BO_ 698 FR_CMR_04_40ms: 32 FR_CMR
 SG_ FR_CMR_Crc4Val : 0|16@1+ (1,0) [0|65535] "" Dummy
 SG_ FR_CMR_AlvCnt4Val : 16|8@1+ (1,0) [0|255] "" Dummy
 SG_ IFSref_FR_CMR_Sta : 24|2@1+ (1,0) [0|3] "" CGW
 SG_ IFSref_VehNumVal : 26|4@1+ (1,0) [0|15] "" CGW
 SG_ IFSref_ILLAmbtSta : 30|2@1+ (0.1,0) [0|0.3] "" CGW
 SG_ IFSref_VehLftAngl1Val : 32|9@1+ (0.1,-25) [-25|26.1] "Deg" CGW
 SG_ IFSref_VehRtAngl1Val : 41|9@1+ (0.1,-25) [-25|26.1] "Deg" CGW
 SG_ IFSref_VehLftAngl2Val : 50|9@1+ (0.1,-25) [-25|26.1] "Deg" CGW
 SG_ IFSref_VehDst1Val : 59|4@1+ (1,0) [0|15] "" CGW
 SG_ IFSref_VehRtAngl2Val : 64|9@1+ (0.1,-25) [-25|26.1] "Deg" CGW
 SG_ IFSref_VehLftAngl3Val : 73|9@1+ (0.1,-25) [-25|26.1] "Deg" CGW
 SG_ IFSref_VehRtAngl3Val : 82|9@1+ (0.1,-25) [-25|26.1] "Deg" CGW
 SG_ IFSref_VehLftAngl4Val : 91|9@1+ (0.1,-25) [-25|26.1] "Deg" CGW
 SG_ IFSref_VehRtAngl4Val : 100|9@1+ (0.1,-25) [-25|26.1] "Deg" CGW
 SG_ IFSref_VehLftAngl5Val : 109|9@1+ (0.1,-25) [-25|26.1] "Deg" CGW
 SG_ IFSref_VehRtAngl5Val : 118|9@1+ (0.1,-25) [-25|26.1] "Deg" CGW
 SG_ IFSref_VehLftAngl6Val : 128|9@1+ (0.1,-25) [-25|26.1] "Deg" CGW
 SG_ IFSref_VehRtAngl6Val : 137|9@1+ (0.1,-25) [-25|26.1] "Deg" CGW
 SG_ IFSref_VehLftAngl7Val : 146|9@1+ (0.1,-25) [-25|26.1] "Deg" CGW
 SG_ IFSref_VehRtAngl7Val : 155|9@1+ (0.1,-25) [-25|26.1] "Deg" CGW
 SG_ IFSref_VehLftAngl8Val : 164|9@1+ (0.1,-25) [-25|26.1] "Deg" CGW
 SG_ IFSref_VehRtAngl8Val : 173|9@1+ (0.1,-25) [-25|26.1] "Deg" CGW
 SG_ IFSref_VehLftAngl9Val : 182|9@1+ (0.1,-25) [-25|26.1] "Deg" CGW
 SG_ IFSref_VehRtAngl9Val : 192|9@1+ (0.1,-25) [-25|26.1] "Deg" CGW
 SG_ IFSref_VehLftAngl10Val : 201|9@1+ (0.1,-25) [-25|26.1] "Deg" CGW
 SG_ IFSref_VehRtAngl10Val : 210|9@1+ (0.1,-25) [-25|26.1] "Deg" CGW
 SG_ IFSref_VehDst2Val : 219|4@1+ (1,0) [0|15] "" CGW
 SG_ IFSref_VehDst3Val : 223|4@1+ (1,0) [0|15] "" CGW
 SG_ IFSref_VehDst4Val : 227|4@1+ (1,0) [0|15] "" CGW
 SG_ IFSref_VehDst5Val : 231|4@1+ (1,0) [0|15] "" CGW
 SG_ IFSref_VehDst6Val : 235|4@1+ (1,0) [0|15] "" CGW
 SG_ IFSref_VehDst7Val : 239|4@1+ (1,0) [0|15] "" CGW
 SG_ IFSref_VehDst8Val : 243|4@1+ (1,0) [0|15] "" CGW
 SG_ IFSref_VehDst9Val : 247|4@1+ (1,0) [0|15] "" CGW
 SG_ IFSref_VehDst10Val : 251|4@1+ (1,0) [0|15] "" CGW

BO_ 736 MANUAL_SPEED_LIMIT_ASSIST: 32 XXX
 SG_ CHECKSUM : 0|16@1+ (1,0) [0|65535] "" XXX
 SG_ COUNTER : 16|8@1+ (1,0) [0|255] "" XXX
 SG_ MSLA_STATUS : 26|2@1+ (1,0) [0|3] "" XXX
 SG_ MSLA_ENABLED : 38|1@1+ (1,0) [0|1] "" XXX
 SG_ MAX_SPEED : 55|8@0+ (1,0) [0|255] "" XXX
 SG_ MAX_SPEED_COPY : 144|8@1+ (1,0) [0|255] "" XXX

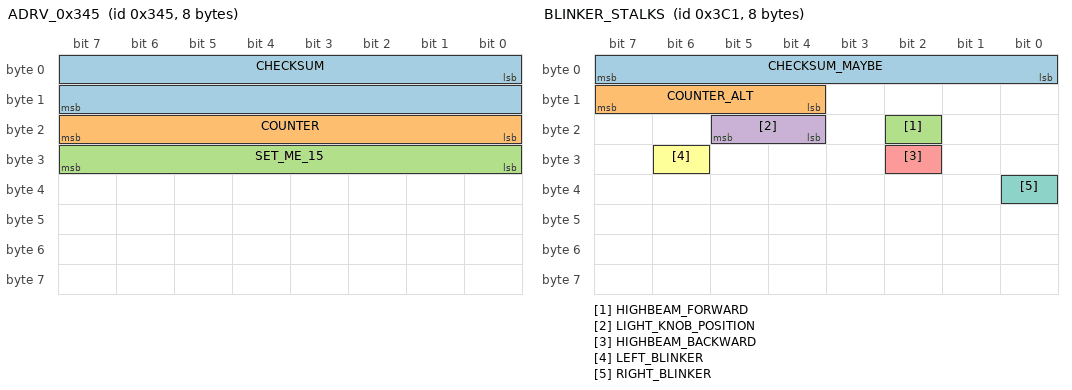
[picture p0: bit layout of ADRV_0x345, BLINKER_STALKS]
BO_ 837 ADRV_0x345: 8 ADRV
 SG_ CHECKSUM : 0|16@1+ (1,0) [0|65535] "" XXX
 SG_ COUNTER : 16|8@1+ (1,0) [0|255] "" XXX
 SG_ SET_ME_15 : 24|8@1+ (1,0) [0|255] "" XXX

BO_ 866 CAM_0x362: 32 CAMERA
 SG_ CHECKSUM : 0|16@1+ (1,0) [0|65535] "" XXX
 SG_ COUNTER : 16|8@1+ (1,0) [0|255] "" XXX
 SG_ BYTE3 : 24|8@1+ (1,0) [0|255] "" XXX
 SG_ BYTE4 : 32|8@1+ (1,0) [0|255] "" XXX
 SG_ BYTE5 : 40|8@1+ (1,0) [0|255] "" XXX
 SG_ BYTE6 : 48|8@1+ (1,0) [0|255] "" XXX
 SG_ LEFT_LANE_LINE : 56|2@1+ (1,0) [0|3] "" XXX
 SG_ SET_ME_0 : 58|2@1+ (1,0) [0|3] "" XXX
 SG_ RIGHT_LANE_LINE : 60|2@1+ (1,0) [0|3] "" XXX
 SG_ SET_ME_0_2 : 62|2@1+ (1,0) [0|3] "" XXX
 SG_ BYTE8 : 64|8@1+ (1,0) [0|255] "" XXX
 SG_ BYTE9 : 72|8@1+ (1,0) [0|255] "" XXX
 SG_ BYTE10 : 80|8@1+ (1,0) [0|255] "" XXX
 SG_ BYTE11 : 88|8@1+ (1,0) [0|255] "" XXX
 SG_ BYTE12 : 96|8@1+ (1,0) [0|255] "" XXX
 SG_ BYTE13 : 104|8@1+ (1,0) [0|255] "" XXX
 SG_ BYTE14 : 112|8@1+ (1,0) [0|255] "" XXX
 SG_ BYTE15 : 120|8@1+ (1,0) [0|255] "" XXX
 SG_ BYTE16 : 128|8@1+ (1,0) [0|255] "" XXX
 SG_ BYTE17 : 136|8@1+ (1,0) [0|255] "" XXX
 SG_ BYTE18 : 144|8@1+ (1,0) [0|255] "" XXX
 SG_ BYTE19 : 152|8@1+ (1,0) [0|255] "" XXX
 SG_ BYTE20 : 160|8@1+ (1,0) [0|255] "" XXX
 SG_ BYTE21 : 168|8@1+ (1,0) [0|255] "" XXX
 SG_ BYTE22 : 176|8@1+ (1,0) [0|255] "" XXX
 SG_ BYTE23 : 184|8@1+ (1,0) [0|255] "" XXX
 SG_ BYTE24 : 192|8@1+ (1,0) [0|255] "" XXX
 SG_ BYTE25 : 200|8@1+ (1,0) [0|255] "" XXX
 SG_ BYTE26 : 208|8@1+ (1,0) [0|255] "" XXX
 SG_ BYTE27 : 216|8@1+ (1,0) [0|255] "" XXX
 SG_ BYTE28 : 224|8@1+ (1,0) [0|255] "" XXX
 SG_ BYTE29 : 232|8@1+ (1,0) [0|255] "" XXX
 SG_ BYTE30 : 240|8@1+ (1,0) [0|255] "" XXX
 SG_ BYTE31 : 248|8@1+ (1,0) [0|255] "" XXX

BO_ 874 BLINDSPOTS_FRONT_CORNER_2: 16 XXX
 SG_ CHECKSUM : 0|16@1+ (1,0) [0|65535] "" XXX
 SG_ COUNTER : 16|8@1+ (1,0) [0|255] "" XXX

BO_ 961 BLINKER_STALKS: 8 XXX
 SG_ CHECKSUM_MAYBE : 7|8@0+ (1,0) [0|255] "" XXX
 SG_ COUNTER_ALT : 15|4@0+ (1,0) [0|15] "" XXX
 SG_ HIGHBEAM_FORWARD : 18|1@0+ (1,0) [0|1] "" XXX
 SG_ LIGHT_KNOB_POSITION : 21|2@0+ (1,0) [0|3] "" XXX
 SG_ HIGHBEAM_BACKWARD : 26|1@0+ (1,0) [0|1] "" XXX
 SG_ LEFT_BLINKER : 30|1@0+ (1,0) [0|1] "" XXX
 SG_ RIGHT_BLINKER : 32|1@0+ (1,0) [0|1] "" XXX

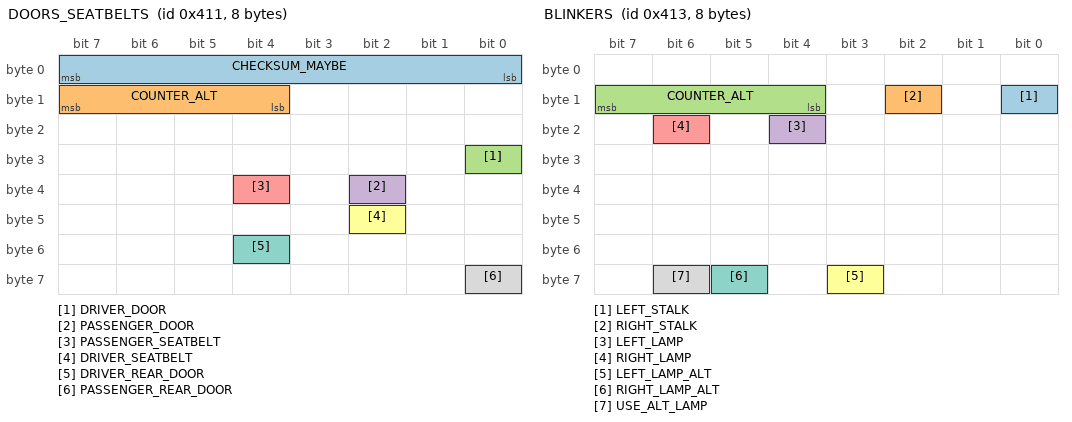
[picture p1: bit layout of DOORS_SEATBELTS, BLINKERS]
BO_ 1041 DOORS_SEATBELTS: 8 XXX
 SG_ CHECKSUM_MAYBE : 7|8@0+ (1,0) [0|65535] "" XXX
 SG_ COUNTER_ALT : 15|4@0+ (1,0) [0|15] "" XXX
 SG_ DRIVER_DOOR : 24|1@1+ (1,0) [0|1] "" XXX
 SG_ PASSENGER_DOOR : 34|1@0+ (1,0) [0|1] "" XXX
 SG_ PASSENGER_SEATBELT : 36|1@0+ (1,0) [0|1] "" XXX
 SG_ DRIVER_SEATBELT : 42|1@0+ (1,0) [0|1] "" XXX
 SG_ DRIVER_REAR_DOOR : 52|1@0+ (1,0) [0|1] "" XXX
 SG_ PASSENGER_REAR_DOOR : 56|1@0+ (1,0) [0|1] "" XXX

BO_ 1043 BLINKERS: 8 XXX
 SG_ LEFT_STALK : 8|1@0+ (1,0) [0|1] "" XXX
 SG_ RIGHT_STALK : 10|1@0+ (1,0) [0|1] "" XXX
 SG_ COUNTER_ALT : 15|4@0+ (1,0) [0|15] "" XXX
 SG_ LEFT_LAMP : 20|1@0+ (1,0) [0|1] "" XXX
 SG_ RIGHT_LAMP : 22|1@0+ (1,0) [0|1] "" XXX
 SG_ LEFT_LAMP_ALT : 59|1@0+ (1,0) [0|1] "" XXX
 SG_ RIGHT_LAMP_ALT : 61|1@0+ (1,0) [0|1] "" XXX
 SG_ USE_ALT_LAMP : 62|1@0+ (1,0) [0|1] "" XXX

BO_ 1144 DRIVE_MODE: 8 XXX
 SG_ DRIVE_MODE : 0|16@1+ (1,-61611) [0|61611] "" XXX
 SG_ DRIVE_MODE2 : 28|3@1+ (1,0) [1|3] "" XXX

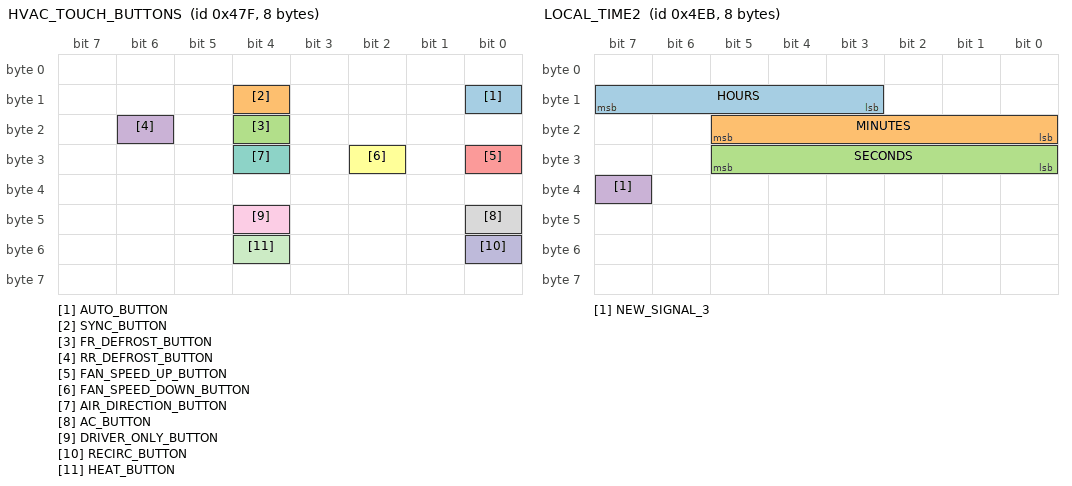
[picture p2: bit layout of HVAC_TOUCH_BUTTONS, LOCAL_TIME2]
BO_ 1151 HVAC_TOUCH_BUTTONS: 8 XXX
 SG_ AUTO_BUTTON : 8|1@0+ (1,0) [0|1] "" XXX
 SG_ SYNC_BUTTON : 12|1@0+ (1,0) [0|1] "" XXX
 SG_ FR_DEFROST_BUTTON : 20|1@0+ (1,0) [0|1] "" XXX
 SG_ RR_DEFROST_BUTTON : 22|1@0+ (1,0) [0|1] "" XXX
 SG_ FAN_SPEED_UP_BUTTON : 24|1@0+ (1,0) [0|1] "" XXX
 SG_ FAN_SPEED_DOWN_BUTTON : 26|1@0+ (1,0) [0|1] "" XXX
 SG_ AIR_DIRECTION_BUTTON : 28|1@0+ (1,0) [0|1] "" XXX
 SG_ AC_BUTTON : 40|1@0+ (1,0) [0|1] "" XXX
 SG_ DRIVER_ONLY_BUTTON : 44|1@0+ (1,0) [0|1] "" XXX
 SG_ RECIRC_BUTTON : 48|1@0+ (1,0) [0|1] "" XXX
 SG_ HEAT_BUTTON : 52|1@0+ (1,0) [0|1] "" XXX

BO_ 1240 CLUSTER_INFO: 8 XXX
 SG_ DISTANCE_UNIT : 0|1@1+ (1,0) [0|1] "" XXX

BO_ 1259 LOCAL_TIME2: 8 XXX
 SG_ HOURS : 15|5@0+ (1,0) [0|31] "" XXX
 SG_ MINUTES : 21|6@0+ (1,0) [0|63] "" XXX
 SG_ SECONDS : 24|6@1+ (1,0) [0|63] "" XXX
 SG_ NEW_SIGNAL_3 : 39|1@0+ (1,0) [0|1] "" XXX

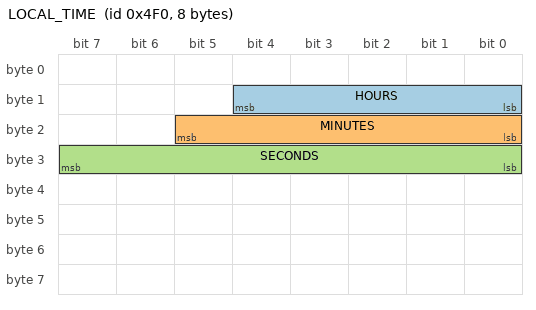
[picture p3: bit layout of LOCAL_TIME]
BO_ 1264 LOCAL_TIME: 8 XXX
 SG_ HOURS : 12|5@0+ (1,0) [0|31] "" XXX
 SG_ MINUTES : 21|6@0+ (1,0) [0|63] "" XXX
 SG_ SECONDS : 31|8@0+ (1,0) [0|59] "" XXX

CM_ SG_ 736 MAX_SPEED "Display units. Restricts car from driving above this speed unless accelerator pedal is depressed beyond pressure point";
CM_ BO_ 866 "Contains signals with detailed lane line information. Used by ADAS ECU on HDA 2 vehicles to operate LFA. Used on cars that use message 272.";
CM_ SG_ 866 LEFT_LANE_LINE "Left lane line confidence";
CM_ SG_ 866 RIGHT_LANE_LINE "Right lane line confidence";
CM_ SG_ 961 COUNTER_ALT "only increments on change";
CM_ SG_ 1041 COUNTER_ALT "only increments on change";
CM_ BO_ 1043 "Lamp signals do not seem universal on cars that use LKAS_ALT, but stalk signals do.";
CM_ SG_ 1043 COUNTER_ALT "only increments on change";
CM_ SG_ 1043 USE_ALT_LAMP "likely 1 on cars that use alt lamp signals";
VAL_ 698 IFSref_FR_CMR_Sta 0 "None Option (Default)" 1 "Normal" 2 "Blockage Status" 3 "Error Indicator";
VAL_ 698 IFSref_VehNumVal 0 "No vehicle" 1 "Number of vehicles" 2 "Number of vehicles" 3 "Number of vehicles" 4 "Number of vehicles" 5 "Number of vehicles" 6 "Number of vehicles" 7 "Number of vehicles" 8 "Number of vehicles" 9 "Number of vehicles" 10 "Number of vehicles" 11 "Over than 10 vehicles" 12 "Reserved" 13 "Reserved" 14 "Default" 15 "Error indicator";
VAL_ 698 IFSref_ILLAmbtSta 0 "Bright" 1 "Dark" 2 "Not used" 3 "Error indicator";
VAL_ 698 IFSref_VehLftAngl1Val 0 "-25.0~+25.0" 1 "-25.0~+25.0" 2 "-25.0~+25.0" 3 "-25.0~+25.0" 4 "-25.0~+25.0" 5 "-25.0~+25.0" 6 "-25.0~+25.0" 7 "-25.0~+25.0" 8 "-25.0~+25.0" 9 "-25.0~+25.0" 10 "-25.0~+25.0" 11 "-25.0~+25.0" 12 "-25.0~+25.0" 13 "-25.0~+25.0" 14 "-25.0~+25.0" 15 "-25.0~+25.0" 16 "-25.0~+25.0" 17 "-25.0~+25.0" 18 "-25.0~+25.0" 19 "-25.0~+25.0" 20 "-25.0~+25.0" 21 "-25.0~+25.0" 22 "-25.0~+25.0" 23 "-25.0~+25.0" 24 "-25.0~+25.0" 25 "-25.0~+25.0" 26 "-25.0~+25.0" 27 "-25.0~+25.0" 28 "-25.0~+25.0" 29 "-25.0~+25.0" 30 "-25.0~+25.0" 31 "-25.0~+25.0" 32 "-25.0~+25.0" 33 "-25.0~+25.0" 34 "-25.0~+25.0" 35 "-25.0~+25.0" 36 "-25.0~+25.0" 37 "-25.0~+25.0" 38 "-25.0~+25.0" 39 "-25.0~+25.0" 40 "-25.0~+25.0" 41 "-25.0~+25.0" 42 "-25.0~+25.0" 43 "-25.0~+25.0" 44 "-25.0~+25.0" 45 "-25.0~+25.0" 46 "-25.0~+25.0" 47 "-25.0~+25.0" 48 "-25.0~+25.0" 49 "-25.0~+25.0" 50 "-25.0~+25.0" 51 "-25.0~+25.0" 52 "-25.0~+25.0" 53 "-25.0~+25.0" 54 "-25.0~+25.0" 55 "-25.0~+25.0" 56 "-25.0~+25.0" 57 "-25.0~+25.0" 58 "-25.0~+25.0" 59 "-25.0~+25.0" 60 "-25.0~+25.0" 61 "-25.0~+25.0" 62 "-25.0~+25.0" 63 "-25.0~+25.0" 64 "-25.0~+25.0" 65 "-25.0~+25.0" 66 "-25.0~+25.0" 67 "-25.0~+25.0" 68 "-25.0~+25.0" 69 "-25.0~+25.0" 70 "-25.0~+25.0" 71 "-25.0~+25.0" 72 "-25.0~+25.0" 73 "-25.0~+25.0" 74 "-25.0~+25.0" 75 "-25.0~+25.0" 76 "-25.0~+25.0" 77 "-25.0~+25.0" 78 "-25.0~+25.0" 79 "-25.0~+25.0" 80 "-25.0~+25.0" 81 "-25.0~+25.0" 82 "-25.0~+25.0" 83 "-25.0~+25.0" 84 "-25.0~+25.0" 85 "-25.0~+25.0" 86 "-25.0~+25.0" 87 "-25.0~+25.0" 88 "-25.0~+25.0" 89 "-25.0~+25.0" 90 "-25.0~+25.0" 91 "-25.0~+25.0" 92 "-25.0~+25.0" 93 "-25.0~+25.0" 94 "-25.0~+25.0" 95 "-25.0~+25.0" 96 "-25.0~+25.0" 97 "-25.0~+25.0" 98 "-25.0~+25.0" 99 "-25.0~+25.0" 100 "-25.0~+25.0" 101 "-25.0~+25.0" 102 "-25.0~+25.0" 103 "-25.0~+25.0" 104 "-25.0~+25.0" 105 "-25.0~+25.0" 106 "-25.0~+25.0" 107 "-25.0~+25.0" 108 "-25.0~+25.0" 109 "-25.0~+25.0" 110 "-25.0~+25.0" 111 "-25.0~+25.0" 112 "-25.0~+25.0" 113 "-25.0~+25.0" 114 "-25.0~+25.0" 115 "-25.0~+25.0" 116 "-25.0~+25.0" 117 "-25.0~+25.0" 118 "-25.0~+25.0" 119 "-25.0~+25.0" 120 "-25.0~+25.0" 121 "-25.0~+25.0" 122 "-25.0~+25.0" 123 "-25.0~+25.0" 124 "-25.0~+25.0" 125 "-25.0~+25.0" 126 "-25.0~+25.0" 127 "-25.0~+25.0" 128 "-25.0~+25.0" 129 "-25.0~+25.0" 130 "-25.0~+25.0" 131 "-25.0~+25.0" 132 "-25.0~+25.0" 133 "-25.0~+25.0" 134 "-25.0~+25.0" 135 "-25.0~+25.0" 136 "-25.0~+25.0" 137 "-25.0~+25.0" 138 "-25.0~+25.0" 139 "-25.0~+25.0" 140 "-25.0~+25.0" 141 "-25.0~+25.0" 142 "-25.0~+25.0" 143 "-25.0~+25.0" 144 "-25.0~+25.0" 145 "-25.0~+25.0" 146 "-25.0~+25.0" 147 "-25.0~+25.0" 148 "-25.0~+25.0" 149 "-25.0~+25.0" 150 "-25.0~+25.0" 151 "-25.0~+25.0" 152 "-25.0~+25.0" 153 "-25.0~+25.0" 154 "-25.0~+25.0" 155 "-25.0~+25.0" 156 "-25.0~+25.0" 157 "-25.0~+25.0" 158 "-25.0~+25.0" 159 "-25.0~+25.0" 160 "-25.0~+25.0" 161 "-25.0~+25.0" 162 "-25.0~+25.0" 163 "-25.0~+25.0" 164 "-25.0~+25.0" 165 "-25.0~+25.0" 166 "-25.0~+25.0" 167 "-25.0~+25.0" 168 "-25.0~+25.0" 169 "-25.0~+25.0" 170 "-25.0~+25.0" 171 "-25.0~+25.0" 172 "-25.0~+25.0" 173 "-25.0~+25.0" 174 "-25.0~+25.0" 175 "-25.0~+25.0" 176 "-25.0~+25.0" 177 "-25.0~+25.0" 178 "-25.0~+25.0" 179 "-25.0~+25.0" 180 "-25.0~+25.0" 181 "-25.0~+25.0" 182 "-25.0~+25.0" 183 "-25.0~+25.0" 184 "-25.0~+25.0" 185 "-25.0~+25.0" 186 "-25.0~+25.0" 187 "-25.0~+25.0" 188 "-25.0~+25.0" 189 "-25.0~+25.0" 190 "-25.0~+25.0" 191 "-25.0~+25.0" 192 "-25.0~+25.0" 193 "-25.0~+25.0" 194 "-25.0~+25.0" 195 "-25.0~+25.0" 196 "-25.0~+25.0" 197 "-25.0~+25.0" 198 "-25.0~+25.0" 199 "-25.0~+25.0" 200 "-25.0~+25.0" 201 "-25.0~+25.0" 202 "-25.0~+25.0" 203 "-25.0~+25.0" 204 "-25.0~+25.0" 205 "-25.0~+25.0" 206 "-25.0~+25.0" 207 "-25.0~+25.0" 208 "-25.0~+25.0" 209 "-25.0~+25.0" 210 "-25.0~+25.0" 211 "-25.0~+25.0" 212 "-25.0~+25.0" 213 "-25.0~+25.0" 214 "-25.0~+25.0" 215 "-25.0~+25.0" 216 "-25.0~+25.0" 217 "-25.0~+25.0" 218 "-25.0~+25.0" 219 "-25.0~+25.0" 220 "-25.0~+25.0" 221 "-25.0~+25.0" 222 "-25.0~+25.0" 223 "-25.0~+25.0" 224 "-25.0~+25.0" 225 "-25.0~+25.0" 226 "-25.0~+25.0" 227 "-25.0~+25.0" 228 "-25.0~+25.0" 229 "-25.0~+25.0" 230 "-25.0~+25.0" 231 "-25.0~+25.0" 232 "-25.0~+25.0" 233 "-25.0~+25.0" 234 "-25.0~+25.0" 235 "-25.0~+25.0" 236 "-25.0~+25.0" 237 "-25.0~+25.0" 238 "-25.0~+25.0" 239 "-25.0~+25.0" 240 "-25.0~+25.0" 241 "-25.0~+25.0" 242 "-25.0~+25.0" 243 "-25.0~+25.0" 244 "-25.0~+25.0" 245 "-25.0~+25.0" 246 "-25.0~+25.0" 247 "-25.0~+25.0" 248 "-25.0~+25.0" 249 "-25.0~+25.0" 250 "-25.0~+25.0" 251 "-25.0~+25.0" 252 "-25.0~+25.0" 253 "-25.0~+25.0" 254 "-25.0~+25.0" 255 "-25.0~+25.0" 256 "-25.0~+25.0" 257 "-25.0~+25.0" 258 "-25.0~+25.0" 259 "-25.0~+25.0" 260 "-25.0~+25.0" 261 "-25.0~+25.0" 262 "-25.0~+25.0" 263 "-25.0~+25.0" 264 "-25.0~+25.0" 265 "-25.0~+25.0" 266 "-25.0~+25.0" 267 "-25.0~+25.0" 268 "-25.0~+25.0" 269 "-25.0~+25.0" 270 "-25.0~+25.0" 271 "-25.0~+25.0" 272 "-25.0~+25.0" 273 "-25.0~+25.0" 274 "-25.0~+25.0" 275 "-25.0~+25.0" 276 "-25.0~+25.0" 277 "-25.0~+25.0" 278 "-25.0~+25.0" 279 "-25.0~+25.0" 280 "-25.0~+25.0" 281 "-25.0~+25.0" 282 "-25.0~+25.0" 283 "-25.0~+25.0" 284 "-25.0~+25.0" 285 "-25.0~+25.0" 286 "-25.0~+25.0" 287 "-25.0~+25.0" 288 "-25.0~+25.0" 289 "-25.0~+25.0" 290 "-25.0~+25.0" 291 "-25.0~+25.0" 292 "-25.0~+25.0" 293 "-25.0~+25.0" 294 "-25.0~+25.0" 295 "-25.0~+25.0" 296 "-25.0~+25.0" 297 "-25.0~+25.0" 298 "-25.0~+25.0" 299 "-25.0~+25.0" 300 "-25.0~+25.0" 301 "-25.0~+25.0" 302 "-25.0~+25.0" 303 "-25.0~+25.0" 304 "-25.0~+25.0" 305 "-25.0~+25.0" 306 "-25.0~+25.0" 307 "-25.0~+25.0" 308 "-25.0~+25.0" 309 "-25.0~+25.0" 310 "-25.0~+25.0" 311 "-25.0~+25.0" 312 "-25.0~+25.0" 313 "-25.0~+25.0" 314 "-25.0~+25.0" 315 "-25.0~+25.0" 316 "-25.0~+25.0" 317 "-25.0~+25.0" 318 "-25.0~+25.0" 319 "-25.0~+25.0" 320 "-25.0~+25.0" 321 "-25.0~+25.0" 322 "-25.0~+25.0" 323 "-25.0~+25.0" 324 "-25.0~+25.0" 325 "-25.0~+25.0" 326 "-25.0~+25.0" 327 "-25.0~+25.0" 328 "-25.0~+25.0" 329 "-25.0~+25.0" 330 "-25.0~+25.0" 331 "-25.0~+25.0" 332 "-25.0~+25.0" 333 "-25.0~+25.0" 334 "-25.0~+25.0" 335 "-25.0~+25.0" 336 "-25.0~+25.0" 337 "-25.0~+25.0" 338 "-25.0~+25.0" 339 "-25.0~+25.0" 340 "-25.0~+25.0" 341 "-25.0~+25.0" 342 "-25.0~+25.0" 343 "-25.0~+25.0" 344 "-25.0~+25.0" 345 "-25.0~+25.0" 346 "-25.0~+25.0" 347 "-25.0~+25.0" 348 "-25.0~+25.0" 349 "-25.0~+25.0" 350 "-25.0~+25.0" 351 "-25.0~+25.0" 352 "-25.0~+25.0" 353 "-25.0~+25.0" 354 "-25.0~+25.0" 355 "-25.0~+25.0" 356 "-25.0~+25.0" 357 "-25.0~+25.0" 358 "-25.0~+25.0" 359 "-25.0~+25.0" 360 "-25.0~+25.0" 361 "-25.0~+25.0" 362 "-25.0~+25.0" 363 "-25.0~+25.0" 364 "-25.0~+25.0" 365 "-25.0~+25.0" 366 "-25.0~+25.0" 367 "-25.0~+25.0" 368 "-25.0~+25.0" 369 "-25.0~+25.0" 370 "-25.0~+25.0" 371 "-25.0~+25.0" 372 "-25.0~+25.0" 373 "-25.0~+25.0" 374 "-25.0~+25.0" 375 "-25.0~+25.0" 376 "-25.0~+25.0" 377 "-25.0~+25.0" 378 "-25.0~+25.0" 379 "-25.0~+25.0" 380 "-25.0~+25.0" 381 "-25.0~+25.0" 382 "-25.0~+25.0" 383 "-25.0~+25.0" 384 "-25.0~+25.0" 385 "-25.0~+25.0" 386 "-25.0~+25.0" 387 "-25.0~+25.0" 388 "-25.0~+25.0" 389 "-25.0~+25.0" 390 "-25.0~+25.0" 391 "-25.0~+25.0" 392 "-25.0~+25.0" 393 "-25.0~+25.0" 394 "-25.0~+25.0" 395 "-25.0~+25.0" 396 "-25.0~+25.0" 397 "-25.0~+25.0" 398 "-25.0~+25.0" 399 "-25.0~+25.0" 400 "-25.0~+25.0" 401 "-25.0~+25.0" 402 "-25.0~+25.0" 403 "-25.0~+25.0" 404 "-25.0~+25.0" 405 "-25.0~+25.0" 406 "-25.0~+25.0" 407 "-25.0~+25.0" 408 "-25.0~+25.0" 409 "-25.0~+25.0" 410 "-25.0~+25.0" 411 "-25.0~+25.0" 412 "-25.0~+25.0" 413 "-25.0~+25.0" 414 "-25.0~+25.0" 415 "-25.0~+25.0" 416 "-25.0~+25.0" 417 "-25.0~+25.0" 418 "-25.0~+25.0" 419 "-25.0~+25.0" 420 "-25.0~+25.0" 421 "-25.0~+25.0" 422 "-25.0~+25.0" 423 "-25.0~+25.0" 424 "-25.0~+25.0" 425 "-25.0~+25.0" 426 "-25.0~+25.0" 427 "-25.0~+25.0" 428 "-25.0~+25.0" 429 "-25.0~+25.0" 430 "-25.0~+25.0" 431 "-25.0~+25.0" 432 "-25.0~+25.0" 433 "-25.0~+25.0" 434 "-25.0~+25.0" 435 "-25.0~+25.0" 436 "-25.0~+25.0" 437 "-25.0~+25.0" 438 "-25.0~+25.0" 439 "-25.0~+25.0" 440 "-25.0~+25.0" 441 "-25.0~+25.0" 442 "-25.0~+25.0" 443 "-25.0~+25.0" 444 "-25.0~+25.0" 445 "-25.0~+25.0" 446 "-25.0~+25.0" 447 "-25.0~+25.0" 448 "-25.0~+25.0" 449 "-25.0~+25.0" 450 "-25.0~+25.0" 451 "-25.0~+25.0" 452 "-25.0~+25.0" 453 "-25.0~+25.0" 454 "-25.0~+25.0" 455 "-25.0~+25.0" 456 "-25.0~+25.0" 457 "-25.0~+25.0" 458 "-25.0~+25.0" 459 "-25.0~+25.0" 460 "-25.0~+25.0" 461 "-25.0~+25.0" 462 "-25.0~+25.0" 463 "-25.0~+25.0" 464 "-25.0~+25.0" 465 "-25.0~+25.0" 466 "-25.0~+25.0" 467 "-25.0~+25.0" 468 "-25.0~+25.0" 469 "-25.0~+25.0" 470 "-25.0~+25.0" 471 "-25.0~+25.0" 472 "-25.0~+25.0" 473 "-25.0~+25.0" 474 "-25.0~+25.0" 475 "-25.0~+25.0" 476 "-25.0~+25.0" 477 "-25.0~+25.0" 478 "-25.0~+25.0" 479 "-25.0~+25.0" 480 "-25.0~+25.0" 481 "-25.0~+25.0" 482 "-25.0~+25.0" 483 "-25.0~+25.0" 484 "-25.0~+25.0" 485 "-25.0~+25.0" 486 "-25.0~+25.0" 487 "-25.0~+25.0" 488 "-25.0~+25.0" 489 "-25.0~+25.0" 490 "-25.0~+25.0" 491 "-25.0~+25.0" 492 "-25.0~+25.0" 493 "-25.0~+25.0" 494 "-25.0~+25.0" 495 "-25.0~+25.0" 496 "-25.0~+25.0" 497 "-25.0~+25.0" 498 "-25.0~+25.0" 499 "-25.0~+25.0" 500 "-25.0~+25.0" 501 "Not used" 502 "Not used" 503 "Not used" 504 "Not used" 505 "Not used" 506 "Not used" 507 "Not used" 508 "Not used" 509 "Not used" 510 "Default" 511 "Error indicator";
VAL_ 698 IFSref_VehRtAngl1Val 0 "-25.0~+25.0" 1 "-25.0~+25.0" 2 "-25.0~+25.0" 3 "-25.0~+25.0" 4 "-25.0~+25.0" 5 "-25.0~+25.0" 6 "-25.0~+25.0" 7 "-25.0~+25.0" 8 "-25.0~+25.0" 9 "-25.0~+25.0" 10 "-25.0~+25.0" 11 "-25.0~+25.0" 12 "-25.0~+25.0" 13 "-25.0~+25.0" 14 "-25.0~+25.0" 15 "-25.0~+25.0" 16 "-25.0~+25.0" 17 "-25.0~+25.0" 18 "-25.0~+25.0" 19 "-25.0~+25.0" 20 "-25.0~+25.0" 21 "-25.0~+25.0" 22 "-25.0~+25.0" 23 "-25.0~+25.0" 24 "-25.0~+25.0" 25 "-25.0~+25.0" 26 "-25.0~+25.0" 27 "-25.0~+25.0" 28 "-25.0~+25.0" 29 "-25.0~+25.0" 30 "-25.0~+25.0" 31 "-25.0~+25.0" 32 "-25.0~+25.0" 33 "-25.0~+25.0" 34 "-25.0~+25.0" 35 "-25.0~+25.0" 36 "-25.0~+25.0" 37 "-25.0~+25.0" 38 "-25.0~+25.0" 39 "-25.0~+25.0" 40 "-25.0~+25.0" 41 "-25.0~+25.0" 42 "-25.0~+25.0" 43 "-25.0~+25.0" 44 "-25.0~+25.0" 45 "-25.0~+25.0" 46 "-25.0~+25.0" 47 "-25.0~+25.0" 48 "-25.0~+25.0" 49 "-25.0~+25.0" 50 "-25.0~+25.0" 51 "-25.0~+25.0" 52 "-25.0~+25.0" 53 "-25.0~+25.0" 54 "-25.0~+25.0" 55 "-25.0~+25.0" 56 "-25.0~+25.0" 57 "-25.0~+25.0" 58 "-25.0~+25.0" 59 "-25.0~+25.0" 60 "-25.0~+25.0" 61 "-25.0~+25.0" 62 "-25.0~+25.0" 63 "-25.0~+25.0" 64 "-25.0~+25.0" 65 "-25.0~+25.0" 66 "-25.0~+25.0" 67 "-25.0~+25.0" 68 "-25.0~+25.0" 69 "-25.0~+25.0" 70 "-25.0~+25.0" 71 "-25.0~+25.0" 72 "-25.0~+25.0" 73 "-25.0~+25.0" 74 "-25.0~+25.0" 75 "-25.0~+25.0" 76 "-25.0~+25.0" 77 "-25.0~+25.0" 78 "-25.0~+25.0" 79 "-25.0~+25.0" 80 "-25.0~+25.0" 81 "-25.0~+25.0" 82 "-25.0~+25.0" 83 "-25.0~+25.0" 84 "-25.0~+25.0" 85 "-25.0~+25.0" 86 "-25.0~+25.0" 87 "-25.0~+25.0" 88 "-25.0~+25.0" 89 "-25.0~+25.0" 90 "-25.0~+25.0" 91 "-25.0~+25.0" 92 "-25.0~+25.0" 93 "-25.0~+25.0" 94 "-25.0~+25.0" 95 "-25.0~+25.0" 96 "-25.0~+25.0" 97 "-25.0~+25.0" 98 "-25.0~+25.0" 99 "-25.0~+25.0" 100 "-25.0~+25.0" 101 "-25.0~+25.0" 102 "-25.0~+25.0" 103 "-25.0~+25.0" 104 "-25.0~+25.0" 105 "-25.0~+25.0" 106 "-25.0~+25.0" 107 "-25.0~+25.0" 108 "-25.0~+25.0" 109 "-25.0~+25.0" 110 "-25.0~+25.0" 111 "-25.0~+25.0" 112 "-25.0~+25.0" 113 "-25.0~+25.0" 114 "-25.0~+25.0" 115 "-25.0~+25.0" 116 "-25.0~+25.0" 117 "-25.0~+25.0" 118 "-25.0~+25.0" 119 "-25.0~+25.0" 120 "-25.0~+25.0" 121 "-25.0~+25.0" 122 "-25.0~+25.0" 123 "-25.0~+25.0" 124 "-25.0~+25.0" 125 "-25.0~+25.0" 126 "-25.0~+25.0" 127 "-25.0~+25.0" 128 "-25.0~+25.0" 129 "-25.0~+25.0" 130 "-25.0~+25.0" 131 "-25.0~+25.0" 132 "-25.0~+25.0" 133 "-25.0~+25.0" 134 "-25.0~+25.0" 135 "-25.0~+25.0" 136 "-25.0~+25.0" 137 "-25.0~+25.0" 138 "-25.0~+25.0" 139 "-25.0~+25.0" 140 "-25.0~+25.0" 141 "-25.0~+25.0" 142 "-25.0~+25.0" 143 "-25.0~+25.0" 144 "-25.0~+25.0" 145 "-25.0~+25.0" 146 "-25.0~+25.0" 147 "-25.0~+25.0" 148 "-25.0~+25.0" 149 "-25.0~+25.0" 150 "-25.0~+25.0" 151 "-25.0~+25.0" 152 "-25.0~+25.0" 153 "-25.0~+25.0" 154 "-25.0~+25.0" 155 "-25.0~+25.0" 156 "-25.0~+25.0" 157 "-25.0~+25.0" 158 "-25.0~+25.0" 159 "-25.0~+25.0" 160 "-25.0~+25.0" 161 "-25.0~+25.0" 162 "-25.0~+25.0" 163 "-25.0~+25.0" 164 "-25.0~+25.0" 165 "-25.0~+25.0" 166 "-25.0~+25.0" 167 "-25.0~+25.0" 168 "-25.0~+25.0" 169 "-25.0~+25.0" 170 "-25.0~+25.0" 171 "-25.0~+25.0" 172 "-25.0~+25.0" 173 "-25.0~+25.0" 174 "-25.0~+25.0" 175 "-25.0~+25.0" 176 "-25.0~+25.0" 177 "-25.0~+25.0" 178 "-25.0~+25.0" 179 "-25.0~+25.0" 180 "-25.0~+25.0" 181 "-25.0~+25.0" 182 "-25.0~+25.0" 183 "-25.0~+25.0" 184 "-25.0~+25.0" 185 "-25.0~+25.0" 186 "-25.0~+25.0" 187 "-25.0~+25.0" 188 "-25.0~+25.0" 189 "-25.0~+25.0" 190 "-25.0~+25.0" 191 "-25.0~+25.0" 192 "-25.0~+25.0" 193 "-25.0~+25.0" 194 "-25.0~+25.0" 195 "-25.0~+25.0" 196 "-25.0~+25.0" 197 "-25.0~+25.0" 198 "-25.0~+25.0" 199 "-25.0~+25.0" 200 "-25.0~+25.0" 201 "-25.0~+25.0" 202 "-25.0~+25.0" 203 "-25.0~+25.0" 204 "-25.0~+25.0" 205 "-25.0~+25.0" 206 "-25.0~+25.0" 207 "-25.0~+25.0" 208 "-25.0~+25.0" 209 "-25.0~+25.0" 210 "-25.0~+25.0" 211 "-25.0~+25.0" 212 "-25.0~+25.0" 213 "-25.0~+25.0" 214 "-25.0~+25.0" 215 "-25.0~+25.0" 216 "-25.0~+25.0" 217 "-25.0~+25.0" 218 "-25.0~+25.0" 219 "-25.0~+25.0" 220 "-25.0~+25.0" 221 "-25.0~+25.0" 222 "-25.0~+25.0" 223 "-25.0~+25.0" 224 "-25.0~+25.0" 225 "-25.0~+25.0" 226 "-25.0~+25.0" 227 "-25.0~+25.0" 228 "-25.0~+25.0" 229 "-25.0~+25.0" 230 "-25.0~+25.0" 231 "-25.0~+25.0" 232 "-25.0~+25.0" 233 "-25.0~+25.0" 234 "-25.0~+25.0" 235 "-25.0~+25.0" 236 "-25.0~+25.0" 237 "-25.0~+25.0" 238 "-25.0~+25.0" 239 "-25.0~+25.0" 240 "-25.0~+25.0" 241 "-25.0~+25.0" 242 "-25.0~+25.0" 243 "-25.0~+25.0" 244 "-25.0~+25.0" 245 "-25.0~+25.0" 246 "-25.0~+25.0" 247 "-25.0~+25.0" 248 "-25.0~+25.0" 249 "-25.0~+25.0" 250 "-25.0~+25.0" 251 "-25.0~+25.0" 252 "-25.0~+25.0" 253 "-25.0~+25.0" 254 "-25.0~+25.0" 255 "-25.0~+25.0" 256 "-25.0~+25.0" 257 "-25.0~+25.0" 258 "-25.0~+25.0" 259 "-25.0~+25.0" 260 "-25.0~+25.0" 261 "-25.0~+25.0" 262 "-25.0~+25.0" 263 "-25.0~+25.0" 264 "-25.0~+25.0" 265 "-25.0~+25.0" 266 "-25.0~+25.0" 267 "-25.0~+25.0" 268 "-25.0~+25.0" 269 "-25.0~+25.0" 270 "-25.0~+25.0" 271 "-25.0~+25.0" 272 "-25.0~+25.0" 273 "-25.0~+25.0" 274 "-25.0~+25.0" 275 "-25.0~+25.0" 276 "-25.0~+25.0" 277 "-25.0~+25.0" 278 "-25.0~+25.0" 279 "-25.0~+25.0" 280 "-25.0~+25.0" 281 "-25.0~+25.0" 282 "-25.0~+25.0" 283 "-25.0~+25.0" 284 "-25.0~+25.0" 285 "-25.0~+25.0" 286 "-25.0~+25.0" 287 "-25.0~+25.0" 288 "-25.0~+25.0" 289 "-25.0~+25.0" 290 "-25.0~+25.0" 291 "-25.0~+25.0" 292 "-25.0~+25.0" 293 "-25.0~+25.0" 294 "-25.0~+25.0" 295 "-25.0~+25.0" 296 "-25.0~+25.0" 297 "-25.0~+25.0" 298 "-25.0~+25.0" 299 "-25.0~+25.0" 300 "-25.0~+25.0" 301 "-25.0~+25.0" 302 "-25.0~+25.0" 303 "-25.0~+25.0" 304 "-25.0~+25.0" 305 "-25.0~+25.0" 306 "-25.0~+25.0" 307 "-25.0~+25.0" 308 "-25.0~+25.0" 309 "-25.0~+25.0" 310 "-25.0~+25.0" 311 "-25.0~+25.0" 312 "-25.0~+25.0" 313 "-25.0~+25.0" 314 "-25.0~+25.0" 315 "-25.0~+25.0" 316 "-25.0~+25.0" 317 "-25.0~+25.0" 318 "-25.0~+25.0" 319 "-25.0~+25.0" 320 "-25.0~+25.0" 321 "-25.0~+25.0" 322 "-25.0~+25.0" 323 "-25.0~+25.0" 324 "-25.0~+25.0" 325 "-25.0~+25.0" 326 "-25.0~+25.0" 327 "-25.0~+25.0" 328 "-25.0~+25.0" 329 "-25.0~+25.0" 330 "-25.0~+25.0" 331 "-25.0~+25.0" 332 "-25.0~+25.0" 333 "-25.0~+25.0" 334 "-25.0~+25.0" 335 "-25.0~+25.0" 336 "-25.0~+25.0" 337 "-25.0~+25.0" 338 "-25.0~+25.0" 339 "-25.0~+25.0" 340 "-25.0~+25.0" 341 "-25.0~+25.0" 342 "-25.0~+25.0" 343 "-25.0~+25.0" 344 "-25.0~+25.0" 345 "-25.0~+25.0" 346 "-25.0~+25.0" 347 "-25.0~+25.0" 348 "-25.0~+25.0" 349 "-25.0~+25.0" 350 "-25.0~+25.0" 351 "-25.0~+25.0" 352 "-25.0~+25.0" 353 "-25.0~+25.0" 354 "-25.0~+25.0" 355 "-25.0~+25.0" 356 "-25.0~+25.0" 357 "-25.0~+25.0" 358 "-25.0~+25.0" 359 "-25.0~+25.0" 360 "-25.0~+25.0" 361 "-25.0~+25.0" 362 "-25.0~+25.0" 363 "-25.0~+25.0" 364 "-25.0~+25.0" 365 "-25.0~+25.0" 366 "-25.0~+25.0" 367 "-25.0~+25.0" 368 "-25.0~+25.0" 369 "-25.0~+25.0" 370 "-25.0~+25.0" 371 "-25.0~+25.0" 372 "-25.0~+25.0" 373 "-25.0~+25.0" 374 "-25.0~+25.0" 375 "-25.0~+25.0" 376 "-25.0~+25.0" 377 "-25.0~+25.0" 378 "-25.0~+25.0" 379 "-25.0~+25.0" 380 "-25.0~+25.0" 381 "-25.0~+25.0" 382 "-25.0~+25.0" 383 "-25.0~+25.0" 384 "-25.0~+25.0" 385 "-25.0~+25.0" 386 "-25.0~+25.0" 387 "-25.0~+25.0" 388 "-25.0~+25.0" 389 "-25.0~+25.0" 390 "-25.0~+25.0" 391 "-25.0~+25.0" 392 "-25.0~+25.0" 393 "-25.0~+25.0" 394 "-25.0~+25.0" 395 "-25.0~+25.0" 396 "-25.0~+25.0" 397 "-25.0~+25.0" 398 "-25.0~+25.0" 399 "-25.0~+25.0" 400 "-25.0~+25.0" 401 "-25.0~+25.0" 402 "-25.0~+25.0" 403 "-25.0~+25.0" 404 "-25.0~+25.0" 405 "-25.0~+25.0" 406 "-25.0~+25.0" 407 "-25.0~+25.0" 408 "-25.0~+25.0" 409 "-25.0~+25.0" 410 "-25.0~+25.0" 411 "-25.0~+25.0" 412 "-25.0~+25.0" 413 "-25.0~+25.0" 414 "-25.0~+25.0" 415 "-25.0~+25.0" 416 "-25.0~+25.0" 417 "-25.0~+25.0" 418 "-25.0~+25.0" 419 "-25.0~+25.0" 420 "-25.0~+25.0" 421 "-25.0~+25.0" 422 "-25.0~+25.0" 423 "-25.0~+25.0" 424 "-25.0~+25.0" 425 "-25.0~+25.0" 426 "-25.0~+25.0" 427 "-25.0~+25.0" 428 "-25.0~+25.0" 429 "-25.0~+25.0" 430 "-25.0~+25.0" 431 "-25.0~+25.0" 432 "-25.0~+25.0" 433 "-25.0~+25.0" 434 "-25.0~+25.0" 435 "-25.0~+25.0" 436 "-25.0~+25.0" 437 "-25.0~+25.0" 438 "-25.0~+25.0" 439 "-25.0~+25.0" 440 "-25.0~+25.0" 441 "-25.0~+25.0" 442 "-25.0~+25.0" 443 "-25.0~+25.0" 444 "-25.0~+25.0" 445 "-25.0~+25.0" 446 "-25.0~+25.0" 447 "-25.0~+25.0" 448 "-25.0~+25.0" 449 "-25.0~+25.0" 450 "-25.0~+25.0" 451 "-25.0~+25.0" 452 "-25.0~+25.0" 453 "-25.0~+25.0" 454 "-25.0~+25.0" 455 "-25.0~+25.0" 456 "-25.0~+25.0" 457 "-25.0~+25.0" 458 "-25.0~+25.0" 459 "-25.0~+25.0" 460 "-25.0~+25.0" 461 "-25.0~+25.0" 462 "-25.0~+25.0" 463 "-25.0~+25.0" 464 "-25.0~+25.0" 465 "-25.0~+25.0" 466 "-25.0~+25.0" 467 "-25.0~+25.0" 468 "-25.0~+25.0" 469 "-25.0~+25.0" 470 "-25.0~+25.0" 471 "-25.0~+25.0" 472 "-25.0~+25.0" 473 "-25.0~+25.0" 474 "-25.0~+25.0" 475 "-25.0~+25.0" 476 "-25.0~+25.0" 477 "-25.0~+25.0" 478 "-25.0~+25.0" 479 "-25.0~+25.0" 480 "-25.0~+25.0" 481 "-25.0~+25.0" 482 "-25.0~+25.0" 483 "-25.0~+25.0" 484 "-25.0~+25.0" 485 "-25.0~+25.0" 486 "-25.0~+25.0" 487 "-25.0~+25.0" 488 "-25.0~+25.0" 489 "-25.0~+25.0" 490 "-25.0~+25.0" 491 "-25.0~+25.0" 492 "-25.0~+25.0" 493 "-25.0~+25.0" 494 "-25.0~+25.0" 495 "-25.0~+25.0" 496 "-25.0~+25.0" 497 "-25.0~+25.0" 498 "-25.0~+25.0" 499 "-25.0~+25.0" 500 "-25.0~+25.0" 501 "Not used" 502 "Not used" 503 "Not used" 504 "Not used" 505 "Not used" 506 "Not used" 507 "Not used" 508 "Not used" 509 "Not used" 510 "Default" 511 "Error indicator";
VAL_ 698 IFSref_VehLftAngl2Val 0 "-25.0~+25.0" 1 "-25.0~+25.0" 2 "-25.0~+25.0" 3 "-25.0~+25.0" 4 "-25.0~+25.0" 5 "-25.0~+25.0" 6 "-25.0~+25.0" 7 "-25.0~+25.0" 8 "-25.0~+25.0" 9 "-25.0~+25.0" 10 "-25.0~+25.0" 11 "-25.0~+25.0" 12 "-25.0~+25.0" 13 "-25.0~+25.0" 14 "-25.0~+25.0" 15 "-25.0~+25.0" 16 "-25.0~+25.0" 17 "-25.0~+25.0" 18 "-25.0~+25.0" 19 "-25.0~+25.0" 20 "-25.0~+25.0" 21 "-25.0~+25.0" 22 "-25.0~+25.0" 23 "-25.0~+25.0" 24 "-25.0~+25.0" 25 "-25.0~+25.0" 26 "-25.0~+25.0" 27 "-25.0~+25.0" 28 "-25.0~+25.0" 29 "-25.0~+25.0" 30 "-25.0~+25.0" 31 "-25.0~+25.0" 32 "-25.0~+25.0" 33 "-25.0~+25.0" 34 "-25.0~+25.0" 35 "-25.0~+25.0" 36 "-25.0~+25.0" 37 "-25.0~+25.0" 38 "-25.0~+25.0" 39 "-25.0~+25.0" 40 "-25.0~+25.0" 41 "-25.0~+25.0" 42 "-25.0~+25.0" 43 "-25.0~+25.0" 44 "-25.0~+25.0" 45 "-25.0~+25.0" 46 "-25.0~+25.0" 47 "-25.0~+25.0" 48 "-25.0~+25.0" 49 "-25.0~+25.0" 50 "-25.0~+25.0" 51 "-25.0~+25.0" 52 "-25.0~+25.0" 53 "-25.0~+25.0" 54 "-25.0~+25.0" 55 "-25.0~+25.0" 56 "-25.0~+25.0" 57 "-25.0~+25.0" 58 "-25.0~+25.0" 59 "-25.0~+25.0" 60 "-25.0~+25.0" 61 "-25.0~+25.0" 62 "-25.0~+25.0" 63 "-25.0~+25.0" 64 "-25.0~+25.0" 65 "-25.0~+25.0" 66 "-25.0~+25.0" 67 "-25.0~+25.0" 68 "-25.0~+25.0" 69 "-25.0~+25.0" 70 "-25.0~+25.0" 71 "-25.0~+25.0" 72 "-25.0~+25.0" 73 "-25.0~+25.0" 74 "-25.0~+25.0" 75 "-25.0~+25.0" 76 "-25.0~+25.0" 77 "-25.0~+25.0" 78 "-25.0~+25.0" 79 "-25.0~+25.0" 80 "-25.0~+25.0" 81 "-25.0~+25.0" 82 "-25.0~+25.0" 83 "-25.0~+25.0" 84 "-25.0~+25.0" 85 "-25.0~+25.0" 86 "-25.0~+25.0" 87 "-25.0~+25.0" 88 "-25.0~+25.0" 89 "-25.0~+25.0" 90 "-25.0~+25.0" 91 "-25.0~+25.0" 92 "-25.0~+25.0" 93 "-25.0~+25.0" 94 "-25.0~+25.0" 95 "-25.0~+25.0" 96 "-25.0~+25.0" 97 "-25.0~+25.0" 98 "-25.0~+25.0" 99 "-25.0~+25.0" 100 "-25.0~+25.0" 101 "-25.0~+25.0" 102 "-25.0~+25.0" 103 "-25.0~+25.0" 104 "-25.0~+25.0" 105 "-25.0~+25.0" 106 "-25.0~+25.0" 107 "-25.0~+25.0" 108 "-25.0~+25.0" 109 "-25.0~+25.0" 110 "-25.0~+25.0" 111 "-25.0~+25.0" 112 "-25.0~+25.0" 113 "-25.0~+25.0" 114 "-25.0~+25.0" 115 "-25.0~+25.0" 116 "-25.0~+25.0" 117 "-25.0~+25.0" 118 "-25.0~+25.0" 119 "-25.0~+25.0" 120 "-25.0~+25.0" 121 "-25.0~+25.0" 122 "-25.0~+25.0" 123 "-25.0~+25.0" 124 "-25.0~+25.0" 125 "-25.0~+25.0" 126 "-25.0~+25.0" 127 "-25.0~+25.0" 128 "-25.0~+25.0" 129 "-25.0~+25.0" 130 "-25.0~+25.0" 131 "-25.0~+25.0" 132 "-25.0~+25.0" 133 "-25.0~+25.0" 134 "-25.0~+25.0" 135 "-25.0~+25.0" 136 "-25.0~+25.0" 137 "-25.0~+25.0" 138 "-25.0~+25.0" 139 "-25.0~+25.0" 140 "-25.0~+25.0" 141 "-25.0~+25.0" 142 "-25.0~+25.0" 143 "-25.0~+25.0" 144 "-25.0~+25.0" 145 "-25.0~+25.0" 146 "-25.0~+25.0" 147 "-25.0~+25.0" 148 "-25.0~+25.0" 149 "-25.0~+25.0" 150 "-25.0~+25.0" 151 "-25.0~+25.0" 152 "-25.0~+25.0" 153 "-25.0~+25.0" 154 "-25.0~+25.0" 155 "-25.0~+25.0" 156 "-25.0~+25.0" 157 "-25.0~+25.0" 158 "-25.0~+25.0" 159 "-25.0~+25.0" 160 "-25.0~+25.0" 161 "-25.0~+25.0" 162 "-25.0~+25.0" 163 "-25.0~+25.0" 164 "-25.0~+25.0" 165 "-25.0~+25.0" 166 "-25.0~+25.0" 167 "-25.0~+25.0" 168 "-25.0~+25.0" 169 "-25.0~+25.0" 170 "-25.0~+25.0" 171 "-25.0~+25.0" 172 "-25.0~+25.0" 173 "-25.0~+25.0" 174 "-25.0~+25.0" 175 "-25.0~+25.0" 176 "-25.0~+25.0" 177 "-25.0~+25.0" 178 "-25.0~+25.0" 179 "-25.0~+25.0" 180 "-25.0~+25.0" 181 "-25.0~+25.0" 182 "-25.0~+25.0" 183 "-25.0~+25.0" 184 "-25.0~+25.0" 185 "-25.0~+25.0" 186 "-25.0~+25.0" 187 "-25.0~+25.0" 188 "-25.0~+25.0" 189 "-25.0~+25.0" 190 "-25.0~+25.0" 191 "-25.0~+25.0" 192 "-25.0~+25.0" 193 "-25.0~+25.0" 194 "-25.0~+25.0" 195 "-25.0~+25.0" 196 "-25.0~+25.0" 197 "-25.0~+25.0" 198 "-25.0~+25.0" 199 "-25.0~+25.0" 200 "-25.0~+25.0" 201 "-25.0~+25.0" 202 "-25.0~+25.0" 203 "-25.0~+25.0" 204 "-25.0~+25.0" 205 "-25.0~+25.0" 206 "-25.0~+25.0" 207 "-25.0~+25.0" 208 "-25.0~+25.0" 209 "-25.0~+25.0" 210 "-25.0~+25.0" 211 "-25.0~+25.0" 212 "-25.0~+25.0" 213 "-25.0~+25.0" 214 "-25.0~+25.0" 215 "-25.0~+25.0" 216 "-25.0~+25.0" 217 "-25.0~+25.0" 218 "-25.0~+25.0" 219 "-25.0~+25.0" 220 "-25.0~+25.0" 221 "-25.0~+25.0" 222 "-25.0~+25.0" 223 "-25.0~+25.0" 224 "-25.0~+25.0" 225 "-25.0~+25.0" 226 "-25.0~+25.0" 227 "-25.0~+25.0" 228 "-25.0~+25.0" 229 "-25.0~+25.0" 230 "-25.0~+25.0" 231 "-25.0~+25.0" 232 "-25.0~+25.0" 233 "-25.0~+25.0" 234 "-25.0~+25.0" 235 "-25.0~+25.0" 236 "-25.0~+25.0" 237 "-25.0~+25.0" 238 "-25.0~+25.0" 239 "-25.0~+25.0" 240 "-25.0~+25.0" 241 "-25.0~+25.0" 242 "-25.0~+25.0" 243 "-25.0~+25.0" 244 "-25.0~+25.0" 245 "-25.0~+25.0" 246 "-25.0~+25.0" 247 "-25.0~+25.0" 248 "-25.0~+25.0" 249 "-25.0~+25.0" 250 "-25.0~+25.0" 251 "-25.0~+25.0" 252 "-25.0~+25.0" 253 "-25.0~+25.0" 254 "-25.0~+25.0" 255 "-25.0~+25.0" 256 "-25.0~+25.0" 257 "-25.0~+25.0" 258 "-25.0~+25.0" 259 "-25.0~+25.0" 260 "-25.0~+25.0" 261 "-25.0~+25.0" 262 "-25.0~+25.0" 263 "-25.0~+25.0" 264 "-25.0~+25.0" 265 "-25.0~+25.0" 266 "-25.0~+25.0" 267 "-25.0~+25.0" 268 "-25.0~+25.0" 269 "-25.0~+25.0" 270 "-25.0~+25.0" 271 "-25.0~+25.0" 272 "-25.0~+25.0" 273 "-25.0~+25.0" 274 "-25.0~+25.0" 275 "-25.0~+25.0" 276 "-25.0~+25.0" 277 "-25.0~+25.0" 278 "-25.0~+25.0" 279 "-25.0~+25.0" 280 "-25.0~+25.0" 281 "-25.0~+25.0" 282 "-25.0~+25.0" 283 "-25.0~+25.0" 284 "-25.0~+25.0" 285 "-25.0~+25.0" 286 "-25.0~+25.0" 287 "-25.0~+25.0" 288 "-25.0~+25.0" 289 "-25.0~+25.0" 290 "-25.0~+25.0" 291 "-25.0~+25.0" 292 "-25.0~+25.0" 293 "-25.0~+25.0" 294 "-25.0~+25.0" 295 "-25.0~+25.0" 296 "-25.0~+25.0" 297 "-25.0~+25.0" 298 "-25.0~+25.0" 299 "-25.0~+25.0" 300 "-25.0~+25.0" 301 "-25.0~+25.0" 302 "-25.0~+25.0" 303 "-25.0~+25.0" 304 "-25.0~+25.0" 305 "-25.0~+25.0" 306 "-25.0~+25.0" 307 "-25.0~+25.0" 308 "-25.0~+25.0" 309 "-25.0~+25.0" 310 "-25.0~+25.0" 311 "-25.0~+25.0" 312 "-25.0~+25.0" 313 "-25.0~+25.0" 314 "-25.0~+25.0" 315 "-25.0~+25.0" 316 "-25.0~+25.0" 317 "-25.0~+25.0" 318 "-25.0~+25.0" 319 "-25.0~+25.0" 320 "-25.0~+25.0" 321 "-25.0~+25.0" 322 "-25.0~+25.0" 323 "-25.0~+25.0" 324 "-25.0~+25.0" 325 "-25.0~+25.0" 326 "-25.0~+25.0" 327 "-25.0~+25.0" 328 "-25.0~+25.0" 329 "-25.0~+25.0" 330 "-25.0~+25.0" 331 "-25.0~+25.0" 332 "-25.0~+25.0" 333 "-25.0~+25.0" 334 "-25.0~+25.0" 335 "-25.0~+25.0" 336 "-25.0~+25.0" 337 "-25.0~+25.0" 338 "-25.0~+25.0" 339 "-25.0~+25.0" 340 "-25.0~+25.0" 341 "-25.0~+25.0" 342 "-25.0~+25.0" 343 "-25.0~+25.0" 344 "-25.0~+25.0" 345 "-25.0~+25.0" 346 "-25.0~+25.0" 347 "-25.0~+25.0" 348 "-25.0~+25.0" 349 "-25.0~+25.0" 350 "-25.0~+25.0" 351 "-25.0~+25.0" 352 "-25.0~+25.0" 353 "-25.0~+25.0" 354 "-25.0~+25.0" 355 "-25.0~+25.0" 356 "-25.0~+25.0" 357 "-25.0~+25.0" 358 "-25.0~+25.0" 359 "-25.0~+25.0" 360 "-25.0~+25.0" 361 "-25.0~+25.0" 362 "-25.0~+25.0" 363 "-25.0~+25.0" 364 "-25.0~+25.0" 365 "-25.0~+25.0" 366 "-25.0~+25.0" 367 "-25.0~+25.0" 368 "-25.0~+25.0" 369 "-25.0~+25.0" 370 "-25.0~+25.0" 371 "-25.0~+25.0" 372 "-25.0~+25.0" 373 "-25.0~+25.0" 374 "-25.0~+25.0" 375 "-25.0~+25.0" 376 "-25.0~+25.0" 377 "-25.0~+25.0" 378 "-25.0~+25.0" 379 "-25.0~+25.0" 380 "-25.0~+25.0" 381 "-25.0~+25.0" 382 "-25.0~+25.0" 383 "-25.0~+25.0" 384 "-25.0~+25.0" 385 "-25.0~+25.0" 386 "-25.0~+25.0" 387 "-25.0~+25.0" 388 "-25.0~+25.0" 389 "-25.0~+25.0" 390 "-25.0~+25.0" 391 "-25.0~+25.0" 392 "-25.0~+25.0" 393 "-25.0~+25.0" 394 "-25.0~+25.0" 395 "-25.0~+25.0" 396 "-25.0~+25.0" 397 "-25.0~+25.0" 398 "-25.0~+25.0" 399 "-25.0~+25.0" 400 "-25.0~+25.0" 401 "-25.0~+25.0" 402 "-25.0~+25.0" 403 "-25.0~+25.0" 404 "-25.0~+25.0" 405 "-25.0~+25.0" 406 "-25.0~+25.0" 407 "-25.0~+25.0" 408 "-25.0~+25.0" 409 "-25.0~+25.0" 410 "-25.0~+25.0" 411 "-25.0~+25.0" 412 "-25.0~+25.0" 413 "-25.0~+25.0" 414 "-25.0~+25.0" 415 "-25.0~+25.0" 416 "-25.0~+25.0" 417 "-25.0~+25.0" 418 "-25.0~+25.0" 419 "-25.0~+25.0" 420 "-25.0~+25.0" 421 "-25.0~+25.0" 422 "-25.0~+25.0" 423 "-25.0~+25.0" 424 "-25.0~+25.0" 425 "-25.0~+25.0" 426 "-25.0~+25.0" 427 "-25.0~+25.0" 428 "-25.0~+25.0" 429 "-25.0~+25.0" 430 "-25.0~+25.0" 431 "-25.0~+25.0" 432 "-25.0~+25.0" 433 "-25.0~+25.0" 434 "-25.0~+25.0" 435 "-25.0~+25.0" 436 "-25.0~+25.0" 437 "-25.0~+25.0" 438 "-25.0~+25.0" 439 "-25.0~+25.0" 440 "-25.0~+25.0" 441 "-25.0~+25.0" 442 "-25.0~+25.0" 443 "-25.0~+25.0" 444 "-25.0~+25.0" 445 "-25.0~+25.0" 446 "-25.0~+25.0" 447 "-25.0~+25.0" 448 "-25.0~+25.0" 449 "-25.0~+25.0" 450 "-25.0~+25.0" 451 "-25.0~+25.0" 452 "-25.0~+25.0" 453 "-25.0~+25.0" 454 "-25.0~+25.0" 455 "-25.0~+25.0" 456 "-25.0~+25.0" 457 "-25.0~+25.0" 458 "-25.0~+25.0" 459 "-25.0~+25.0" 460 "-25.0~+25.0" 461 "-25.0~+25.0" 462 "-25.0~+25.0" 463 "-25.0~+25.0" 464 "-25.0~+25.0" 465 "-25.0~+25.0" 466 "-25.0~+25.0" 467 "-25.0~+25.0" 468 "-25.0~+25.0" 469 "-25.0~+25.0" 470 "-25.0~+25.0" 471 "-25.0~+25.0" 472 "-25.0~+25.0" 473 "-25.0~+25.0" 474 "-25.0~+25.0" 475 "-25.0~+25.0" 476 "-25.0~+25.0" 477 "-25.0~+25.0" 478 "-25.0~+25.0" 479 "-25.0~+25.0" 480 "-25.0~+25.0" 481 "-25.0~+25.0" 482 "-25.0~+25.0" 483 "-25.0~+25.0" 484 "-25.0~+25.0" 485 "-25.0~+25.0" 486 "-25.0~+25.0" 487 "-25.0~+25.0" 488 "-25.0~+25.0" 489 "-25.0~+25.0" 490 "-25.0~+25.0" 491 "-25.0~+25.0" 492 "-25.0~+25.0" 493 "-25.0~+25.0" 494 "-25.0~+25.0" 495 "-25.0~+25.0" 496 "-25.0~+25.0" 497 "-25.0~+25.0" 498 "-25.0~+25.0" 499 "-25.0~+25.0" 500 "-25.0~+25.0" 501 "Not used" 502 "Not used" 503 "Not used" 504 "Not used" 505 "Not used" 506 "Not used" 507 "Not used" 508 "Not used" 509 "Not used" 510 "Default" 511 "Error indicator";
VAL_ 698 IFSref_VehDst1Val 0 "No Value" 1 "1~10m" 2 "11~20m" 3 "21~30m" 4 "31~40m" 5 "41~50m" 6 "51~60m" 7 "61~70m" 8 "71~80m" 9 "81~90m" 10 "91~100m" 11 "101~200m" 12 "201~300m" 13 "301~400m" 14 "401m~" 15 "Error indicator";
VAL_ 698 IFSref_VehRtAngl2Val 0 "-25.0~+25.0" 1 "-25.0~+25.0" 2 "-25.0~+25.0" 3 "-25.0~+25.0" 4 "-25.0~+25.0" 5 "-25.0~+25.0" 6 "-25.0~+25.0" 7 "-25.0~+25.0" 8 "-25.0~+25.0" 9 "-25.0~+25.0" 10 "-25.0~+25.0" 11 "-25.0~+25.0" 12 "-25.0~+25.0" 13 "-25.0~+25.0" 14 "-25.0~+25.0" 15 "-25.0~+25.0" 16 "-25.0~+25.0" 17 "-25.0~+25.0" 18 "-25.0~+25.0" 19 "-25.0~+25.0" 20 "-25.0~+25.0" 21 "-25.0~+25.0" 22 "-25.0~+25.0" 23 "-25.0~+25.0" 24 "-25.0~+25.0" 25 "-25.0~+25.0" 26 "-25.0~+25.0" 27 "-25.0~+25.0" 28 "-25.0~+25.0" 29 "-25.0~+25.0" 30 "-25.0~+25.0" 31 "-25.0~+25.0" 32 "-25.0~+25.0" 33 "-25.0~+25.0" 34 "-25.0~+25.0" 35 "-25.0~+25.0" 36 "-25.0~+25.0" 37 "-25.0~+25.0" 38 "-25.0~+25.0" 39 "-25.0~+25.0" 40 "-25.0~+25.0" 41 "-25.0~+25.0" 42 "-25.0~+25.0" 43 "-25.0~+25.0" 44 "-25.0~+25.0" 45 "-25.0~+25.0" 46 "-25.0~+25.0" 47 "-25.0~+25.0" 48 "-25.0~+25.0" 49 "-25.0~+25.0" 50 "-25.0~+25.0" 51 "-25.0~+25.0" 52 "-25.0~+25.0" 53 "-25.0~+25.0" 54 "-25.0~+25.0" 55 "-25.0~+25.0" 56 "-25.0~+25.0" 57 "-25.0~+25.0" 58 "-25.0~+25.0" 59 "-25.0~+25.0" 60 "-25.0~+25.0" 61 "-25.0~+25.0" 62 "-25.0~+25.0" 63 "-25.0~+25.0" 64 "-25.0~+25.0" 65 "-25.0~+25.0" 66 "-25.0~+25.0" 67 "-25.0~+25.0" 68 "-25.0~+25.0" 69 "-25.0~+25.0" 70 "-25.0~+25.0" 71 "-25.0~+25.0" 72 "-25.0~+25.0" 73 "-25.0~+25.0" 74 "-25.0~+25.0" 75 "-25.0~+25.0" 76 "-25.0~+25.0" 77 "-25.0~+25.0" 78 "-25.0~+25.0" 79 "-25.0~+25.0" 80 "-25.0~+25.0" 81 "-25.0~+25.0" 82 "-25.0~+25.0" 83 "-25.0~+25.0" 84 "-25.0~+25.0" 85 "-25.0~+25.0" 86 "-25.0~+25.0" 87 "-25.0~+25.0" 88 "-25.0~+25.0" 89 "-25.0~+25.0" 90 "-25.0~+25.0" 91 "-25.0~+25.0" 92 "-25.0~+25.0" 93 "-25.0~+25.0" 94 "-25.0~+25.0" 95 "-25.0~+25.0" 96 "-25.0~+25.0" 97 "-25.0~+25.0" 98 "-25.0~+25.0" 99 "-25.0~+25.0" 100 "-25.0~+25.0" 101 "-25.0~+25.0" 102 "-25.0~+25.0" 103 "-25.0~+25.0" 104 "-25.0~+25.0" 105 "-25.0~+25.0" 106 "-25.0~+25.0" 107 "-25.0~+25.0" 108 "-25.0~+25.0" 109 "-25.0~+25.0" 110 "-25.0~+25.0" 111 "-25.0~+25.0" 112 "-25.0~+25.0" 113 "-25.0~+25.0" 114 "-25.0~+25.0" 115 "-25.0~+25.0" 116 "-25.0~+25.0" 117 "-25.0~+25.0" 118 "-25.0~+25.0" 119 "-25.0~+25.0" 120 "-25.0~+25.0" 121 "-25.0~+25.0" 122 "-25.0~+25.0" 123 "-25.0~+25.0" 124 "-25.0~+25.0" 125 "-25.0~+25.0" 126 "-25.0~+25.0" 127 "-25.0~+25.0" 128 "-25.0~+25.0" 129 "-25.0~+25.0" 130 "-25.0~+25.0" 131 "-25.0~+25.0" 132 "-25.0~+25.0" 133 "-25.0~+25.0" 134 "-25.0~+25.0" 135 "-25.0~+25.0" 136 "-25.0~+25.0" 137 "-25.0~+25.0" 138 "-25.0~+25.0" 139 "-25.0~+25.0" 140 "-25.0~+25.0" 141 "-25.0~+25.0" 142 "-25.0~+25.0" 143 "-25.0~+25.0" 144 "-25.0~+25.0" 145 "-25.0~+25.0" 146 "-25.0~+25.0" 147 "-25.0~+25.0" 148 "-25.0~+25.0" 149 "-25.0~+25.0" 150 "-25.0~+25.0" 151 "-25.0~+25.0" 152 "-25.0~+25.0" 153 "-25.0~+25.0" 154 "-25.0~+25.0" 155 "-25.0~+25.0" 156 "-25.0~+25.0" 157 "-25.0~+25.0" 158 "-25.0~+25.0" 159 "-25.0~+25.0" 160 "-25.0~+25.0" 161 "-25.0~+25.0" 162 "-25.0~+25.0" 163 "-25.0~+25.0" 164 "-25.0~+25.0" 165 "-25.0~+25.0" 166 "-25.0~+25.0" 167 "-25.0~+25.0" 168 "-25.0~+25.0" 169 "-25.0~+25.0" 170 "-25.0~+25.0" 171 "-25.0~+25.0" 172 "-25.0~+25.0" 173 "-25.0~+25.0" 174 "-25.0~+25.0" 175 "-25.0~+25.0" 176 "-25.0~+25.0" 177 "-25.0~+25.0" 178 "-25.0~+25.0" 179 "-25.0~+25.0" 180 "-25.0~+25.0" 181 "-25.0~+25.0" 182 "-25.0~+25.0" 183 "-25.0~+25.0" 184 "-25.0~+25.0" 185 "-25.0~+25.0" 186 "-25.0~+25.0" 187 "-25.0~+25.0" 188 "-25.0~+25.0" 189 "-25.0~+25.0" 190 "-25.0~+25.0" 191 "-25.0~+25.0" 192 "-25.0~+25.0" 193 "-25.0~+25.0" 194 "-25.0~+25.0" 195 "-25.0~+25.0" 196 "-25.0~+25.0" 197 "-25.0~+25.0" 198 "-25.0~+25.0" 199 "-25.0~+25.0" 200 "-25.0~+25.0" 201 "-25.0~+25.0" 202 "-25.0~+25.0" 203 "-25.0~+25.0" 204 "-25.0~+25.0" 205 "-25.0~+25.0" 206 "-25.0~+25.0" 207 "-25.0~+25.0" 208 "-25.0~+25.0" 209 "-25.0~+25.0" 210 "-25.0~+25.0" 211 "-25.0~+25.0" 212 "-25.0~+25.0" 213 "-25.0~+25.0" 214 "-25.0~+25.0" 215 "-25.0~+25.0" 216 "-25.0~+25.0" 217 "-25.0~+25.0" 218 "-25.0~+25.0" 219 "-25.0~+25.0" 220 "-25.0~+25.0" 221 "-25.0~+25.0" 222 "-25.0~+25.0" 223 "-25.0~+25.0" 224 "-25.0~+25.0" 225 "-25.0~+25.0" 226 "-25.0~+25.0" 227 "-25.0~+25.0" 228 "-25.0~+25.0" 229 "-25.0~+25.0" 230 "-25.0~+25.0" 231 "-25.0~+25.0" 232 "-25.0~+25.0" 233 "-25.0~+25.0" 234 "-25.0~+25.0" 235 "-25.0~+25.0" 236 "-25.0~+25.0" 237 "-25.0~+25.0" 238 "-25.0~+25.0" 239 "-25.0~+25.0" 240 "-25.0~+25.0" 241 "-25.0~+25.0" 242 "-25.0~+25.0" 243 "-25.0~+25.0" 244 "-25.0~+25.0" 245 "-25.0~+25.0" 246 "-25.0~+25.0" 247 "-25.0~+25.0" 248 "-25.0~+25.0" 249 "-25.0~+25.0" 250 "-25.0~+25.0" 251 "-25.0~+25.0" 252 "-25.0~+25.0" 253 "-25.0~+25.0" 254 "-25.0~+25.0" 255 "-25.0~+25.0" 256 "-25.0~+25.0" 257 "-25.0~+25.0" 258 "-25.0~+25.0" 259 "-25.0~+25.0" 260 "-25.0~+25.0" 261 "-25.0~+25.0" 262 "-25.0~+25.0" 263 "-25.0~+25.0" 264 "-25.0~+25.0" 265 "-25.0~+25.0" 266 "-25.0~+25.0" 267 "-25.0~+25.0" 268 "-25.0~+25.0" 269 "-25.0~+25.0" 270 "-25.0~+25.0" 271 "-25.0~+25.0" 272 "-25.0~+25.0" 273 "-25.0~+25.0" 274 "-25.0~+25.0" 275 "-25.0~+25.0" 276 "-25.0~+25.0" 277 "-25.0~+25.0" 278 "-25.0~+25.0" 279 "-25.0~+25.0" 280 "-25.0~+25.0" 281 "-25.0~+25.0" 282 "-25.0~+25.0" 283 "-25.0~+25.0" 284 "-25.0~+25.0" 285 "-25.0~+25.0" 286 "-25.0~+25.0" 287 "-25.0~+25.0" 288 "-25.0~+25.0" 289 "-25.0~+25.0" 290 "-25.0~+25.0" 291 "-25.0~+25.0" 292 "-25.0~+25.0" 293 "-25.0~+25.0" 294 "-25.0~+25.0" 295 "-25.0~+25.0" 296 "-25.0~+25.0" 297 "-25.0~+25.0" 298 "-25.0~+25.0" 299 "-25.0~+25.0" 300 "-25.0~+25.0" 301 "-25.0~+25.0" 302 "-25.0~+25.0" 303 "-25.0~+25.0" 304 "-25.0~+25.0" 305 "-25.0~+25.0" 306 "-25.0~+25.0" 307 "-25.0~+25.0" 308 "-25.0~+25.0" 309 "-25.0~+25.0" 310 "-25.0~+25.0" 311 "-25.0~+25.0" 312 "-25.0~+25.0" 313 "-25.0~+25.0" 314 "-25.0~+25.0" 315 "-25.0~+25.0" 316 "-25.0~+25.0" 317 "-25.0~+25.0" 318 "-25.0~+25.0" 319 "-25.0~+25.0" 320 "-25.0~+25.0" 321 "-25.0~+25.0" 322 "-25.0~+25.0" 323 "-25.0~+25.0" 324 "-25.0~+25.0" 325 "-25.0~+25.0" 326 "-25.0~+25.0" 327 "-25.0~+25.0" 328 "-25.0~+25.0" 329 "-25.0~+25.0" 330 "-25.0~+25.0" 331 "-25.0~+25.0" 332 "-25.0~+25.0" 333 "-25.0~+25.0" 334 "-25.0~+25.0" 335 "-25.0~+25.0" 336 "-25.0~+25.0" 337 "-25.0~+25.0" 338 "-25.0~+25.0" 339 "-25.0~+25.0" 340 "-25.0~+25.0" 341 "-25.0~+25.0" 342 "-25.0~+25.0" 343 "-25.0~+25.0" 344 "-25.0~+25.0" 345 "-25.0~+25.0" 346 "-25.0~+25.0" 347 "-25.0~+25.0" 348 "-25.0~+25.0" 349 "-25.0~+25.0" 350 "-25.0~+25.0" 351 "-25.0~+25.0" 352 "-25.0~+25.0" 353 "-25.0~+25.0" 354 "-25.0~+25.0" 355 "-25.0~+25.0" 356 "-25.0~+25.0" 357 "-25.0~+25.0" 358 "-25.0~+25.0" 359 "-25.0~+25.0" 360 "-25.0~+25.0" 361 "-25.0~+25.0" 362 "-25.0~+25.0" 363 "-25.0~+25.0" 364 "-25.0~+25.0" 365 "-25.0~+25.0" 366 "-25.0~+25.0" 367 "-25.0~+25.0" 368 "-25.0~+25.0" 369 "-25.0~+25.0" 370 "-25.0~+25.0" 371 "-25.0~+25.0" 372 "-25.0~+25.0" 373 "-25.0~+25.0" 374 "-25.0~+25.0" 375 "-25.0~+25.0" 376 "-25.0~+25.0" 377 "-25.0~+25.0" 378 "-25.0~+25.0" 379 "-25.0~+25.0" 380 "-25.0~+25.0" 381 "-25.0~+25.0" 382 "-25.0~+25.0" 383 "-25.0~+25.0" 384 "-25.0~+25.0" 385 "-25.0~+25.0" 386 "-25.0~+25.0" 387 "-25.0~+25.0" 388 "-25.0~+25.0" 389 "-25.0~+25.0" 390 "-25.0~+25.0" 391 "-25.0~+25.0" 392 "-25.0~+25.0" 393 "-25.0~+25.0" 394 "-25.0~+25.0" 395 "-25.0~+25.0" 396 "-25.0~+25.0" 397 "-25.0~+25.0" 398 "-25.0~+25.0" 399 "-25.0~+25.0" 400 "-25.0~+25.0" 401 "-25.0~+25.0" 402 "-25.0~+25.0" 403 "-25.0~+25.0" 404 "-25.0~+25.0" 405 "-25.0~+25.0" 406 "-25.0~+25.0" 407 "-25.0~+25.0" 408 "-25.0~+25.0" 409 "-25.0~+25.0" 410 "-25.0~+25.0" 411 "-25.0~+25.0" 412 "-25.0~+25.0" 413 "-25.0~+25.0" 414 "-25.0~+25.0" 415 "-25.0~+25.0" 416 "-25.0~+25.0" 417 "-25.0~+25.0" 418 "-25.0~+25.0" 419 "-25.0~+25.0" 420 "-25.0~+25.0" 421 "-25.0~+25.0" 422 "-25.0~+25.0" 423 "-25.0~+25.0" 424 "-25.0~+25.0" 425 "-25.0~+25.0" 426 "-25.0~+25.0" 427 "-25.0~+25.0" 428 "-25.0~+25.0" 429 "-25.0~+25.0" 430 "-25.0~+25.0" 431 "-25.0~+25.0" 432 "-25.0~+25.0" 433 "-25.0~+25.0" 434 "-25.0~+25.0" 435 "-25.0~+25.0" 436 "-25.0~+25.0" 437 "-25.0~+25.0" 438 "-25.0~+25.0" 439 "-25.0~+25.0" 440 "-25.0~+25.0" 441 "-25.0~+25.0" 442 "-25.0~+25.0" 443 "-25.0~+25.0" 444 "-25.0~+25.0" 445 "-25.0~+25.0" 446 "-25.0~+25.0" 447 "-25.0~+25.0" 448 "-25.0~+25.0" 449 "-25.0~+25.0" 450 "-25.0~+25.0" 451 "-25.0~+25.0" 452 "-25.0~+25.0" 453 "-25.0~+25.0" 454 "-25.0~+25.0" 455 "-25.0~+25.0" 456 "-25.0~+25.0" 457 "-25.0~+25.0" 458 "-25.0~+25.0" 459 "-25.0~+25.0" 460 "-25.0~+25.0" 461 "-25.0~+25.0" 462 "-25.0~+25.0" 463 "-25.0~+25.0" 464 "-25.0~+25.0" 465 "-25.0~+25.0" 466 "-25.0~+25.0" 467 "-25.0~+25.0" 468 "-25.0~+25.0" 469 "-25.0~+25.0" 470 "-25.0~+25.0" 471 "-25.0~+25.0" 472 "-25.0~+25.0" 473 "-25.0~+25.0" 474 "-25.0~+25.0" 475 "-25.0~+25.0" 476 "-25.0~+25.0" 477 "-25.0~+25.0" 478 "-25.0~+25.0" 479 "-25.0~+25.0" 480 "-25.0~+25.0" 481 "-25.0~+25.0" 482 "-25.0~+25.0" 483 "-25.0~+25.0" 484 "-25.0~+25.0" 485 "-25.0~+25.0" 486 "-25.0~+25.0" 487 "-25.0~+25.0" 488 "-25.0~+25.0" 489 "-25.0~+25.0" 490 "-25.0~+25.0" 491 "-25.0~+25.0" 492 "-25.0~+25.0" 493 "-25.0~+25.0" 494 "-25.0~+25.0" 495 "-25.0~+25.0" 496 "-25.0~+25.0" 497 "-25.0~+25.0" 498 "-25.0~+25.0" 499 "-25.0~+25.0" 500 "-25.0~+25.0" 501 "Not used" 502 "Not used" 503 "Not used" 504 "Not used" 505 "Not used" 506 "Not used" 507 "Not used" 508 "Not used" 509 "Not used" 510 "Default" 511 "Error indicator";
VAL_ 698 IFSref_VehLftAngl3Val 0 "-25.0~+25.0" 1 "-25.0~+25.0" 2 "-25.0~+25.0" 3 "-25.0~+25.0" 4 "-25.0~+25.0" 5 "-25.0~+25.0" 6 "-25.0~+25.0" 7 "-25.0~+25.0" 8 "-25.0~+25.0" 9 "-25.0~+25.0" 10 "-25.0~+25.0" 11 "-25.0~+25.0" 12 "-25.0~+25.0" 13 "-25.0~+25.0" 14 "-25.0~+25.0" 15 "-25.0~+25.0" 16 "-25.0~+25.0" 17 "-25.0~+25.0" 18 "-25.0~+25.0" 19 "-25.0~+25.0" 20 "-25.0~+25.0" 21 "-25.0~+25.0" 22 "-25.0~+25.0" 23 "-25.0~+25.0" 24 "-25.0~+25.0" 25 "-25.0~+25.0" 26 "-25.0~+25.0" 27 "-25.0~+25.0" 28 "-25.0~+25.0" 29 "-25.0~+25.0" 30 "-25.0~+25.0" 31 "-25.0~+25.0" 32 "-25.0~+25.0" 33 "-25.0~+25.0" 34 "-25.0~+25.0" 35 "-25.0~+25.0" 36 "-25.0~+25.0" 37 "-25.0~+25.0" 38 "-25.0~+25.0" 39 "-25.0~+25.0" 40 "-25.0~+25.0" 41 "-25.0~+25.0" 42 "-25.0~+25.0" 43 "-25.0~+25.0" 44 "-25.0~+25.0" 45 "-25.0~+25.0" 46 "-25.0~+25.0" 47 "-25.0~+25.0" 48 "-25.0~+25.0" 49 "-25.0~+25.0" 50 "-25.0~+25.0" 51 "-25.0~+25.0" 52 "-25.0~+25.0" 53 "-25.0~+25.0" 54 "-25.0~+25.0" 55 "-25.0~+25.0" 56 "-25.0~+25.0" 57 "-25.0~+25.0" 58 "-25.0~+25.0" 59 "-25.0~+25.0" 60 "-25.0~+25.0" 61 "-25.0~+25.0" 62 "-25.0~+25.0" 63 "-25.0~+25.0" 64 "-25.0~+25.0" 65 "-25.0~+25.0" 66 "-25.0~+25.0" 67 "-25.0~+25.0" 68 "-25.0~+25.0" 69 "-25.0~+25.0" 70 "-25.0~+25.0" 71 "-25.0~+25.0" 72 "-25.0~+25.0" 73 "-25.0~+25.0" 74 "-25.0~+25.0" 75 "-25.0~+25.0" 76 "-25.0~+25.0" 77 "-25.0~+25.0" 78 "-25.0~+25.0" 79 "-25.0~+25.0" 80 "-25.0~+25.0" 81 "-25.0~+25.0" 82 "-25.0~+25.0" 83 "-25.0~+25.0" 84 "-25.0~+25.0" 85 "-25.0~+25.0" 86 "-25.0~+25.0" 87 "-25.0~+25.0" 88 "-25.0~+25.0" 89 "-25.0~+25.0" 90 "-25.0~+25.0" 91 "-25.0~+25.0" 92 "-25.0~+25.0" 93 "-25.0~+25.0" 94 "-25.0~+25.0" 95 "-25.0~+25.0" 96 "-25.0~+25.0" 97 "-25.0~+25.0" 98 "-25.0~+25.0" 99 "-25.0~+25.0" 100 "-25.0~+25.0" 101 "-25.0~+25.0" 102 "-25.0~+25.0" 103 "-25.0~+25.0" 104 "-25.0~+25.0" 105 "-25.0~+25.0" 106 "-25.0~+25.0" 107 "-25.0~+25.0" 108 "-25.0~+25.0" 109 "-25.0~+25.0" 110 "-25.0~+25.0" 111 "-25.0~+25.0" 112 "-25.0~+25.0" 113 "-25.0~+25.0" 114 "-25.0~+25.0" 115 "-25.0~+25.0" 116 "-25.0~+25.0" 117 "-25.0~+25.0" 118 "-25.0~+25.0" 119 "-25.0~+25.0" 120 "-25.0~+25.0" 121 "-25.0~+25.0" 122 "-25.0~+25.0" 123 "-25.0~+25.0" 124 "-25.0~+25.0" 125 "-25.0~+25.0" 126 "-25.0~+25.0" 127 "-25.0~+25.0" 128 "-25.0~+25.0" 129 "-25.0~+25.0" 130 "-25.0~+25.0" 131 "-25.0~+25.0" 132 "-25.0~+25.0" 133 "-25.0~+25.0" 134 "-25.0~+25.0" 135 "-25.0~+25.0" 136 "-25.0~+25.0" 137 "-25.0~+25.0" 138 "-25.0~+25.0" 139 "-25.0~+25.0" 140 "-25.0~+25.0" 141 "-25.0~+25.0" 142 "-25.0~+25.0" 143 "-25.0~+25.0" 144 "-25.0~+25.0" 145 "-25.0~+25.0" 146 "-25.0~+25.0" 147 "-25.0~+25.0" 148 "-25.0~+25.0" 149 "-25.0~+25.0" 150 "-25.0~+25.0" 151 "-25.0~+25.0" 152 "-25.0~+25.0" 153 "-25.0~+25.0" 154 "-25.0~+25.0" 155 "-25.0~+25.0" 156 "-25.0~+25.0" 157 "-25.0~+25.0" 158 "-25.0~+25.0" 159 "-25.0~+25.0" 160 "-25.0~+25.0" 161 "-25.0~+25.0" 162 "-25.0~+25.0" 163 "-25.0~+25.0" 164 "-25.0~+25.0" 165 "-25.0~+25.0" 166 "-25.0~+25.0" 167 "-25.0~+25.0" 168 "-25.0~+25.0" 169 "-25.0~+25.0" 170 "-25.0~+25.0" 171 "-25.0~+25.0" 172 "-25.0~+25.0" 173 "-25.0~+25.0" 174 "-25.0~+25.0" 175 "-25.0~+25.0" 176 "-25.0~+25.0" 177 "-25.0~+25.0" 178 "-25.0~+25.0" 179 "-25.0~+25.0" 180 "-25.0~+25.0" 181 "-25.0~+25.0" 182 "-25.0~+25.0" 183 "-25.0~+25.0" 184 "-25.0~+25.0" 185 "-25.0~+25.0" 186 "-25.0~+25.0" 187 "-25.0~+25.0" 188 "-25.0~+25.0" 189 "-25.0~+25.0" 190 "-25.0~+25.0" 191 "-25.0~+25.0" 192 "-25.0~+25.0" 193 "-25.0~+25.0" 194 "-25.0~+25.0" 195 "-25.0~+25.0" 196 "-25.0~+25.0" 197 "-25.0~+25.0" 198 "-25.0~+25.0" 199 "-25.0~+25.0" 200 "-25.0~+25.0" 201 "-25.0~+25.0" 202 "-25.0~+25.0" 203 "-25.0~+25.0" 204 "-25.0~+25.0" 205 "-25.0~+25.0" 206 "-25.0~+25.0" 207 "-25.0~+25.0" 208 "-25.0~+25.0" 209 "-25.0~+25.0" 210 "-25.0~+25.0" 211 "-25.0~+25.0" 212 "-25.0~+25.0" 213 "-25.0~+25.0" 214 "-25.0~+25.0" 215 "-25.0~+25.0" 216 "-25.0~+25.0" 217 "-25.0~+25.0" 218 "-25.0~+25.0" 219 "-25.0~+25.0" 220 "-25.0~+25.0" 221 "-25.0~+25.0" 222 "-25.0~+25.0" 223 "-25.0~+25.0" 224 "-25.0~+25.0" 225 "-25.0~+25.0" 226 "-25.0~+25.0" 227 "-25.0~+25.0" 228 "-25.0~+25.0" 229 "-25.0~+25.0" 230 "-25.0~+25.0" 231 "-25.0~+25.0" 232 "-25.0~+25.0" 233 "-25.0~+25.0" 234 "-25.0~+25.0" 235 "-25.0~+25.0" 236 "-25.0~+25.0" 237 "-25.0~+25.0" 238 "-25.0~+25.0" 239 "-25.0~+25.0" 240 "-25.0~+25.0" 241 "-25.0~+25.0" 242 "-25.0~+25.0" 243 "-25.0~+25.0" 244 "-25.0~+25.0" 245 "-25.0~+25.0" 246 "-25.0~+25.0" 247 "-25.0~+25.0" 248 "-25.0~+25.0" 249 "-25.0~+25.0" 250 "-25.0~+25.0" 251 "-25.0~+25.0" 252 "-25.0~+25.0" 253 "-25.0~+25.0" 254 "-25.0~+25.0" 255 "-25.0~+25.0" 256 "-25.0~+25.0" 257 "-25.0~+25.0" 258 "-25.0~+25.0" 259 "-25.0~+25.0" 260 "-25.0~+25.0" 261 "-25.0~+25.0" 262 "-25.0~+25.0" 263 "-25.0~+25.0" 264 "-25.0~+25.0" 265 "-25.0~+25.0" 266 "-25.0~+25.0" 267 "-25.0~+25.0" 268 "-25.0~+25.0" 269 "-25.0~+25.0" 270 "-25.0~+25.0" 271 "-25.0~+25.0" 272 "-25.0~+25.0" 273 "-25.0~+25.0" 274 "-25.0~+25.0" 275 "-25.0~+25.0" 276 "-25.0~+25.0" 277 "-25.0~+25.0" 278 "-25.0~+25.0" 279 "-25.0~+25.0" 280 "-25.0~+25.0" 281 "-25.0~+25.0" 282 "-25.0~+25.0" 283 "-25.0~+25.0" 284 "-25.0~+25.0" 285 "-25.0~+25.0" 286 "-25.0~+25.0" 287 "-25.0~+25.0" 288 "-25.0~+25.0" 289 "-25.0~+25.0" 290 "-25.0~+25.0" 291 "-25.0~+25.0" 292 "-25.0~+25.0" 293 "-25.0~+25.0" 294 "-25.0~+25.0" 295 "-25.0~+25.0" 296 "-25.0~+25.0" 297 "-25.0~+25.0" 298 "-25.0~+25.0" 299 "-25.0~+25.0" 300 "-25.0~+25.0" 301 "-25.0~+25.0" 302 "-25.0~+25.0" 303 "-25.0~+25.0" 304 "-25.0~+25.0" 305 "-25.0~+25.0" 306 "-25.0~+25.0" 307 "-25.0~+25.0" 308 "-25.0~+25.0" 309 "-25.0~+25.0" 310 "-25.0~+25.0" 311 "-25.0~+25.0" 312 "-25.0~+25.0" 313 "-25.0~+25.0" 314 "-25.0~+25.0" 315 "-25.0~+25.0" 316 "-25.0~+25.0" 317 "-25.0~+25.0" 318 "-25.0~+25.0" 319 "-25.0~+25.0" 320 "-25.0~+25.0" 321 "-25.0~+25.0" 322 "-25.0~+25.0" 323 "-25.0~+25.0" 324 "-25.0~+25.0" 325 "-25.0~+25.0" 326 "-25.0~+25.0" 327 "-25.0~+25.0" 328 "-25.0~+25.0" 329 "-25.0~+25.0" 330 "-25.0~+25.0" 331 "-25.0~+25.0" 332 "-25.0~+25.0" 333 "-25.0~+25.0" 334 "-25.0~+25.0" 335 "-25.0~+25.0" 336 "-25.0~+25.0" 337 "-25.0~+25.0" 338 "-25.0~+25.0" 339 "-25.0~+25.0" 340 "-25.0~+25.0" 341 "-25.0~+25.0" 342 "-25.0~+25.0" 343 "-25.0~+25.0" 344 "-25.0~+25.0" 345 "-25.0~+25.0" 346 "-25.0~+25.0" 347 "-25.0~+25.0" 348 "-25.0~+25.0" 349 "-25.0~+25.0" 350 "-25.0~+25.0" 351 "-25.0~+25.0" 352 "-25.0~+25.0" 353 "-25.0~+25.0" 354 "-25.0~+25.0" 355 "-25.0~+25.0" 356 "-25.0~+25.0" 357 "-25.0~+25.0" 358 "-25.0~+25.0" 359 "-25.0~+25.0" 360 "-25.0~+25.0" 361 "-25.0~+25.0" 362 "-25.0~+25.0" 363 "-25.0~+25.0" 364 "-25.0~+25.0" 365 "-25.0~+25.0" 366 "-25.0~+25.0" 367 "-25.0~+25.0" 368 "-25.0~+25.0" 369 "-25.0~+25.0" 370 "-25.0~+25.0" 371 "-25.0~+25.0" 372 "-25.0~+25.0" 373 "-25.0~+25.0" 374 "-25.0~+25.0" 375 "-25.0~+25.0" 376 "-25.0~+25.0" 377 "-25.0~+25.0" 378 "-25.0~+25.0" 379 "-25.0~+25.0" 380 "-25.0~+25.0" 381 "-25.0~+25.0" 382 "-25.0~+25.0" 383 "-25.0~+25.0" 384 "-25.0~+25.0" 385 "-25.0~+25.0" 386 "-25.0~+25.0" 387 "-25.0~+25.0" 388 "-25.0~+25.0" 389 "-25.0~+25.0" 390 "-25.0~+25.0" 391 "-25.0~+25.0" 392 "-25.0~+25.0" 393 "-25.0~+25.0" 394 "-25.0~+25.0" 395 "-25.0~+25.0" 396 "-25.0~+25.0" 397 "-25.0~+25.0" 398 "-25.0~+25.0" 399 "-25.0~+25.0" 400 "-25.0~+25.0" 401 "-25.0~+25.0" 402 "-25.0~+25.0" 403 "-25.0~+25.0" 404 "-25.0~+25.0" 405 "-25.0~+25.0" 406 "-25.0~+25.0" 407 "-25.0~+25.0" 408 "-25.0~+25.0" 409 "-25.0~+25.0" 410 "-25.0~+25.0" 411 "-25.0~+25.0" 412 "-25.0~+25.0" 413 "-25.0~+25.0" 414 "-25.0~+25.0" 415 "-25.0~+25.0" 416 "-25.0~+25.0" 417 "-25.0~+25.0" 418 "-25.0~+25.0" 419 "-25.0~+25.0" 420 "-25.0~+25.0" 421 "-25.0~+25.0" 422 "-25.0~+25.0" 423 "-25.0~+25.0" 424 "-25.0~+25.0" 425 "-25.0~+25.0" 426 "-25.0~+25.0" 427 "-25.0~+25.0" 428 "-25.0~+25.0" 429 "-25.0~+25.0" 430 "-25.0~+25.0" 431 "-25.0~+25.0" 432 "-25.0~+25.0" 433 "-25.0~+25.0" 434 "-25.0~+25.0" 435 "-25.0~+25.0" 436 "-25.0~+25.0" 437 "-25.0~+25.0" 438 "-25.0~+25.0" 439 "-25.0~+25.0" 440 "-25.0~+25.0" 441 "-25.0~+25.0" 442 "-25.0~+25.0" 443 "-25.0~+25.0" 444 "-25.0~+25.0" 445 "-25.0~+25.0" 446 "-25.0~+25.0" 447 "-25.0~+25.0" 448 "-25.0~+25.0" 449 "-25.0~+25.0" 450 "-25.0~+25.0" 451 "-25.0~+25.0" 452 "-25.0~+25.0" 453 "-25.0~+25.0" 454 "-25.0~+25.0" 455 "-25.0~+25.0" 456 "-25.0~+25.0" 457 "-25.0~+25.0" 458 "-25.0~+25.0" 459 "-25.0~+25.0" 460 "-25.0~+25.0" 461 "-25.0~+25.0" 462 "-25.0~+25.0" 463 "-25.0~+25.0" 464 "-25.0~+25.0" 465 "-25.0~+25.0" 466 "-25.0~+25.0" 467 "-25.0~+25.0" 468 "-25.0~+25.0" 469 "-25.0~+25.0" 470 "-25.0~+25.0" 471 "-25.0~+25.0" 472 "-25.0~+25.0" 473 "-25.0~+25.0" 474 "-25.0~+25.0" 475 "-25.0~+25.0" 476 "-25.0~+25.0" 477 "-25.0~+25.0" 478 "-25.0~+25.0" 479 "-25.0~+25.0" 480 "-25.0~+25.0" 481 "-25.0~+25.0" 482 "-25.0~+25.0" 483 "-25.0~+25.0" 484 "-25.0~+25.0" 485 "-25.0~+25.0" 486 "-25.0~+25.0" 487 "-25.0~+25.0" 488 "-25.0~+25.0" 489 "-25.0~+25.0" 490 "-25.0~+25.0" 491 "-25.0~+25.0" 492 "-25.0~+25.0" 493 "-25.0~+25.0" 494 "-25.0~+25.0" 495 "-25.0~+25.0" 496 "-25.0~+25.0" 497 "-25.0~+25.0" 498 "-25.0~+25.0" 499 "-25.0~+25.0" 500 "-25.0~+25.0" 501 "Not used" 502 "Not used" 503 "Not used" 504 "Not used" 505 "Not used" 506 "Not used" 507 "Not used" 508 "Not used" 509 "Not used" 510 "Default" 511 "Error indicator";
VAL_ 698 IFSref_VehRtAngl3Val 0 "-25.0~+25.0" 1 "-25.0~+25.0" 2 "-25.0~+25.0" 3 "-25.0~+25.0" 4 "-25.0~+25.0" 5 "-25.0~+25.0" 6 "-25.0~+25.0" 7 "-25.0~+25.0" 8 "-25.0~+25.0" 9 "-25.0~+25.0" 10 "-25.0~+25.0" 11 "-25.0~+25.0" 12 "-25.0~+25.0" 13 "-25.0~+25.0" 14 "-25.0~+25.0" 15 "-25.0~+25.0" 16 "-25.0~+25.0" 17 "-25.0~+25.0" 18 "-25.0~+25.0" 19 "-25.0~+25.0" 20 "-25.0~+25.0" 21 "-25.0~+25.0" 22 "-25.0~+25.0" 23 "-25.0~+25.0" 24 "-25.0~+25.0" 25 "-25.0~+25.0" 26 "-25.0~+25.0" 27 "-25.0~+25.0" 28 "-25.0~+25.0" 29 "-25.0~+25.0" 30 "-25.0~+25.0" 31 "-25.0~+25.0" 32 "-25.0~+25.0" 33 "-25.0~+25.0" 34 "-25.0~+25.0" 35 "-25.0~+25.0" 36 "-25.0~+25.0" 37 "-25.0~+25.0" 38 "-25.0~+25.0" 39 "-25.0~+25.0" 40 "-25.0~+25.0" 41 "-25.0~+25.0" 42 "-25.0~+25.0" 43 "-25.0~+25.0" 44 "-25.0~+25.0" 45 "-25.0~+25.0" 46 "-25.0~+25.0" 47 "-25.0~+25.0" 48 "-25.0~+25.0" 49 "-25.0~+25.0" 50 "-25.0~+25.0" 51 "-25.0~+25.0" 52 "-25.0~+25.0" 53 "-25.0~+25.0" 54 "-25.0~+25.0" 55 "-25.0~+25.0" 56 "-25.0~+25.0" 57 "-25.0~+25.0" 58 "-25.0~+25.0" 59 "-25.0~+25.0" 60 "-25.0~+25.0" 61 "-25.0~+25.0" 62 "-25.0~+25.0" 63 "-25.0~+25.0" 64 "-25.0~+25.0" 65 "-25.0~+25.0" 66 "-25.0~+25.0" 67 "-25.0~+25.0" 68 "-25.0~+25.0" 69 "-25.0~+25.0" 70 "-25.0~+25.0" 71 "-25.0~+25.0" 72 "-25.0~+25.0" 73 "-25.0~+25.0" 74 "-25.0~+25.0" 75 "-25.0~+25.0" 76 "-25.0~+25.0" 77 "-25.0~+25.0" 78 "-25.0~+25.0" 79 "-25.0~+25.0" 80 "-25.0~+25.0" 81 "-25.0~+25.0" 82 "-25.0~+25.0" 83 "-25.0~+25.0" 84 "-25.0~+25.0" 85 "-25.0~+25.0" 86 "-25.0~+25.0" 87 "-25.0~+25.0" 88 "-25.0~+25.0" 89 "-25.0~+25.0" 90 "-25.0~+25.0" 91 "-25.0~+25.0" 92 "-25.0~+25.0" 93 "-25.0~+25.0" 94 "-25.0~+25.0" 95 "-25.0~+25.0" 96 "-25.0~+25.0" 97 "-25.0~+25.0" 98 "-25.0~+25.0" 99 "-25.0~+25.0" 100 "-25.0~+25.0" 101 "-25.0~+25.0" 102 "-25.0~+25.0" 103 "-25.0~+25.0" 104 "-25.0~+25.0" 105 "-25.0~+25.0" 106 "-25.0~+25.0" 107 "-25.0~+25.0" 108 "-25.0~+25.0" 109 "-25.0~+25.0" 110 "-25.0~+25.0" 111 "-25.0~+25.0" 112 "-25.0~+25.0" 113 "-25.0~+25.0" 114 "-25.0~+25.0" 115 "-25.0~+25.0" 116 "-25.0~+25.0" 117 "-25.0~+25.0" 118 "-25.0~+25.0" 119 "-25.0~+25.0" 120 "-25.0~+25.0" 121 "-25.0~+25.0" 122 "-25.0~+25.0" 123 "-25.0~+25.0" 124 "-25.0~+25.0" 125 "-25.0~+25.0" 126 "-25.0~+25.0" 127 "-25.0~+25.0" 128 "-25.0~+25.0" 129 "-25.0~+25.0" 130 "-25.0~+25.0" 131 "-25.0~+25.0" 132 "-25.0~+25.0" 133 "-25.0~+25.0" 134 "-25.0~+25.0" 135 "-25.0~+25.0" 136 "-25.0~+25.0" 137 "-25.0~+25.0" 138 "-25.0~+25.0" 139 "-25.0~+25.0" 140 "-25.0~+25.0" 141 "-25.0~+25.0" 142 "-25.0~+25.0" 143 "-25.0~+25.0" 144 "-25.0~+25.0" 145 "-25.0~+25.0" 146 "-25.0~+25.0" 147 "-25.0~+25.0" 148 "-25.0~+25.0" 149 "-25.0~+25.0" 150 "-25.0~+25.0" 151 "-25.0~+25.0" 152 "-25.0~+25.0" 153 "-25.0~+25.0" 154 "-25.0~+25.0" 155 "-25.0~+25.0" 156 "-25.0~+25.0" 157 "-25.0~+25.0" 158 "-25.0~+25.0" 159 "-25.0~+25.0" 160 "-25.0~+25.0" 161 "-25.0~+25.0" 162 "-25.0~+25.0" 163 "-25.0~+25.0" 164 "-25.0~+25.0" 165 "-25.0~+25.0" 166 "-25.0~+25.0" 167 "-25.0~+25.0" 168 "-25.0~+25.0" 169 "-25.0~+25.0" 170 "-25.0~+25.0" 171 "-25.0~+25.0" 172 "-25.0~+25.0" 173 "-25.0~+25.0" 174 "-25.0~+25.0" 175 "-25.0~+25.0" 176 "-25.0~+25.0" 177 "-25.0~+25.0" 178 "-25.0~+25.0" 179 "-25.0~+25.0" 180 "-25.0~+25.0" 181 "-25.0~+25.0" 182 "-25.0~+25.0" 183 "-25.0~+25.0" 184 "-25.0~+25.0" 185 "-25.0~+25.0" 186 "-25.0~+25.0" 187 "-25.0~+25.0" 188 "-25.0~+25.0" 189 "-25.0~+25.0" 190 "-25.0~+25.0" 191 "-25.0~+25.0" 192 "-25.0~+25.0" 193 "-25.0~+25.0" 194 "-25.0~+25.0" 195 "-25.0~+25.0" 196 "-25.0~+25.0" 197 "-25.0~+25.0" 198 "-25.0~+25.0" 199 "-25.0~+25.0" 200 "-25.0~+25.0" 201 "-25.0~+25.0" 202 "-25.0~+25.0" 203 "-25.0~+25.0" 204 "-25.0~+25.0" 205 "-25.0~+25.0" 206 "-25.0~+25.0" 207 "-25.0~+25.0" 208 "-25.0~+25.0" 209 "-25.0~+25.0" 210 "-25.0~+25.0" 211 "-25.0~+25.0" 212 "-25.0~+25.0" 213 "-25.0~+25.0" 214 "-25.0~+25.0" 215 "-25.0~+25.0" 216 "-25.0~+25.0" 217 "-25.0~+25.0" 218 "-25.0~+25.0" 219 "-25.0~+25.0" 220 "-25.0~+25.0" 221 "-25.0~+25.0" 222 "-25.0~+25.0" 223 "-25.0~+25.0" 224 "-25.0~+25.0" 225 "-25.0~+25.0" 226 "-25.0~+25.0" 227 "-25.0~+25.0" 228 "-25.0~+25.0" 229 "-25.0~+25.0" 230 "-25.0~+25.0" 231 "-25.0~+25.0" 232 "-25.0~+25.0" 233 "-25.0~+25.0" 234 "-25.0~+25.0" 235 "-25.0~+25.0" 236 "-25.0~+25.0" 237 "-25.0~+25.0" 238 "-25.0~+25.0" 239 "-25.0~+25.0" 240 "-25.0~+25.0" 241 "-25.0~+25.0" 242 "-25.0~+25.0" 243 "-25.0~+25.0" 244 "-25.0~+25.0" 245 "-25.0~+25.0" 246 "-25.0~+25.0" 247 "-25.0~+25.0" 248 "-25.0~+25.0" 249 "-25.0~+25.0" 250 "-25.0~+25.0" 251 "-25.0~+25.0" 252 "-25.0~+25.0" 253 "-25.0~+25.0" 254 "-25.0~+25.0" 255 "-25.0~+25.0" 256 "-25.0~+25.0" 257 "-25.0~+25.0" 258 "-25.0~+25.0" 259 "-25.0~+25.0" 260 "-25.0~+25.0" 261 "-25.0~+25.0" 262 "-25.0~+25.0" 263 "-25.0~+25.0" 264 "-25.0~+25.0" 265 "-25.0~+25.0" 266 "-25.0~+25.0" 267 "-25.0~+25.0" 268 "-25.0~+25.0" 269 "-25.0~+25.0" 270 "-25.0~+25.0" 271 "-25.0~+25.0" 272 "-25.0~+25.0" 273 "-25.0~+25.0" 274 "-25.0~+25.0" 275 "-25.0~+25.0" 276 "-25.0~+25.0" 277 "-25.0~+25.0" 278 "-25.0~+25.0" 279 "-25.0~+25.0" 280 "-25.0~+25.0" 281 "-25.0~+25.0" 282 "-25.0~+25.0" 283 "-25.0~+25.0" 284 "-25.0~+25.0" 285 "-25.0~+25.0" 286 "-25.0~+25.0" 287 "-25.0~+25.0" 288 "-25.0~+25.0" 289 "-25.0~+25.0" 290 "-25.0~+25.0" 291 "-25.0~+25.0" 292 "-25.0~+25.0" 293 "-25.0~+25.0" 294 "-25.0~+25.0" 295 "-25.0~+25.0" 296 "-25.0~+25.0" 297 "-25.0~+25.0" 298 "-25.0~+25.0" 299 "-25.0~+25.0" 300 "-25.0~+25.0" 301 "-25.0~+25.0" 302 "-25.0~+25.0" 303 "-25.0~+25.0" 304 "-25.0~+25.0" 305 "-25.0~+25.0" 306 "-25.0~+25.0" 307 "-25.0~+25.0" 308 "-25.0~+25.0" 309 "-25.0~+25.0" 310 "-25.0~+25.0" 311 "-25.0~+25.0" 312 "-25.0~+25.0" 313 "-25.0~+25.0" 314 "-25.0~+25.0" 315 "-25.0~+25.0" 316 "-25.0~+25.0" 317 "-25.0~+25.0" 318 "-25.0~+25.0" 319 "-25.0~+25.0" 320 "-25.0~+25.0" 321 "-25.0~+25.0" 322 "-25.0~+25.0" 323 "-25.0~+25.0" 324 "-25.0~+25.0" 325 "-25.0~+25.0" 326 "-25.0~+25.0" 327 "-25.0~+25.0" 328 "-25.0~+25.0" 329 "-25.0~+25.0" 330 "-25.0~+25.0" 331 "-25.0~+25.0" 332 "-25.0~+25.0" 333 "-25.0~+25.0" 334 "-25.0~+25.0" 335 "-25.0~+25.0" 336 "-25.0~+25.0" 337 "-25.0~+25.0" 338 "-25.0~+25.0" 339 "-25.0~+25.0" 340 "-25.0~+25.0" 341 "-25.0~+25.0" 342 "-25.0~+25.0" 343 "-25.0~+25.0" 344 "-25.0~+25.0" 345 "-25.0~+25.0" 346 "-25.0~+25.0" 347 "-25.0~+25.0" 348 "-25.0~+25.0" 349 "-25.0~+25.0" 350 "-25.0~+25.0" 351 "-25.0~+25.0" 352 "-25.0~+25.0" 353 "-25.0~+25.0" 354 "-25.0~+25.0" 355 "-25.0~+25.0" 356 "-25.0~+25.0" 357 "-25.0~+25.0" 358 "-25.0~+25.0" 359 "-25.0~+25.0" 360 "-25.0~+25.0" 361 "-25.0~+25.0" 362 "-25.0~+25.0" 363 "-25.0~+25.0" 364 "-25.0~+25.0" 365 "-25.0~+25.0" 366 "-25.0~+25.0" 367 "-25.0~+25.0" 368 "-25.0~+25.0" 369 "-25.0~+25.0" 370 "-25.0~+25.0" 371 "-25.0~+25.0" 372 "-25.0~+25.0" 373 "-25.0~+25.0" 374 "-25.0~+25.0" 375 "-25.0~+25.0" 376 "-25.0~+25.0" 377 "-25.0~+25.0" 378 "-25.0~+25.0" 379 "-25.0~+25.0" 380 "-25.0~+25.0" 381 "-25.0~+25.0" 382 "-25.0~+25.0" 383 "-25.0~+25.0" 384 "-25.0~+25.0" 385 "-25.0~+25.0" 386 "-25.0~+25.0" 387 "-25.0~+25.0" 388 "-25.0~+25.0" 389 "-25.0~+25.0" 390 "-25.0~+25.0" 391 "-25.0~+25.0" 392 "-25.0~+25.0" 393 "-25.0~+25.0" 394 "-25.0~+25.0" 395 "-25.0~+25.0" 396 "-25.0~+25.0" 397 "-25.0~+25.0" 398 "-25.0~+25.0" 399 "-25.0~+25.0" 400 "-25.0~+25.0" 401 "-25.0~+25.0" 402 "-25.0~+25.0" 403 "-25.0~+25.0" 404 "-25.0~+25.0" 405 "-25.0~+25.0" 406 "-25.0~+25.0" 407 "-25.0~+25.0" 408 "-25.0~+25.0" 409 "-25.0~+25.0" 410 "-25.0~+25.0" 411 "-25.0~+25.0" 412 "-25.0~+25.0" 413 "-25.0~+25.0" 414 "-25.0~+25.0" 415 "-25.0~+25.0" 416 "-25.0~+25.0" 417 "-25.0~+25.0" 418 "-25.0~+25.0" 419 "-25.0~+25.0" 420 "-25.0~+25.0" 421 "-25.0~+25.0" 422 "-25.0~+25.0" 423 "-25.0~+25.0" 424 "-25.0~+25.0" 425 "-25.0~+25.0" 426 "-25.0~+25.0" 427 "-25.0~+25.0" 428 "-25.0~+25.0" 429 "-25.0~+25.0" 430 "-25.0~+25.0" 431 "-25.0~+25.0" 432 "-25.0~+25.0" 433 "-25.0~+25.0" 434 "-25.0~+25.0" 435 "-25.0~+25.0" 436 "-25.0~+25.0" 437 "-25.0~+25.0" 438 "-25.0~+25.0" 439 "-25.0~+25.0" 440 "-25.0~+25.0" 441 "-25.0~+25.0" 442 "-25.0~+25.0" 443 "-25.0~+25.0" 444 "-25.0~+25.0" 445 "-25.0~+25.0" 446 "-25.0~+25.0" 447 "-25.0~+25.0" 448 "-25.0~+25.0" 449 "-25.0~+25.0" 450 "-25.0~+25.0" 451 "-25.0~+25.0" 452 "-25.0~+25.0" 453 "-25.0~+25.0" 454 "-25.0~+25.0" 455 "-25.0~+25.0" 456 "-25.0~+25.0" 457 "-25.0~+25.0" 458 "-25.0~+25.0" 459 "-25.0~+25.0" 460 "-25.0~+25.0" 461 "-25.0~+25.0" 462 "-25.0~+25.0" 463 "-25.0~+25.0" 464 "-25.0~+25.0" 465 "-25.0~+25.0" 466 "-25.0~+25.0" 467 "-25.0~+25.0" 468 "-25.0~+25.0" 469 "-25.0~+25.0" 470 "-25.0~+25.0" 471 "-25.0~+25.0" 472 "-25.0~+25.0" 473 "-25.0~+25.0" 474 "-25.0~+25.0" 475 "-25.0~+25.0" 476 "-25.0~+25.0" 477 "-25.0~+25.0" 478 "-25.0~+25.0" 479 "-25.0~+25.0" 480 "-25.0~+25.0" 481 "-25.0~+25.0" 482 "-25.0~+25.0" 483 "-25.0~+25.0" 484 "-25.0~+25.0" 485 "-25.0~+25.0" 486 "-25.0~+25.0" 487 "-25.0~+25.0" 488 "-25.0~+25.0" 489 "-25.0~+25.0" 490 "-25.0~+25.0" 491 "-25.0~+25.0" 492 "-25.0~+25.0" 493 "-25.0~+25.0" 494 "-25.0~+25.0" 495 "-25.0~+25.0" 496 "-25.0~+25.0" 497 "-25.0~+25.0" 498 "-25.0~+25.0" 499 "-25.0~+25.0" 500 "-25.0~+25.0" 501 "Not used" 502 "Not used" 503 "Not used" 504 "Not used" 505 "Not used" 506 "Not used" 507 "Not used" 508 "Not used" 509 "Not used" 510 "Default" 511 "Error indicator";
VAL_ 698 IFSref_VehLftAngl4Val 0 "-25.0~+25.0" 1 "-25.0~+25.0" 2 "-25.0~+25.0" 3 "-25.0~+25.0" 4 "-25.0~+25.0" 5 "-25.0~+25.0" 6 "-25.0~+25.0" 7 "-25.0~+25.0" 8 "-25.0~+25.0" 9 "-25.0~+25.0" 10 "-25.0~+25.0" 11 "-25.0~+25.0" 12 "-25.0~+25.0" 13 "-25.0~+25.0" 14 "-25.0~+25.0" 15 "-25.0~+25.0" 16 "-25.0~+25.0" 17 "-25.0~+25.0" 18 "-25.0~+25.0" 19 "-25.0~+25.0" 20 "-25.0~+25.0" 21 "-25.0~+25.0" 22 "-25.0~+25.0" 23 "-25.0~+25.0" 24 "-25.0~+25.0" 25 "-25.0~+25.0" 26 "-25.0~+25.0" 27 "-25.0~+25.0" 28 "-25.0~+25.0" 29 "-25.0~+25.0" 30 "-25.0~+25.0" 31 "-25.0~+25.0" 32 "-25.0~+25.0" 33 "-25.0~+25.0" 34 "-25.0~+25.0" 35 "-25.0~+25.0" 36 "-25.0~+25.0" 37 "-25.0~+25.0" 38 "-25.0~+25.0" 39 "-25.0~+25.0" 40 "-25.0~+25.0" 41 "-25.0~+25.0" 42 "-25.0~+25.0" 43 "-25.0~+25.0" 44 "-25.0~+25.0" 45 "-25.0~+25.0" 46 "-25.0~+25.0" 47 "-25.0~+25.0" 48 "-25.0~+25.0" 49 "-25.0~+25.0" 50 "-25.0~+25.0" 51 "-25.0~+25.0" 52 "-25.0~+25.0" 53 "-25.0~+25.0" 54 "-25.0~+25.0" 55 "-25.0~+25.0" 56 "-25.0~+25.0" 57 "-25.0~+25.0" 58 "-25.0~+25.0" 59 "-25.0~+25.0" 60 "-25.0~+25.0" 61 "-25.0~+25.0" 62 "-25.0~+25.0" 63 "-25.0~+25.0" 64 "-25.0~+25.0" 65 "-25.0~+25.0" 66 "-25.0~+25.0" 67 "-25.0~+25.0" 68 "-25.0~+25.0" 69 "-25.0~+25.0" 70 "-25.0~+25.0" 71 "-25.0~+25.0" 72 "-25.0~+25.0" 73 "-25.0~+25.0" 74 "-25.0~+25.0" 75 "-25.0~+25.0" 76 "-25.0~+25.0" 77 "-25.0~+25.0" 78 "-25.0~+25.0" 79 "-25.0~+25.0" 80 "-25.0~+25.0" 81 "-25.0~+25.0" 82 "-25.0~+25.0" 83 "-25.0~+25.0" 84 "-25.0~+25.0" 85 "-25.0~+25.0" 86 "-25.0~+25.0" 87 "-25.0~+25.0" 88 "-25.0~+25.0" 89 "-25.0~+25.0" 90 "-25.0~+25.0" 91 "-25.0~+25.0" 92 "-25.0~+25.0" 93 "-25.0~+25.0" 94 "-25.0~+25.0" 95 "-25.0~+25.0" 96 "-25.0~+25.0" 97 "-25.0~+25.0" 98 "-25.0~+25.0" 99 "-25.0~+25.0" 100 "-25.0~+25.0" 101 "-25.0~+25.0" 102 "-25.0~+25.0" 103 "-25.0~+25.0" 104 "-25.0~+25.0" 105 "-25.0~+25.0" 106 "-25.0~+25.0" 107 "-25.0~+25.0" 108 "-25.0~+25.0" 109 "-25.0~+25.0" 110 "-25.0~+25.0" 111 "-25.0~+25.0" 112 "-25.0~+25.0" 113 "-25.0~+25.0" 114 "-25.0~+25.0" 115 "-25.0~+25.0" 116 "-25.0~+25.0" 117 "-25.0~+25.0" 118 "-25.0~+25.0" 119 "-25.0~+25.0" 120 "-25.0~+25.0" 121 "-25.0~+25.0" 122 "-25.0~+25.0" 123 "-25.0~+25.0" 124 "-25.0~+25.0" 125 "-25.0~+25.0" 126 "-25.0~+25.0" 127 "-25.0~+25.0" 128 "-25.0~+25.0" 129 "-25.0~+25.0" 130 "-25.0~+25.0" 131 "-25.0~+25.0" 132 "-25.0~+25.0" 133 "-25.0~+25.0" 134 "-25.0~+25.0" 135 "-25.0~+25.0" 136 "-25.0~+25.0" 137 "-25.0~+25.0" 138 "-25.0~+25.0" 139 "-25.0~+25.0" 140 "-25.0~+25.0" 141 "-25.0~+25.0" 142 "-25.0~+25.0" 143 "-25.0~+25.0" 144 "-25.0~+25.0" 145 "-25.0~+25.0" 146 "-25.0~+25.0" 147 "-25.0~+25.0" 148 "-25.0~+25.0" 149 "-25.0~+25.0" 150 "-25.0~+25.0" 151 "-25.0~+25.0" 152 "-25.0~+25.0" 153 "-25.0~+25.0" 154 "-25.0~+25.0" 155 "-25.0~+25.0" 156 "-25.0~+25.0" 157 "-25.0~+25.0" 158 "-25.0~+25.0" 159 "-25.0~+25.0" 160 "-25.0~+25.0" 161 "-25.0~+25.0" 162 "-25.0~+25.0" 163 "-25.0~+25.0" 164 "-25.0~+25.0" 165 "-25.0~+25.0" 166 "-25.0~+25.0" 167 "-25.0~+25.0" 168 "-25.0~+25.0" 169 "-25.0~+25.0" 170 "-25.0~+25.0" 171 "-25.0~+25.0" 172 "-25.0~+25.0" 173 "-25.0~+25.0" 174 "-25.0~+25.0" 175 "-25.0~+25.0" 176 "-25.0~+25.0" 177 "-25.0~+25.0" 178 "-25.0~+25.0" 179 "-25.0~+25.0" 180 "-25.0~+25.0" 181 "-25.0~+25.0" 182 "-25.0~+25.0" 183 "-25.0~+25.0" 184 "-25.0~+25.0" 185 "-25.0~+25.0" 186 "-25.0~+25.0" 187 "-25.0~+25.0" 188 "-25.0~+25.0" 189 "-25.0~+25.0" 190 "-25.0~+25.0" 191 "-25.0~+25.0" 192 "-25.0~+25.0" 193 "-25.0~+25.0" 194 "-25.0~+25.0" 195 "-25.0~+25.0" 196 "-25.0~+25.0" 197 "-25.0~+25.0" 198 "-25.0~+25.0" 199 "-25.0~+25.0" 200 "-25.0~+25.0" 201 "-25.0~+25.0" 202 "-25.0~+25.0" 203 "-25.0~+25.0" 204 "-25.0~+25.0" 205 "-25.0~+25.0" 206 "-25.0~+25.0" 207 "-25.0~+25.0" 208 "-25.0~+25.0" 209 "-25.0~+25.0" 210 "-25.0~+25.0" 211 "-25.0~+25.0" 212 "-25.0~+25.0" 213 "-25.0~+25.0" 214 "-25.0~+25.0" 215 "-25.0~+25.0" 216 "-25.0~+25.0" 217 "-25.0~+25.0" 218 "-25.0~+25.0" 219 "-25.0~+25.0" 220 "-25.0~+25.0" 221 "-25.0~+25.0" 222 "-25.0~+25.0" 223 "-25.0~+25.0" 224 "-25.0~+25.0" 225 "-25.0~+25.0" 226 "-25.0~+25.0" 227 "-25.0~+25.0" 228 "-25.0~+25.0" 229 "-25.0~+25.0" 230 "-25.0~+25.0" 231 "-25.0~+25.0" 232 "-25.0~+25.0" 233 "-25.0~+25.0" 234 "-25.0~+25.0" 235 "-25.0~+25.0" 236 "-25.0~+25.0" 237 "-25.0~+25.0" 238 "-25.0~+25.0" 239 "-25.0~+25.0" 240 "-25.0~+25.0" 241 "-25.0~+25.0" 242 "-25.0~+25.0" 243 "-25.0~+25.0" 244 "-25.0~+25.0" 245 "-25.0~+25.0" 246 "-25.0~+25.0" 247 "-25.0~+25.0" 248 "-25.0~+25.0" 249 "-25.0~+25.0" 250 "-25.0~+25.0" 251 "-25.0~+25.0" 252 "-25.0~+25.0" 253 "-25.0~+25.0" 254 "-25.0~+25.0" 255 "-25.0~+25.0" 256 "-25.0~+25.0" 257 "-25.0~+25.0" 258 "-25.0~+25.0" 259 "-25.0~+25.0" 260 "-25.0~+25.0" 261 "-25.0~+25.0" 262 "-25.0~+25.0" 263 "-25.0~+25.0" 264 "-25.0~+25.0" 265 "-25.0~+25.0" 266 "-25.0~+25.0" 267 "-25.0~+25.0" 268 "-25.0~+25.0" 269 "-25.0~+25.0" 270 "-25.0~+25.0" 271 "-25.0~+25.0" 272 "-25.0~+25.0" 273 "-25.0~+25.0" 274 "-25.0~+25.0" 275 "-25.0~+25.0" 276 "-25.0~+25.0" 277 "-25.0~+25.0" 278 "-25.0~+25.0" 279 "-25.0~+25.0" 280 "-25.0~+25.0" 281 "-25.0~+25.0" 282 "-25.0~+25.0" 283 "-25.0~+25.0" 284 "-25.0~+25.0" 285 "-25.0~+25.0" 286 "-25.0~+25.0" 287 "-25.0~+25.0" 288 "-25.0~+25.0" 289 "-25.0~+25.0" 290 "-25.0~+25.0" 291 "-25.0~+25.0" 292 "-25.0~+25.0" 293 "-25.0~+25.0" 294 "-25.0~+25.0" 295 "-25.0~+25.0" 296 "-25.0~+25.0" 297 "-25.0~+25.0" 298 "-25.0~+25.0" 299 "-25.0~+25.0" 300 "-25.0~+25.0" 301 "-25.0~+25.0" 302 "-25.0~+25.0" 303 "-25.0~+25.0" 304 "-25.0~+25.0" 305 "-25.0~+25.0" 306 "-25.0~+25.0" 307 "-25.0~+25.0" 308 "-25.0~+25.0" 309 "-25.0~+25.0" 310 "-25.0~+25.0" 311 "-25.0~+25.0" 312 "-25.0~+25.0" 313 "-25.0~+25.0" 314 "-25.0~+25.0" 315 "-25.0~+25.0" 316 "-25.0~+25.0" 317 "-25.0~+25.0" 318 "-25.0~+25.0" 319 "-25.0~+25.0" 320 "-25.0~+25.0" 321 "-25.0~+25.0" 322 "-25.0~+25.0" 323 "-25.0~+25.0" 324 "-25.0~+25.0" 325 "-25.0~+25.0" 326 "-25.0~+25.0" 327 "-25.0~+25.0" 328 "-25.0~+25.0" 329 "-25.0~+25.0" 330 "-25.0~+25.0" 331 "-25.0~+25.0" 332 "-25.0~+25.0" 333 "-25.0~+25.0" 334 "-25.0~+25.0" 335 "-25.0~+25.0" 336 "-25.0~+25.0" 337 "-25.0~+25.0" 338 "-25.0~+25.0" 339 "-25.0~+25.0" 340 "-25.0~+25.0" 341 "-25.0~+25.0" 342 "-25.0~+25.0" 343 "-25.0~+25.0" 344 "-25.0~+25.0" 345 "-25.0~+25.0" 346 "-25.0~+25.0" 347 "-25.0~+25.0" 348 "-25.0~+25.0" 349 "-25.0~+25.0" 350 "-25.0~+25.0" 351 "-25.0~+25.0" 352 "-25.0~+25.0" 353 "-25.0~+25.0" 354 "-25.0~+25.0" 355 "-25.0~+25.0" 356 "-25.0~+25.0" 357 "-25.0~+25.0" 358 "-25.0~+25.0" 359 "-25.0~+25.0" 360 "-25.0~+25.0" 361 "-25.0~+25.0" 362 "-25.0~+25.0" 363 "-25.0~+25.0" 364 "-25.0~+25.0" 365 "-25.0~+25.0" 366 "-25.0~+25.0" 367 "-25.0~+25.0" 368 "-25.0~+25.0" 369 "-25.0~+25.0" 370 "-25.0~+25.0" 371 "-25.0~+25.0" 372 "-25.0~+25.0" 373 "-25.0~+25.0" 374 "-25.0~+25.0" 375 "-25.0~+25.0" 376 "-25.0~+25.0" 377 "-25.0~+25.0" 378 "-25.0~+25.0" 379 "-25.0~+25.0" 380 "-25.0~+25.0" 381 "-25.0~+25.0" 382 "-25.0~+25.0" 383 "-25.0~+25.0" 384 "-25.0~+25.0" 385 "-25.0~+25.0" 386 "-25.0~+25.0" 387 "-25.0~+25.0" 388 "-25.0~+25.0" 389 "-25.0~+25.0" 390 "-25.0~+25.0" 391 "-25.0~+25.0" 392 "-25.0~+25.0" 393 "-25.0~+25.0" 394 "-25.0~+25.0" 395 "-25.0~+25.0" 396 "-25.0~+25.0" 397 "-25.0~+25.0" 398 "-25.0~+25.0" 399 "-25.0~+25.0" 400 "-25.0~+25.0" 401 "-25.0~+25.0" 402 "-25.0~+25.0" 403 "-25.0~+25.0" 404 "-25.0~+25.0" 405 "-25.0~+25.0" 406 "-25.0~+25.0" 407 "-25.0~+25.0" 408 "-25.0~+25.0" 409 "-25.0~+25.0" 410 "-25.0~+25.0" 411 "-25.0~+25.0" 412 "-25.0~+25.0" 413 "-25.0~+25.0" 414 "-25.0~+25.0" 415 "-25.0~+25.0" 416 "-25.0~+25.0" 417 "-25.0~+25.0" 418 "-25.0~+25.0" 419 "-25.0~+25.0" 420 "-25.0~+25.0" 421 "-25.0~+25.0" 422 "-25.0~+25.0" 423 "-25.0~+25.0" 424 "-25.0~+25.0" 425 "-25.0~+25.0" 426 "-25.0~+25.0" 427 "-25.0~+25.0" 428 "-25.0~+25.0" 429 "-25.0~+25.0" 430 "-25.0~+25.0" 431 "-25.0~+25.0" 432 "-25.0~+25.0" 433 "-25.0~+25.0" 434 "-25.0~+25.0" 435 "-25.0~+25.0" 436 "-25.0~+25.0" 437 "-25.0~+25.0" 438 "-25.0~+25.0" 439 "-25.0~+25.0" 440 "-25.0~+25.0" 441 "-25.0~+25.0" 442 "-25.0~+25.0" 443 "-25.0~+25.0" 444 "-25.0~+25.0" 445 "-25.0~+25.0" 446 "-25.0~+25.0" 447 "-25.0~+25.0" 448 "-25.0~+25.0" 449 "-25.0~+25.0" 450 "-25.0~+25.0" 451 "-25.0~+25.0" 452 "-25.0~+25.0" 453 "-25.0~+25.0" 454 "-25.0~+25.0" 455 "-25.0~+25.0" 456 "-25.0~+25.0" 457 "-25.0~+25.0" 458 "-25.0~+25.0" 459 "-25.0~+25.0" 460 "-25.0~+25.0" 461 "-25.0~+25.0" 462 "-25.0~+25.0" 463 "-25.0~+25.0" 464 "-25.0~+25.0" 465 "-25.0~+25.0" 466 "-25.0~+25.0" 467 "-25.0~+25.0" 468 "-25.0~+25.0" 469 "-25.0~+25.0" 470 "-25.0~+25.0" 471 "-25.0~+25.0" 472 "-25.0~+25.0" 473 "-25.0~+25.0" 474 "-25.0~+25.0" 475 "-25.0~+25.0" 476 "-25.0~+25.0" 477 "-25.0~+25.0" 478 "-25.0~+25.0" 479 "-25.0~+25.0" 480 "-25.0~+25.0" 481 "-25.0~+25.0" 482 "-25.0~+25.0" 483 "-25.0~+25.0" 484 "-25.0~+25.0" 485 "-25.0~+25.0" 486 "-25.0~+25.0" 487 "-25.0~+25.0" 488 "-25.0~+25.0" 489 "-25.0~+25.0" 490 "-25.0~+25.0" 491 "-25.0~+25.0" 492 "-25.0~+25.0" 493 "-25.0~+25.0" 494 "-25.0~+25.0" 495 "-25.0~+25.0" 496 "-25.0~+25.0" 497 "-25.0~+25.0" 498 "-25.0~+25.0" 499 "-25.0~+25.0" 500 "-25.0~+25.0" 501 "Not used" 502 "Not used" 503 "Not used" 504 "Not used" 505 "Not used" 506 "Not used" 507 "Not used" 508 "Not used" 509 "Not used" 510 "Default" 511 "Error indicator";
VAL_ 698 IFSref_VehRtAngl4Val 0 "-25.0~+25.0" 1 "-25.0~+25.0" 2 "-25.0~+25.0" 3 "-25.0~+25.0" 4 "-25.0~+25.0" 5 "-25.0~+25.0" 6 "-25.0~+25.0" 7 "-25.0~+25.0" 8 "-25.0~+25.0" 9 "-25.0~+25.0" 10 "-25.0~+25.0" 11 "-25.0~+25.0" 12 "-25.0~+25.0" 13 "-25.0~+25.0" 14 "-25.0~+25.0" 15 "-25.0~+25.0" 16 "-25.0~+25.0" 17 "-25.0~+25.0" 18 "-25.0~+25.0" 19 "-25.0~+25.0" 20 "-25.0~+25.0" 21 "-25.0~+25.0" 22 "-25.0~+25.0" 23 "-25.0~+25.0" 24 "-25.0~+25.0" 25 "-25.0~+25.0" 26 "-25.0~+25.0" 27 "-25.0~+25.0" 28 "-25.0~+25.0" 29 "-25.0~+25.0" 30 "-25.0~+25.0" 31 "-25.0~+25.0" 32 "-25.0~+25.0" 33 "-25.0~+25.0" 34 "-25.0~+25.0" 35 "-25.0~+25.0" 36 "-25.0~+25.0" 37 "-25.0~+25.0" 38 "-25.0~+25.0" 39 "-25.0~+25.0" 40 "-25.0~+25.0" 41 "-25.0~+25.0" 42 "-25.0~+25.0" 43 "-25.0~+25.0" 44 "-25.0~+25.0" 45 "-25.0~+25.0" 46 "-25.0~+25.0" 47 "-25.0~+25.0" 48 "-25.0~+25.0" 49 "-25.0~+25.0" 50 "-25.0~+25.0" 51 "-25.0~+25.0" 52 "-25.0~+25.0" 53 "-25.0~+25.0" 54 "-25.0~+25.0" 55 "-25.0~+25.0" 56 "-25.0~+25.0" 57 "-25.0~+25.0" 58 "-25.0~+25.0" 59 "-25.0~+25.0" 60 "-25.0~+25.0" 61 "-25.0~+25.0" 62 "-25.0~+25.0" 63 "-25.0~+25.0" 64 "-25.0~+25.0" 65 "-25.0~+25.0" 66 "-25.0~+25.0" 67 "-25.0~+25.0" 68 "-25.0~+25.0" 69 "-25.0~+25.0" 70 "-25.0~+25.0" 71 "-25.0~+25.0" 72 "-25.0~+25.0" 73 "-25.0~+25.0" 74 "-25.0~+25.0" 75 "-25.0~+25.0" 76 "-25.0~+25.0" 77 "-25.0~+25.0" 78 "-25.0~+25.0" 79 "-25.0~+25.0" 80 "-25.0~+25.0" 81 "-25.0~+25.0" 82 "-25.0~+25.0" 83 "-25.0~+25.0" 84 "-25.0~+25.0" 85 "-25.0~+25.0" 86 "-25.0~+25.0" 87 "-25.0~+25.0" 88 "-25.0~+25.0" 89 "-25.0~+25.0" 90 "-25.0~+25.0" 91 "-25.0~+25.0" 92 "-25.0~+25.0" 93 "-25.0~+25.0" 94 "-25.0~+25.0" 95 "-25.0~+25.0" 96 "-25.0~+25.0" 97 "-25.0~+25.0" 98 "-25.0~+25.0" 99 "-25.0~+25.0" 100 "-25.0~+25.0" 101 "-25.0~+25.0" 102 "-25.0~+25.0" 103 "-25.0~+25.0" 104 "-25.0~+25.0" 105 "-25.0~+25.0" 106 "-25.0~+25.0" 107 "-25.0~+25.0" 108 "-25.0~+25.0" 109 "-25.0~+25.0" 110 "-25.0~+25.0" 111 "-25.0~+25.0" 112 "-25.0~+25.0" 113 "-25.0~+25.0" 114 "-25.0~+25.0" 115 "-25.0~+25.0" 116 "-25.0~+25.0" 117 "-25.0~+25.0" 118 "-25.0~+25.0" 119 "-25.0~+25.0" 120 "-25.0~+25.0" 121 "-25.0~+25.0" 122 "-25.0~+25.0" 123 "-25.0~+25.0" 124 "-25.0~+25.0" 125 "-25.0~+25.0" 126 "-25.0~+25.0" 127 "-25.0~+25.0" 128 "-25.0~+25.0" 129 "-25.0~+25.0" 130 "-25.0~+25.0" 131 "-25.0~+25.0" 132 "-25.0~+25.0" 133 "-25.0~+25.0" 134 "-25.0~+25.0" 135 "-25.0~+25.0" 136 "-25.0~+25.0" 137 "-25.0~+25.0" 138 "-25.0~+25.0" 139 "-25.0~+25.0" 140 "-25.0~+25.0" 141 "-25.0~+25.0" 142 "-25.0~+25.0" 143 "-25.0~+25.0" 144 "-25.0~+25.0" 145 "-25.0~+25.0" 146 "-25.0~+25.0" 147 "-25.0~+25.0" 148 "-25.0~+25.0" 149 "-25.0~+25.0" 150 "-25.0~+25.0" 151 "-25.0~+25.0" 152 "-25.0~+25.0" 153 "-25.0~+25.0" 154 "-25.0~+25.0" 155 "-25.0~+25.0" 156 "-25.0~+25.0" 157 "-25.0~+25.0" 158 "-25.0~+25.0" 159 "-25.0~+25.0" 160 "-25.0~+25.0" 161 "-25.0~+25.0" 162 "-25.0~+25.0" 163 "-25.0~+25.0" 164 "-25.0~+25.0" 165 "-25.0~+25.0" 166 "-25.0~+25.0" 167 "-25.0~+25.0" 168 "-25.0~+25.0" 169 "-25.0~+25.0" 170 "-25.0~+25.0" 171 "-25.0~+25.0" 172 "-25.0~+25.0" 173 "-25.0~+25.0" 174 "-25.0~+25.0" 175 "-25.0~+25.0" 176 "-25.0~+25.0" 177 "-25.0~+25.0" 178 "-25.0~+25.0" 179 "-25.0~+25.0" 180 "-25.0~+25.0" 181 "-25.0~+25.0" 182 "-25.0~+25.0" 183 "-25.0~+25.0" 184 "-25.0~+25.0" 185 "-25.0~+25.0" 186 "-25.0~+25.0" 187 "-25.0~+25.0" 188 "-25.0~+25.0" 189 "-25.0~+25.0" 190 "-25.0~+25.0" 191 "-25.0~+25.0" 192 "-25.0~+25.0" 193 "-25.0~+25.0" 194 "-25.0~+25.0" 195 "-25.0~+25.0" 196 "-25.0~+25.0" 197 "-25.0~+25.0" 198 "-25.0~+25.0" 199 "-25.0~+25.0" 200 "-25.0~+25.0" 201 "-25.0~+25.0" 202 "-25.0~+25.0" 203 "-25.0~+25.0" 204 "-25.0~+25.0" 205 "-25.0~+25.0" 206 "-25.0~+25.0" 207 "-25.0~+25.0" 208 "-25.0~+25.0" 209 "-25.0~+25.0" 210 "-25.0~+25.0" 211 "-25.0~+25.0" 212 "-25.0~+25.0" 213 "-25.0~+25.0" 214 "-25.0~+25.0" 215 "-25.0~+25.0" 216 "-25.0~+25.0" 217 "-25.0~+25.0" 218 "-25.0~+25.0" 219 "-25.0~+25.0" 220 "-25.0~+25.0" 221 "-25.0~+25.0" 222 "-25.0~+25.0" 223 "-25.0~+25.0" 224 "-25.0~+25.0" 225 "-25.0~+25.0" 226 "-25.0~+25.0" 227 "-25.0~+25.0" 228 "-25.0~+25.0" 229 "-25.0~+25.0" 230 "-25.0~+25.0" 231 "-25.0~+25.0" 232 "-25.0~+25.0" 233 "-25.0~+25.0" 234 "-25.0~+25.0" 235 "-25.0~+25.0" 236 "-25.0~+25.0" 237 "-25.0~+25.0" 238 "-25.0~+25.0" 239 "-25.0~+25.0" 240 "-25.0~+25.0" 241 "-25.0~+25.0" 242 "-25.0~+25.0" 243 "-25.0~+25.0" 244 "-25.0~+25.0" 245 "-25.0~+25.0" 246 "-25.0~+25.0" 247 "-25.0~+25.0" 248 "-25.0~+25.0" 249 "-25.0~+25.0" 250 "-25.0~+25.0" 251 "-25.0~+25.0" 252 "-25.0~+25.0" 253 "-25.0~+25.0" 254 "-25.0~+25.0" 255 "-25.0~+25.0" 256 "-25.0~+25.0" 257 "-25.0~+25.0" 258 "-25.0~+25.0" 259 "-25.0~+25.0" 260 "-25.0~+25.0" 261 "-25.0~+25.0" 262 "-25.0~+25.0" 263 "-25.0~+25.0" 264 "-25.0~+25.0" 265 "-25.0~+25.0" 266 "-25.0~+25.0" 267 "-25.0~+25.0" 268 "-25.0~+25.0" 269 "-25.0~+25.0" 270 "-25.0~+25.0" 271 "-25.0~+25.0" 272 "-25.0~+25.0" 273 "-25.0~+25.0" 274 "-25.0~+25.0" 275 "-25.0~+25.0" 276 "-25.0~+25.0" 277 "-25.0~+25.0" 278 "-25.0~+25.0" 279 "-25.0~+25.0" 280 "-25.0~+25.0" 281 "-25.0~+25.0" 282 "-25.0~+25.0" 283 "-25.0~+25.0" 284 "-25.0~+25.0" 285 "-25.0~+25.0" 286 "-25.0~+25.0" 287 "-25.0~+25.0" 288 "-25.0~+25.0" 289 "-25.0~+25.0" 290 "-25.0~+25.0" 291 "-25.0~+25.0" 292 "-25.0~+25.0" 293 "-25.0~+25.0" 294 "-25.0~+25.0" 295 "-25.0~+25.0" 296 "-25.0~+25.0" 297 "-25.0~+25.0" 298 "-25.0~+25.0" 299 "-25.0~+25.0" 300 "-25.0~+25.0" 301 "-25.0~+25.0" 302 "-25.0~+25.0" 303 "-25.0~+25.0" 304 "-25.0~+25.0" 305 "-25.0~+25.0" 306 "-25.0~+25.0" 307 "-25.0~+25.0" 308 "-25.0~+25.0" 309 "-25.0~+25.0" 310 "-25.0~+25.0" 311 "-25.0~+25.0" 312 "-25.0~+25.0" 313 "-25.0~+25.0" 314 "-25.0~+25.0" 315 "-25.0~+25.0" 316 "-25.0~+25.0" 317 "-25.0~+25.0" 318 "-25.0~+25.0" 319 "-25.0~+25.0" 320 "-25.0~+25.0" 321 "-25.0~+25.0" 322 "-25.0~+25.0" 323 "-25.0~+25.0" 324 "-25.0~+25.0" 325 "-25.0~+25.0" 326 "-25.0~+25.0" 327 "-25.0~+25.0" 328 "-25.0~+25.0" 329 "-25.0~+25.0" 330 "-25.0~+25.0" 331 "-25.0~+25.0" 332 "-25.0~+25.0" 333 "-25.0~+25.0" 334 "-25.0~+25.0" 335 "-25.0~+25.0" 336 "-25.0~+25.0" 337 "-25.0~+25.0" 338 "-25.0~+25.0" 339 "-25.0~+25.0" 340 "-25.0~+25.0" 341 "-25.0~+25.0" 342 "-25.0~+25.0" 343 "-25.0~+25.0" 344 "-25.0~+25.0" 345 "-25.0~+25.0" 346 "-25.0~+25.0" 347 "-25.0~+25.0" 348 "-25.0~+25.0" 349 "-25.0~+25.0" 350 "-25.0~+25.0" 351 "-25.0~+25.0" 352 "-25.0~+25.0" 353 "-25.0~+25.0" 354 "-25.0~+25.0" 355 "-25.0~+25.0" 356 "-25.0~+25.0" 357 "-25.0~+25.0" 358 "-25.0~+25.0" 359 "-25.0~+25.0" 360 "-25.0~+25.0" 361 "-25.0~+25.0" 362 "-25.0~+25.0" 363 "-25.0~+25.0" 364 "-25.0~+25.0" 365 "-25.0~+25.0" 366 "-25.0~+25.0" 367 "-25.0~+25.0" 368 "-25.0~+25.0" 369 "-25.0~+25.0" 370 "-25.0~+25.0" 371 "-25.0~+25.0" 372 "-25.0~+25.0" 373 "-25.0~+25.0" 374 "-25.0~+25.0" 375 "-25.0~+25.0" 376 "-25.0~+25.0" 377 "-25.0~+25.0" 378 "-25.0~+25.0" 379 "-25.0~+25.0" 380 "-25.0~+25.0" 381 "-25.0~+25.0" 382 "-25.0~+25.0" 383 "-25.0~+25.0" 384 "-25.0~+25.0" 385 "-25.0~+25.0" 386 "-25.0~+25.0" 387 "-25.0~+25.0" 388 "-25.0~+25.0" 389 "-25.0~+25.0" 390 "-25.0~+25.0" 391 "-25.0~+25.0" 392 "-25.0~+25.0" 393 "-25.0~+25.0" 394 "-25.0~+25.0" 395 "-25.0~+25.0" 396 "-25.0~+25.0" 397 "-25.0~+25.0" 398 "-25.0~+25.0" 399 "-25.0~+25.0" 400 "-25.0~+25.0" 401 "-25.0~+25.0" 402 "-25.0~+25.0" 403 "-25.0~+25.0" 404 "-25.0~+25.0" 405 "-25.0~+25.0" 406 "-25.0~+25.0" 407 "-25.0~+25.0" 408 "-25.0~+25.0" 409 "-25.0~+25.0" 410 "-25.0~+25.0" 411 "-25.0~+25.0" 412 "-25.0~+25.0" 413 "-25.0~+25.0" 414 "-25.0~+25.0" 415 "-25.0~+25.0" 416 "-25.0~+25.0" 417 "-25.0~+25.0" 418 "-25.0~+25.0" 419 "-25.0~+25.0" 420 "-25.0~+25.0" 421 "-25.0~+25.0" 422 "-25.0~+25.0" 423 "-25.0~+25.0" 424 "-25.0~+25.0" 425 "-25.0~+25.0" 426 "-25.0~+25.0" 427 "-25.0~+25.0" 428 "-25.0~+25.0" 429 "-25.0~+25.0" 430 "-25.0~+25.0" 431 "-25.0~+25.0" 432 "-25.0~+25.0" 433 "-25.0~+25.0" 434 "-25.0~+25.0" 435 "-25.0~+25.0" 436 "-25.0~+25.0" 437 "-25.0~+25.0" 438 "-25.0~+25.0" 439 "-25.0~+25.0" 440 "-25.0~+25.0" 441 "-25.0~+25.0" 442 "-25.0~+25.0" 443 "-25.0~+25.0" 444 "-25.0~+25.0" 445 "-25.0~+25.0" 446 "-25.0~+25.0" 447 "-25.0~+25.0" 448 "-25.0~+25.0" 449 "-25.0~+25.0" 450 "-25.0~+25.0" 451 "-25.0~+25.0" 452 "-25.0~+25.0" 453 "-25.0~+25.0" 454 "-25.0~+25.0" 455 "-25.0~+25.0" 456 "-25.0~+25.0" 457 "-25.0~+25.0" 458 "-25.0~+25.0" 459 "-25.0~+25.0" 460 "-25.0~+25.0" 461 "-25.0~+25.0" 462 "-25.0~+25.0" 463 "-25.0~+25.0" 464 "-25.0~+25.0" 465 "-25.0~+25.0" 466 "-25.0~+25.0" 467 "-25.0~+25.0" 468 "-25.0~+25.0" 469 "-25.0~+25.0" 470 "-25.0~+25.0" 471 "-25.0~+25.0" 472 "-25.0~+25.0" 473 "-25.0~+25.0" 474 "-25.0~+25.0" 475 "-25.0~+25.0" 476 "-25.0~+25.0" 477 "-25.0~+25.0" 478 "-25.0~+25.0" 479 "-25.0~+25.0" 480 "-25.0~+25.0" 481 "-25.0~+25.0" 482 "-25.0~+25.0" 483 "-25.0~+25.0" 484 "-25.0~+25.0" 485 "-25.0~+25.0" 486 "-25.0~+25.0" 487 "-25.0~+25.0" 488 "-25.0~+25.0" 489 "-25.0~+25.0" 490 "-25.0~+25.0" 491 "-25.0~+25.0" 492 "-25.0~+25.0" 493 "-25.0~+25.0" 494 "-25.0~+25.0" 495 "-25.0~+25.0" 496 "-25.0~+25.0" 497 "-25.0~+25.0" 498 "-25.0~+25.0" 499 "-25.0~+25.0" 500 "-25.0~+25.0" 501 "Not used" 502 "Not used" 503 "Not used" 504 "Not used" 505 "Not used" 506 "Not used" 507 "Not used" 508 "Not used" 509 "Not used" 510 "Default" 511 "Error indicator";
VAL_ 698 IFSref_VehLftAngl5Val 0 "-25.0~+25.0" 1 "-25.0~+25.0" 2 "-25.0~+25.0" 3 "-25.0~+25.0" 4 "-25.0~+25.0" 5 "-25.0~+25.0" 6 "-25.0~+25.0" 7 "-25.0~+25.0" 8 "-25.0~+25.0" 9 "-25.0~+25.0" 10 "-25.0~+25.0" 11 "-25.0~+25.0" 12 "-25.0~+25.0" 13 "-25.0~+25.0" 14 "-25.0~+25.0" 15 "-25.0~+25.0" 16 "-25.0~+25.0" 17 "-25.0~+25.0" 18 "-25.0~+25.0" 19 "-25.0~+25.0" 20 "-25.0~+25.0" 21 "-25.0~+25.0" 22 "-25.0~+25.0" 23 "-25.0~+25.0" 24 "-25.0~+25.0" 25 "-25.0~+25.0" 26 "-25.0~+25.0" 27 "-25.0~+25.0" 28 "-25.0~+25.0" 29 "-25.0~+25.0" 30 "-25.0~+25.0" 31 "-25.0~+25.0" 32 "-25.0~+25.0" 33 "-25.0~+25.0" 34 "-25.0~+25.0" 35 "-25.0~+25.0" 36 "-25.0~+25.0" 37 "-25.0~+25.0" 38 "-25.0~+25.0" 39 "-25.0~+25.0" 40 "-25.0~+25.0" 41 "-25.0~+25.0" 42 "-25.0~+25.0" 43 "-25.0~+25.0" 44 "-25.0~+25.0" 45 "-25.0~+25.0" 46 "-25.0~+25.0" 47 "-25.0~+25.0" 48 "-25.0~+25.0" 49 "-25.0~+25.0" 50 "-25.0~+25.0" 51 "-25.0~+25.0" 52 "-25.0~+25.0" 53 "-25.0~+25.0" 54 "-25.0~+25.0" 55 "-25.0~+25.0" 56 "-25.0~+25.0" 57 "-25.0~+25.0" 58 "-25.0~+25.0" 59 "-25.0~+25.0" 60 "-25.0~+25.0" 61 "-25.0~+25.0" 62 "-25.0~+25.0" 63 "-25.0~+25.0" 64 "-25.0~+25.0" 65 "-25.0~+25.0" 66 "-25.0~+25.0" 67 "-25.0~+25.0" 68 "-25.0~+25.0" 69 "-25.0~+25.0" 70 "-25.0~+25.0" 71 "-25.0~+25.0" 72 "-25.0~+25.0" 73 "-25.0~+25.0" 74 "-25.0~+25.0" 75 "-25.0~+25.0" 76 "-25.0~+25.0" 77 "-25.0~+25.0" 78 "-25.0~+25.0" 79 "-25.0~+25.0" 80 "-25.0~+25.0" 81 "-25.0~+25.0" 82 "-25.0~+25.0" 83 "-25.0~+25.0" 84 "-25.0~+25.0" 85 "-25.0~+25.0" 86 "-25.0~+25.0" 87 "-25.0~+25.0" 88 "-25.0~+25.0" 89 "-25.0~+25.0" 90 "-25.0~+25.0" 91 "-25.0~+25.0" 92 "-25.0~+25.0" 93 "-25.0~+25.0" 94 "-25.0~+25.0" 95 "-25.0~+25.0" 96 "-25.0~+25.0" 97 "-25.0~+25.0" 98 "-25.0~+25.0" 99 "-25.0~+25.0" 100 "-25.0~+25.0" 101 "-25.0~+25.0" 102 "-25.0~+25.0" 103 "-25.0~+25.0" 104 "-25.0~+25.0" 105 "-25.0~+25.0" 106 "-25.0~+25.0" 107 "-25.0~+25.0" 108 "-25.0~+25.0" 109 "-25.0~+25.0" 110 "-25.0~+25.0" 111 "-25.0~+25.0" 112 "-25.0~+25.0" 113 "-25.0~+25.0" 114 "-25.0~+25.0" 115 "-25.0~+25.0" 116 "-25.0~+25.0" 117 "-25.0~+25.0" 118 "-25.0~+25.0" 119 "-25.0~+25.0" 120 "-25.0~+25.0" 121 "-25.0~+25.0" 122 "-25.0~+25.0" 123 "-25.0~+25.0" 124 "-25.0~+25.0" 125 "-25.0~+25.0" 126 "-25.0~+25.0" 127 "-25.0~+25.0" 128 "-25.0~+25.0" 129 "-25.0~+25.0" 130 "-25.0~+25.0" 131 "-25.0~+25.0" 132 "-25.0~+25.0" 133 "-25.0~+25.0" 134 "-25.0~+25.0" 135 "-25.0~+25.0" 136 "-25.0~+25.0" 137 "-25.0~+25.0" 138 "-25.0~+25.0" 139 "-25.0~+25.0" 140 "-25.0~+25.0" 141 "-25.0~+25.0" 142 "-25.0~+25.0" 143 "-25.0~+25.0" 144 "-25.0~+25.0" 145 "-25.0~+25.0" 146 "-25.0~+25.0" 147 "-25.0~+25.0" 148 "-25.0~+25.0" 149 "-25.0~+25.0" 150 "-25.0~+25.0" 151 "-25.0~+25.0" 152 "-25.0~+25.0" 153 "-25.0~+25.0" 154 "-25.0~+25.0" 155 "-25.0~+25.0" 156 "-25.0~+25.0" 157 "-25.0~+25.0" 158 "-25.0~+25.0" 159 "-25.0~+25.0" 160 "-25.0~+25.0" 161 "-25.0~+25.0" 162 "-25.0~+25.0" 163 "-25.0~+25.0" 164 "-25.0~+25.0" 165 "-25.0~+25.0" 166 "-25.0~+25.0" 167 "-25.0~+25.0" 168 "-25.0~+25.0" 169 "-25.0~+25.0" 170 "-25.0~+25.0" 171 "-25.0~+25.0" 172 "-25.0~+25.0" 173 "-25.0~+25.0" 174 "-25.0~+25.0" 175 "-25.0~+25.0" 176 "-25.0~+25.0" 177 "-25.0~+25.0" 178 "-25.0~+25.0" 179 "-25.0~+25.0" 180 "-25.0~+25.0" 181 "-25.0~+25.0" 182 "-25.0~+25.0" 183 "-25.0~+25.0" 184 "-25.0~+25.0" 185 "-25.0~+25.0" 186 "-25.0~+25.0" 187 "-25.0~+25.0" 188 "-25.0~+25.0" 189 "-25.0~+25.0" 190 "-25.0~+25.0" 191 "-25.0~+25.0" 192 "-25.0~+25.0" 193 "-25.0~+25.0" 194 "-25.0~+25.0" 195 "-25.0~+25.0" 196 "-25.0~+25.0" 197 "-25.0~+25.0" 198 "-25.0~+25.0" 199 "-25.0~+25.0" 200 "-25.0~+25.0" 201 "-25.0~+25.0" 202 "-25.0~+25.0" 203 "-25.0~+25.0" 204 "-25.0~+25.0" 205 "-25.0~+25.0" 206 "-25.0~+25.0" 207 "-25.0~+25.0" 208 "-25.0~+25.0" 209 "-25.0~+25.0" 210 "-25.0~+25.0" 211 "-25.0~+25.0" 212 "-25.0~+25.0" 213 "-25.0~+25.0" 214 "-25.0~+25.0" 215 "-25.0~+25.0" 216 "-25.0~+25.0" 217 "-25.0~+25.0" 218 "-25.0~+25.0" 219 "-25.0~+25.0" 220 "-25.0~+25.0" 221 "-25.0~+25.0" 222 "-25.0~+25.0" 223 "-25.0~+25.0" 224 "-25.0~+25.0" 225 "-25.0~+25.0" 226 "-25.0~+25.0" 227 "-25.0~+25.0" 228 "-25.0~+25.0" 229 "-25.0~+25.0" 230 "-25.0~+25.0" 231 "-25.0~+25.0" 232 "-25.0~+25.0" 233 "-25.0~+25.0" 234 "-25.0~+25.0" 235 "-25.0~+25.0" 236 "-25.0~+25.0" 237 "-25.0~+25.0" 238 "-25.0~+25.0" 239 "-25.0~+25.0" 240 "-25.0~+25.0" 241 "-25.0~+25.0" 242 "-25.0~+25.0" 243 "-25.0~+25.0" 244 "-25.0~+25.0" 245 "-25.0~+25.0" 246 "-25.0~+25.0" 247 "-25.0~+25.0" 248 "-25.0~+25.0" 249 "-25.0~+25.0" 250 "-25.0~+25.0" 251 "-25.0~+25.0" 252 "-25.0~+25.0" 253 "-25.0~+25.0" 254 "-25.0~+25.0" 255 "-25.0~+25.0" 256 "-25.0~+25.0" 257 "-25.0~+25.0" 258 "-25.0~+25.0" 259 "-25.0~+25.0" 260 "-25.0~+25.0" 261 "-25.0~+25.0" 262 "-25.0~+25.0" 263 "-25.0~+25.0" 264 "-25.0~+25.0" 265 "-25.0~+25.0" 266 "-25.0~+25.0" 267 "-25.0~+25.0" 268 "-25.0~+25.0" 269 "-25.0~+25.0" 270 "-25.0~+25.0" 271 "-25.0~+25.0" 272 "-25.0~+25.0" 273 "-25.0~+25.0" 274 "-25.0~+25.0" 275 "-25.0~+25.0" 276 "-25.0~+25.0" 277 "-25.0~+25.0" 278 "-25.0~+25.0" 279 "-25.0~+25.0" 280 "-25.0~+25.0" 281 "-25.0~+25.0" 282 "-25.0~+25.0" 283 "-25.0~+25.0" 284 "-25.0~+25.0" 285 "-25.0~+25.0" 286 "-25.0~+25.0" 287 "-25.0~+25.0" 288 "-25.0~+25.0" 289 "-25.0~+25.0" 290 "-25.0~+25.0" 291 "-25.0~+25.0" 292 "-25.0~+25.0" 293 "-25.0~+25.0" 294 "-25.0~+25.0" 295 "-25.0~+25.0" 296 "-25.0~+25.0" 297 "-25.0~+25.0" 298 "-25.0~+25.0" 299 "-25.0~+25.0" 300 "-25.0~+25.0" 301 "-25.0~+25.0" 302 "-25.0~+25.0" 303 "-25.0~+25.0" 304 "-25.0~+25.0" 305 "-25.0~+25.0" 306 "-25.0~+25.0" 307 "-25.0~+25.0" 308 "-25.0~+25.0" 309 "-25.0~+25.0" 310 "-25.0~+25.0" 311 "-25.0~+25.0" 312 "-25.0~+25.0" 313 "-25.0~+25.0" 314 "-25.0~+25.0" 315 "-25.0~+25.0" 316 "-25.0~+25.0" 317 "-25.0~+25.0" 318 "-25.0~+25.0" 319 "-25.0~+25.0" 320 "-25.0~+25.0" 321 "-25.0~+25.0" 322 "-25.0~+25.0" 323 "-25.0~+25.0" 324 "-25.0~+25.0" 325 "-25.0~+25.0" 326 "-25.0~+25.0" 327 "-25.0~+25.0" 328 "-25.0~+25.0" 329 "-25.0~+25.0" 330 "-25.0~+25.0" 331 "-25.0~+25.0" 332 "-25.0~+25.0" 333 "-25.0~+25.0" 334 "-25.0~+25.0" 335 "-25.0~+25.0" 336 "-25.0~+25.0" 337 "-25.0~+25.0" 338 "-25.0~+25.0" 339 "-25.0~+25.0" 340 "-25.0~+25.0" 341 "-25.0~+25.0" 342 "-25.0~+25.0" 343 "-25.0~+25.0" 344 "-25.0~+25.0" 345 "-25.0~+25.0" 346 "-25.0~+25.0" 347 "-25.0~+25.0" 348 "-25.0~+25.0" 349 "-25.0~+25.0" 350 "-25.0~+25.0" 351 "-25.0~+25.0" 352 "-25.0~+25.0" 353 "-25.0~+25.0" 354 "-25.0~+25.0" 355 "-25.0~+25.0" 356 "-25.0~+25.0" 357 "-25.0~+25.0" 358 "-25.0~+25.0" 359 "-25.0~+25.0" 360 "-25.0~+25.0" 361 "-25.0~+25.0" 362 "-25.0~+25.0" 363 "-25.0~+25.0" 364 "-25.0~+25.0" 365 "-25.0~+25.0" 366 "-25.0~+25.0" 367 "-25.0~+25.0" 368 "-25.0~+25.0" 369 "-25.0~+25.0" 370 "-25.0~+25.0" 371 "-25.0~+25.0" 372 "-25.0~+25.0" 373 "-25.0~+25.0" 374 "-25.0~+25.0" 375 "-25.0~+25.0" 376 "-25.0~+25.0" 377 "-25.0~+25.0" 378 "-25.0~+25.0" 379 "-25.0~+25.0" 380 "-25.0~+25.0" 381 "-25.0~+25.0" 382 "-25.0~+25.0" 383 "-25.0~+25.0" 384 "-25.0~+25.0" 385 "-25.0~+25.0" 386 "-25.0~+25.0" 387 "-25.0~+25.0" 388 "-25.0~+25.0" 389 "-25.0~+25.0" 390 "-25.0~+25.0" 391 "-25.0~+25.0" 392 "-25.0~+25.0" 393 "-25.0~+25.0" 394 "-25.0~+25.0" 395 "-25.0~+25.0" 396 "-25.0~+25.0" 397 "-25.0~+25.0" 398 "-25.0~+25.0" 399 "-25.0~+25.0" 400 "-25.0~+25.0" 401 "-25.0~+25.0" 402 "-25.0~+25.0" 403 "-25.0~+25.0" 404 "-25.0~+25.0" 405 "-25.0~+25.0" 406 "-25.0~+25.0" 407 "-25.0~+25.0" 408 "-25.0~+25.0" 409 "-25.0~+25.0" 410 "-25.0~+25.0" 411 "-25.0~+25.0" 412 "-25.0~+25.0" 413 "-25.0~+25.0" 414 "-25.0~+25.0" 415 "-25.0~+25.0" 416 "-25.0~+25.0" 417 "-25.0~+25.0" 418 "-25.0~+25.0" 419 "-25.0~+25.0" 420 "-25.0~+25.0" 421 "-25.0~+25.0" 422 "-25.0~+25.0" 423 "-25.0~+25.0" 424 "-25.0~+25.0" 425 "-25.0~+25.0" 426 "-25.0~+25.0" 427 "-25.0~+25.0" 428 "-25.0~+25.0" 429 "-25.0~+25.0" 430 "-25.0~+25.0" 431 "-25.0~+25.0" 432 "-25.0~+25.0" 433 "-25.0~+25.0" 434 "-25.0~+25.0" 435 "-25.0~+25.0" 436 "-25.0~+25.0" 437 "-25.0~+25.0" 438 "-25.0~+25.0" 439 "-25.0~+25.0" 440 "-25.0~+25.0" 441 "-25.0~+25.0" 442 "-25.0~+25.0" 443 "-25.0~+25.0" 444 "-25.0~+25.0" 445 "-25.0~+25.0" 446 "-25.0~+25.0" 447 "-25.0~+25.0" 448 "-25.0~+25.0" 449 "-25.0~+25.0" 450 "-25.0~+25.0" 451 "-25.0~+25.0" 452 "-25.0~+25.0" 453 "-25.0~+25.0" 454 "-25.0~+25.0" 455 "-25.0~+25.0" 456 "-25.0~+25.0" 457 "-25.0~+25.0" 458 "-25.0~+25.0" 459 "-25.0~+25.0" 460 "-25.0~+25.0" 461 "-25.0~+25.0" 462 "-25.0~+25.0" 463 "-25.0~+25.0" 464 "-25.0~+25.0" 465 "-25.0~+25.0" 466 "-25.0~+25.0" 467 "-25.0~+25.0" 468 "-25.0~+25.0" 469 "-25.0~+25.0" 470 "-25.0~+25.0" 471 "-25.0~+25.0" 472 "-25.0~+25.0" 473 "-25.0~+25.0" 474 "-25.0~+25.0" 475 "-25.0~+25.0" 476 "-25.0~+25.0" 477 "-25.0~+25.0" 478 "-25.0~+25.0" 479 "-25.0~+25.0" 480 "-25.0~+25.0" 481 "-25.0~+25.0" 482 "-25.0~+25.0" 483 "-25.0~+25.0" 484 "-25.0~+25.0" 485 "-25.0~+25.0" 486 "-25.0~+25.0" 487 "-25.0~+25.0" 488 "-25.0~+25.0" 489 "-25.0~+25.0" 490 "-25.0~+25.0" 491 "-25.0~+25.0" 492 "-25.0~+25.0" 493 "-25.0~+25.0" 494 "-25.0~+25.0" 495 "-25.0~+25.0" 496 "-25.0~+25.0" 497 "-25.0~+25.0" 498 "-25.0~+25.0" 499 "-25.0~+25.0" 500 "-25.0~+25.0" 501 "Not used" 502 "Not used" 503 "Not used" 504 "Not used" 505 "Not used" 506 "Not used" 507 "Not used" 508 "Not used" 509 "Not used" 510 "Default" 511 "Error indicator";
VAL_ 698 IFSref_VehRtAngl5Val 0 "-25.0~+25.0" 1 "-25.0~+25.0" 2 "-25.0~+25.0" 3 "-25.0~+25.0" 4 "-25.0~+25.0" 5 "-25.0~+25.0" 6 "-25.0~+25.0" 7 "-25.0~+25.0" 8 "-25.0~+25.0" 9 "-25.0~+25.0" 10 "-25.0~+25.0" 11 "-25.0~+25.0" 12 "-25.0~+25.0" 13 "-25.0~+25.0" 14 "-25.0~+25.0" 15 "-25.0~+25.0" 16 "-25.0~+25.0" 17 "-25.0~+25.0" 18 "-25.0~+25.0" 19 "-25.0~+25.0" 20 "-25.0~+25.0" 21 "-25.0~+25.0" 22 "-25.0~+25.0" 23 "-25.0~+25.0" 24 "-25.0~+25.0" 25 "-25.0~+25.0" 26 "-25.0~+25.0" 27 "-25.0~+25.0" 28 "-25.0~+25.0" 29 "-25.0~+25.0" 30 "-25.0~+25.0" 31 "-25.0~+25.0" 32 "-25.0~+25.0" 33 "-25.0~+25.0" 34 "-25.0~+25.0" 35 "-25.0~+25.0" 36 "-25.0~+25.0" 37 "-25.0~+25.0" 38 "-25.0~+25.0" 39 "-25.0~+25.0" 40 "-25.0~+25.0" 41 "-25.0~+25.0" 42 "-25.0~+25.0" 43 "-25.0~+25.0" 44 "-25.0~+25.0" 45 "-25.0~+25.0" 46 "-25.0~+25.0" 47 "-25.0~+25.0" 48 "-25.0~+25.0" 49 "-25.0~+25.0" 50 "-25.0~+25.0" 51 "-25.0~+25.0" 52 "-25.0~+25.0" 53 "-25.0~+25.0" 54 "-25.0~+25.0" 55 "-25.0~+25.0" 56 "-25.0~+25.0" 57 "-25.0~+25.0" 58 "-25.0~+25.0" 59 "-25.0~+25.0" 60 "-25.0~+25.0" 61 "-25.0~+25.0" 62 "-25.0~+25.0" 63 "-25.0~+25.0" 64 "-25.0~+25.0" 65 "-25.0~+25.0" 66 "-25.0~+25.0" 67 "-25.0~+25.0" 68 "-25.0~+25.0" 69 "-25.0~+25.0" 70 "-25.0~+25.0" 71 "-25.0~+25.0" 72 "-25.0~+25.0" 73 "-25.0~+25.0" 74 "-25.0~+25.0" 75 "-25.0~+25.0" 76 "-25.0~+25.0" 77 "-25.0~+25.0" 78 "-25.0~+25.0" 79 "-25.0~+25.0" 80 "-25.0~+25.0" 81 "-25.0~+25.0" 82 "-25.0~+25.0" 83 "-25.0~+25.0" 84 "-25.0~+25.0" 85 "-25.0~+25.0" 86 "-25.0~+25.0" 87 "-25.0~+25.0" 88 "-25.0~+25.0" 89 "-25.0~+25.0" 90 "-25.0~+25.0" 91 "-25.0~+25.0" 92 "-25.0~+25.0" 93 "-25.0~+25.0" 94 "-25.0~+25.0" 95 "-25.0~+25.0" 96 "-25.0~+25.0" 97 "-25.0~+25.0" 98 "-25.0~+25.0" 99 "-25.0~+25.0" 100 "-25.0~+25.0" 101 "-25.0~+25.0" 102 "-25.0~+25.0" 103 "-25.0~+25.0" 104 "-25.0~+25.0" 105 "-25.0~+25.0" 106 "-25.0~+25.0" 107 "-25.0~+25.0" 108 "-25.0~+25.0" 109 "-25.0~+25.0" 110 "-25.0~+25.0" 111 "-25.0~+25.0" 112 "-25.0~+25.0" 113 "-25.0~+25.0" 114 "-25.0~+25.0" 115 "-25.0~+25.0" 116 "-25.0~+25.0" 117 "-25.0~+25.0" 118 "-25.0~+25.0" 119 "-25.0~+25.0" 120 "-25.0~+25.0" 121 "-25.0~+25.0" 122 "-25.0~+25.0" 123 "-25.0~+25.0" 124 "-25.0~+25.0" 125 "-25.0~+25.0" 126 "-25.0~+25.0" 127 "-25.0~+25.0" 128 "-25.0~+25.0" 129 "-25.0~+25.0" 130 "-25.0~+25.0" 131 "-25.0~+25.0" 132 "-25.0~+25.0" 133 "-25.0~+25.0" 134 "-25.0~+25.0" 135 "-25.0~+25.0" 136 "-25.0~+25.0" 137 "-25.0~+25.0" 138 "-25.0~+25.0" 139 "-25.0~+25.0" 140 "-25.0~+25.0" 141 "-25.0~+25.0" 142 "-25.0~+25.0" 143 "-25.0~+25.0" 144 "-25.0~+25.0" 145 "-25.0~+25.0" 146 "-25.0~+25.0" 147 "-25.0~+25.0" 148 "-25.0~+25.0" 149 "-25.0~+25.0" 150 "-25.0~+25.0" 151 "-25.0~+25.0" 152 "-25.0~+25.0" 153 "-25.0~+25.0" 154 "-25.0~+25.0" 155 "-25.0~+25.0" 156 "-25.0~+25.0" 157 "-25.0~+25.0" 158 "-25.0~+25.0" 159 "-25.0~+25.0" 160 "-25.0~+25.0" 161 "-25.0~+25.0" 162 "-25.0~+25.0" 163 "-25.0~+25.0" 164 "-25.0~+25.0" 165 "-25.0~+25.0" 166 "-25.0~+25.0" 167 "-25.0~+25.0" 168 "-25.0~+25.0" 169 "-25.0~+25.0" 170 "-25.0~+25.0" 171 "-25.0~+25.0" 172 "-25.0~+25.0" 173 "-25.0~+25.0" 174 "-25.0~+25.0" 175 "-25.0~+25.0" 176 "-25.0~+25.0" 177 "-25.0~+25.0" 178 "-25.0~+25.0" 179 "-25.0~+25.0" 180 "-25.0~+25.0" 181 "-25.0~+25.0" 182 "-25.0~+25.0" 183 "-25.0~+25.0" 184 "-25.0~+25.0" 185 "-25.0~+25.0" 186 "-25.0~+25.0" 187 "-25.0~+25.0" 188 "-25.0~+25.0" 189 "-25.0~+25.0" 190 "-25.0~+25.0" 191 "-25.0~+25.0" 192 "-25.0~+25.0" 193 "-25.0~+25.0" 194 "-25.0~+25.0" 195 "-25.0~+25.0" 196 "-25.0~+25.0" 197 "-25.0~+25.0" 198 "-25.0~+25.0" 199 "-25.0~+25.0" 200 "-25.0~+25.0" 201 "-25.0~+25.0" 202 "-25.0~+25.0" 203 "-25.0~+25.0" 204 "-25.0~+25.0" 205 "-25.0~+25.0" 206 "-25.0~+25.0" 207 "-25.0~+25.0" 208 "-25.0~+25.0" 209 "-25.0~+25.0" 210 "-25.0~+25.0" 211 "-25.0~+25.0" 212 "-25.0~+25.0" 213 "-25.0~+25.0" 214 "-25.0~+25.0" 215 "-25.0~+25.0" 216 "-25.0~+25.0" 217 "-25.0~+25.0" 218 "-25.0~+25.0" 219 "-25.0~+25.0" 220 "-25.0~+25.0" 221 "-25.0~+25.0" 222 "-25.0~+25.0" 223 "-25.0~+25.0" 224 "-25.0~+25.0" 225 "-25.0~+25.0" 226 "-25.0~+25.0" 227 "-25.0~+25.0" 228 "-25.0~+25.0" 229 "-25.0~+25.0" 230 "-25.0~+25.0" 231 "-25.0~+25.0" 232 "-25.0~+25.0" 233 "-25.0~+25.0" 234 "-25.0~+25.0" 235 "-25.0~+25.0" 236 "-25.0~+25.0" 237 "-25.0~+25.0" 238 "-25.0~+25.0" 239 "-25.0~+25.0" 240 "-25.0~+25.0" 241 "-25.0~+25.0" 242 "-25.0~+25.0" 243 "-25.0~+25.0" 244 "-25.0~+25.0" 245 "-25.0~+25.0" 246 "-25.0~+25.0" 247 "-25.0~+25.0" 248 "-25.0~+25.0" 249 "-25.0~+25.0" 250 "-25.0~+25.0" 251 "-25.0~+25.0" 252 "-25.0~+25.0" 253 "-25.0~+25.0" 254 "-25.0~+25.0" 255 "-25.0~+25.0" 256 "-25.0~+25.0" 257 "-25.0~+25.0" 258 "-25.0~+25.0" 259 "-25.0~+25.0" 260 "-25.0~+25.0" 261 "-25.0~+25.0" 262 "-25.0~+25.0" 263 "-25.0~+25.0" 264 "-25.0~+25.0" 265 "-25.0~+25.0" 266 "-25.0~+25.0" 267 "-25.0~+25.0" 268 "-25.0~+25.0" 269 "-25.0~+25.0" 270 "-25.0~+25.0" 271 "-25.0~+25.0" 272 "-25.0~+25.0" 273 "-25.0~+25.0" 274 "-25.0~+25.0" 275 "-25.0~+25.0" 276 "-25.0~+25.0" 277 "-25.0~+25.0" 278 "-25.0~+25.0" 279 "-25.0~+25.0" 280 "-25.0~+25.0" 281 "-25.0~+25.0" 282 "-25.0~+25.0" 283 "-25.0~+25.0" 284 "-25.0~+25.0" 285 "-25.0~+25.0" 286 "-25.0~+25.0" 287 "-25.0~+25.0" 288 "-25.0~+25.0" 289 "-25.0~+25.0" 290 "-25.0~+25.0" 291 "-25.0~+25.0" 292 "-25.0~+25.0" 293 "-25.0~+25.0" 294 "-25.0~+25.0" 295 "-25.0~+25.0" 296 "-25.0~+25.0" 297 "-25.0~+25.0" 298 "-25.0~+25.0" 299 "-25.0~+25.0" 300 "-25.0~+25.0" 301 "-25.0~+25.0" 302 "-25.0~+25.0" 303 "-25.0~+25.0" 304 "-25.0~+25.0" 305 "-25.0~+25.0" 306 "-25.0~+25.0" 307 "-25.0~+25.0" 308 "-25.0~+25.0" 309 "-25.0~+25.0" 310 "-25.0~+25.0" 311 "-25.0~+25.0" 312 "-25.0~+25.0" 313 "-25.0~+25.0" 314 "-25.0~+25.0" 315 "-25.0~+25.0" 316 "-25.0~+25.0" 317 "-25.0~+25.0" 318 "-25.0~+25.0" 319 "-25.0~+25.0" 320 "-25.0~+25.0" 321 "-25.0~+25.0" 322 "-25.0~+25.0" 323 "-25.0~+25.0" 324 "-25.0~+25.0" 325 "-25.0~+25.0" 326 "-25.0~+25.0" 327 "-25.0~+25.0" 328 "-25.0~+25.0" 329 "-25.0~+25.0" 330 "-25.0~+25.0" 331 "-25.0~+25.0" 332 "-25.0~+25.0" 333 "-25.0~+25.0" 334 "-25.0~+25.0" 335 "-25.0~+25.0" 336 "-25.0~+25.0" 337 "-25.0~+25.0" 338 "-25.0~+25.0" 339 "-25.0~+25.0" 340 "-25.0~+25.0" 341 "-25.0~+25.0" 342 "-25.0~+25.0" 343 "-25.0~+25.0" 344 "-25.0~+25.0" 345 "-25.0~+25.0" 346 "-25.0~+25.0" 347 "-25.0~+25.0" 348 "-25.0~+25.0" 349 "-25.0~+25.0" 350 "-25.0~+25.0" 351 "-25.0~+25.0" 352 "-25.0~+25.0" 353 "-25.0~+25.0" 354 "-25.0~+25.0" 355 "-25.0~+25.0" 356 "-25.0~+25.0" 357 "-25.0~+25.0" 358 "-25.0~+25.0" 359 "-25.0~+25.0" 360 "-25.0~+25.0" 361 "-25.0~+25.0" 362 "-25.0~+25.0" 363 "-25.0~+25.0" 364 "-25.0~+25.0" 365 "-25.0~+25.0" 366 "-25.0~+25.0" 367 "-25.0~+25.0" 368 "-25.0~+25.0" 369 "-25.0~+25.0" 370 "-25.0~+25.0" 371 "-25.0~+25.0" 372 "-25.0~+25.0" 373 "-25.0~+25.0" 374 "-25.0~+25.0" 375 "-25.0~+25.0" 376 "-25.0~+25.0" 377 "-25.0~+25.0" 378 "-25.0~+25.0" 379 "-25.0~+25.0" 380 "-25.0~+25.0" 381 "-25.0~+25.0" 382 "-25.0~+25.0" 383 "-25.0~+25.0" 384 "-25.0~+25.0" 385 "-25.0~+25.0" 386 "-25.0~+25.0" 387 "-25.0~+25.0" 388 "-25.0~+25.0" 389 "-25.0~+25.0" 390 "-25.0~+25.0" 391 "-25.0~+25.0" 392 "-25.0~+25.0" 393 "-25.0~+25.0" 394 "-25.0~+25.0" 395 "-25.0~+25.0" 396 "-25.0~+25.0" 397 "-25.0~+25.0" 398 "-25.0~+25.0" 399 "-25.0~+25.0" 400 "-25.0~+25.0" 401 "-25.0~+25.0" 402 "-25.0~+25.0" 403 "-25.0~+25.0" 404 "-25.0~+25.0" 405 "-25.0~+25.0" 406 "-25.0~+25.0" 407 "-25.0~+25.0" 408 "-25.0~+25.0" 409 "-25.0~+25.0" 410 "-25.0~+25.0" 411 "-25.0~+25.0" 412 "-25.0~+25.0" 413 "-25.0~+25.0" 414 "-25.0~+25.0" 415 "-25.0~+25.0" 416 "-25.0~+25.0" 417 "-25.0~+25.0" 418 "-25.0~+25.0" 419 "-25.0~+25.0" 420 "-25.0~+25.0" 421 "-25.0~+25.0" 422 "-25.0~+25.0" 423 "-25.0~+25.0" 424 "-25.0~+25.0" 425 "-25.0~+25.0" 426 "-25.0~+25.0" 427 "-25.0~+25.0" 428 "-25.0~+25.0" 429 "-25.0~+25.0" 430 "-25.0~+25.0" 431 "-25.0~+25.0" 432 "-25.0~+25.0" 433 "-25.0~+25.0" 434 "-25.0~+25.0" 435 "-25.0~+25.0" 436 "-25.0~+25.0" 437 "-25.0~+25.0" 438 "-25.0~+25.0" 439 "-25.0~+25.0" 440 "-25.0~+25.0" 441 "-25.0~+25.0" 442 "-25.0~+25.0" 443 "-25.0~+25.0" 444 "-25.0~+25.0" 445 "-25.0~+25.0" 446 "-25.0~+25.0" 447 "-25.0~+25.0" 448 "-25.0~+25.0" 449 "-25.0~+25.0" 450 "-25.0~+25.0" 451 "-25.0~+25.0" 452 "-25.0~+25.0" 453 "-25.0~+25.0" 454 "-25.0~+25.0" 455 "-25.0~+25.0" 456 "-25.0~+25.0" 457 "-25.0~+25.0" 458 "-25.0~+25.0" 459 "-25.0~+25.0" 460 "-25.0~+25.0" 461 "-25.0~+25.0" 462 "-25.0~+25.0" 463 "-25.0~+25.0" 464 "-25.0~+25.0" 465 "-25.0~+25.0" 466 "-25.0~+25.0" 467 "-25.0~+25.0" 468 "-25.0~+25.0" 469 "-25.0~+25.0" 470 "-25.0~+25.0" 471 "-25.0~+25.0" 472 "-25.0~+25.0" 473 "-25.0~+25.0" 474 "-25.0~+25.0" 475 "-25.0~+25.0" 476 "-25.0~+25.0" 477 "-25.0~+25.0" 478 "-25.0~+25.0" 479 "-25.0~+25.0" 480 "-25.0~+25.0" 481 "-25.0~+25.0" 482 "-25.0~+25.0" 483 "-25.0~+25.0" 484 "-25.0~+25.0" 485 "-25.0~+25.0" 486 "-25.0~+25.0" 487 "-25.0~+25.0" 488 "-25.0~+25.0" 489 "-25.0~+25.0" 490 "-25.0~+25.0" 491 "-25.0~+25.0" 492 "-25.0~+25.0" 493 "-25.0~+25.0" 494 "-25.0~+25.0" 495 "-25.0~+25.0" 496 "-25.0~+25.0" 497 "-25.0~+25.0" 498 "-25.0~+25.0" 499 "-25.0~+25.0" 500 "-25.0~+25.0" 501 "Not used" 502 "Not used" 503 "Not used" 504 "Not used" 505 "Not used" 506 "Not used" 507 "Not used" 508 "Not used" 509 "Not used" 510 "Default" 511 "Error indicator";
VAL_ 698 IFSref_VehLftAngl6Val 0 "-25.0~+25.0" 1 "-25.0~+25.0" 2 "-25.0~+25.0" 3 "-25.0~+25.0" 4 "-25.0~+25.0" 5 "-25.0~+25.0" 6 "-25.0~+25.0" 7 "-25.0~+25.0" 8 "-25.0~+25.0" 9 "-25.0~+25.0" 10 "-25.0~+25.0" 11 "-25.0~+25.0" 12 "-25.0~+25.0" 13 "-25.0~+25.0" 14 "-25.0~+25.0" 15 "-25.0~+25.0" 16 "-25.0~+25.0" 17 "-25.0~+25.0" 18 "-25.0~+25.0" 19 "-25.0~+25.0" 20 "-25.0~+25.0" 21 "-25.0~+25.0" 22 "-25.0~+25.0" 23 "-25.0~+25.0" 24 "-25.0~+25.0" 25 "-25.0~+25.0" 26 "-25.0~+25.0" 27 "-25.0~+25.0" 28 "-25.0~+25.0" 29 "-25.0~+25.0" 30 "-25.0~+25.0" 31 "-25.0~+25.0" 32 "-25.0~+25.0" 33 "-25.0~+25.0" 34 "-25.0~+25.0" 35 "-25.0~+25.0" 36 "-25.0~+25.0" 37 "-25.0~+25.0" 38 "-25.0~+25.0" 39 "-25.0~+25.0" 40 "-25.0~+25.0" 41 "-25.0~+25.0" 42 "-25.0~+25.0" 43 "-25.0~+25.0" 44 "-25.0~+25.0" 45 "-25.0~+25.0" 46 "-25.0~+25.0" 47 "-25.0~+25.0" 48 "-25.0~+25.0" 49 "-25.0~+25.0" 50 "-25.0~+25.0" 51 "-25.0~+25.0" 52 "-25.0~+25.0" 53 "-25.0~+25.0" 54 "-25.0~+25.0" 55 "-25.0~+25.0" 56 "-25.0~+25.0" 57 "-25.0~+25.0" 58 "-25.0~+25.0" 59 "-25.0~+25.0" 60 "-25.0~+25.0" 61 "-25.0~+25.0" 62 "-25.0~+25.0" 63 "-25.0~+25.0" 64 "-25.0~+25.0" 65 "-25.0~+25.0" 66 "-25.0~+25.0" 67 "-25.0~+25.0" 68 "-25.0~+25.0" 69 "-25.0~+25.0" 70 "-25.0~+25.0" 71 "-25.0~+25.0" 72 "-25.0~+25.0" 73 "-25.0~+25.0" 74 "-25.0~+25.0" 75 "-25.0~+25.0" 76 "-25.0~+25.0" 77 "-25.0~+25.0" 78 "-25.0~+25.0" 79 "-25.0~+25.0" 80 "-25.0~+25.0" 81 "-25.0~+25.0" 82 "-25.0~+25.0" 83 "-25.0~+25.0" 84 "-25.0~+25.0" 85 "-25.0~+25.0" 86 "-25.0~+25.0" 87 "-25.0~+25.0" 88 "-25.0~+25.0" 89 "-25.0~+25.0" 90 "-25.0~+25.0" 91 "-25.0~+25.0" 92 "-25.0~+25.0" 93 "-25.0~+25.0" 94 "-25.0~+25.0" 95 "-25.0~+25.0" 96 "-25.0~+25.0" 97 "-25.0~+25.0" 98 "-25.0~+25.0" 99 "-25.0~+25.0" 100 "-25.0~+25.0" 101 "-25.0~+25.0" 102 "-25.0~+25.0" 103 "-25.0~+25.0" 104 "-25.0~+25.0" 105 "-25.0~+25.0" 106 "-25.0~+25.0" 107 "-25.0~+25.0" 108 "-25.0~+25.0" 109 "-25.0~+25.0" 110 "-25.0~+25.0" 111 "-25.0~+25.0" 112 "-25.0~+25.0" 113 "-25.0~+25.0" 114 "-25.0~+25.0" 115 "-25.0~+25.0" 116 "-25.0~+25.0" 117 "-25.0~+25.0" 118 "-25.0~+25.0" 119 "-25.0~+25.0" 120 "-25.0~+25.0" 121 "-25.0~+25.0" 122 "-25.0~+25.0" 123 "-25.0~+25.0" 124 "-25.0~+25.0" 125 "-25.0~+25.0" 126 "-25.0~+25.0" 127 "-25.0~+25.0" 128 "-25.0~+25.0" 129 "-25.0~+25.0" 130 "-25.0~+25.0" 131 "-25.0~+25.0" 132 "-25.0~+25.0" 133 "-25.0~+25.0" 134 "-25.0~+25.0" 135 "-25.0~+25.0" 136 "-25.0~+25.0" 137 "-25.0~+25.0" 138 "-25.0~+25.0" 139 "-25.0~+25.0" 140 "-25.0~+25.0" 141 "-25.0~+25.0" 142 "-25.0~+25.0" 143 "-25.0~+25.0" 144 "-25.0~+25.0" 145 "-25.0~+25.0" 146 "-25.0~+25.0" 147 "-25.0~+25.0" 148 "-25.0~+25.0" 149 "-25.0~+25.0" 150 "-25.0~+25.0" 151 "-25.0~+25.0" 152 "-25.0~+25.0" 153 "-25.0~+25.0" 154 "-25.0~+25.0" 155 "-25.0~+25.0" 156 "-25.0~+25.0" 157 "-25.0~+25.0" 158 "-25.0~+25.0" 159 "-25.0~+25.0" 160 "-25.0~+25.0" 161 "-25.0~+25.0" 162 "-25.0~+25.0" 163 "-25.0~+25.0" 164 "-25.0~+25.0" 165 "-25.0~+25.0" 166 "-25.0~+25.0" 167 "-25.0~+25.0" 168 "-25.0~+25.0" 169 "-25.0~+25.0" 170 "-25.0~+25.0" 171 "-25.0~+25.0" 172 "-25.0~+25.0" 173 "-25.0~+25.0" 174 "-25.0~+25.0" 175 "-25.0~+25.0" 176 "-25.0~+25.0" 177 "-25.0~+25.0" 178 "-25.0~+25.0" 179 "-25.0~+25.0" 180 "-25.0~+25.0" 181 "-25.0~+25.0" 182 "-25.0~+25.0" 183 "-25.0~+25.0" 184 "-25.0~+25.0" 185 "-25.0~+25.0" 186 "-25.0~+25.0" 187 "-25.0~+25.0" 188 "-25.0~+25.0" 189 "-25.0~+25.0" 190 "-25.0~+25.0" 191 "-25.0~+25.0" 192 "-25.0~+25.0" 193 "-25.0~+25.0" 194 "-25.0~+25.0" 195 "-25.0~+25.0" 196 "-25.0~+25.0" 197 "-25.0~+25.0" 198 "-25.0~+25.0" 199 "-25.0~+25.0" 200 "-25.0~+25.0" 201 "-25.0~+25.0" 202 "-25.0~+25.0" 203 "-25.0~+25.0" 204 "-25.0~+25.0" 205 "-25.0~+25.0" 206 "-25.0~+25.0" 207 "-25.0~+25.0" 208 "-25.0~+25.0" 209 "-25.0~+25.0" 210 "-25.0~+25.0" 211 "-25.0~+25.0" 212 "-25.0~+25.0" 213 "-25.0~+25.0" 214 "-25.0~+25.0" 215 "-25.0~+25.0" 216 "-25.0~+25.0" 217 "-25.0~+25.0" 218 "-25.0~+25.0" 219 "-25.0~+25.0" 220 "-25.0~+25.0" 221 "-25.0~+25.0" 222 "-25.0~+25.0" 223 "-25.0~+25.0" 224 "-25.0~+25.0" 225 "-25.0~+25.0" 226 "-25.0~+25.0" 227 "-25.0~+25.0" 228 "-25.0~+25.0" 229 "-25.0~+25.0" 230 "-25.0~+25.0" 231 "-25.0~+25.0" 232 "-25.0~+25.0" 233 "-25.0~+25.0" 234 "-25.0~+25.0" 235 "-25.0~+25.0" 236 "-25.0~+25.0" 237 "-25.0~+25.0" 238 "-25.0~+25.0" 239 "-25.0~+25.0" 240 "-25.0~+25.0" 241 "-25.0~+25.0" 242 "-25.0~+25.0" 243 "-25.0~+25.0" 244 "-25.0~+25.0" 245 "-25.0~+25.0" 246 "-25.0~+25.0" 247 "-25.0~+25.0" 248 "-25.0~+25.0" 249 "-25.0~+25.0" 250 "-25.0~+25.0" 251 "-25.0~+25.0" 252 "-25.0~+25.0" 253 "-25.0~+25.0" 254 "-25.0~+25.0" 255 "-25.0~+25.0" 256 "-25.0~+25.0" 257 "-25.0~+25.0" 258 "-25.0~+25.0" 259 "-25.0~+25.0" 260 "-25.0~+25.0" 261 "-25.0~+25.0" 262 "-25.0~+25.0" 263 "-25.0~+25.0" 264 "-25.0~+25.0" 265 "-25.0~+25.0" 266 "-25.0~+25.0" 267 "-25.0~+25.0" 268 "-25.0~+25.0" 269 "-25.0~+25.0" 270 "-25.0~+25.0" 271 "-25.0~+25.0" 272 "-25.0~+25.0" 273 "-25.0~+25.0" 274 "-25.0~+25.0" 275 "-25.0~+25.0" 276 "-25.0~+25.0" 277 "-25.0~+25.0" 278 "-25.0~+25.0" 279 "-25.0~+25.0" 280 "-25.0~+25.0" 281 "-25.0~+25.0" 282 "-25.0~+25.0" 283 "-25.0~+25.0" 284 "-25.0~+25.0" 285 "-25.0~+25.0" 286 "-25.0~+25.0" 287 "-25.0~+25.0" 288 "-25.0~+25.0" 289 "-25.0~+25.0" 290 "-25.0~+25.0" 291 "-25.0~+25.0" 292 "-25.0~+25.0" 293 "-25.0~+25.0" 294 "-25.0~+25.0" 295 "-25.0~+25.0" 296 "-25.0~+25.0" 297 "-25.0~+25.0" 298 "-25.0~+25.0" 299 "-25.0~+25.0" 300 "-25.0~+25.0" 301 "-25.0~+25.0" 302 "-25.0~+25.0" 303 "-25.0~+25.0" 304 "-25.0~+25.0" 305 "-25.0~+25.0" 306 "-25.0~+25.0" 307 "-25.0~+25.0" 308 "-25.0~+25.0" 309 "-25.0~+25.0" 310 "-25.0~+25.0" 311 "-25.0~+25.0" 312 "-25.0~+25.0" 313 "-25.0~+25.0" 314 "-25.0~+25.0" 315 "-25.0~+25.0" 316 "-25.0~+25.0" 317 "-25.0~+25.0" 318 "-25.0~+25.0" 319 "-25.0~+25.0" 320 "-25.0~+25.0" 321 "-25.0~+25.0" 322 "-25.0~+25.0" 323 "-25.0~+25.0" 324 "-25.0~+25.0" 325 "-25.0~+25.0" 326 "-25.0~+25.0" 327 "-25.0~+25.0" 328 "-25.0~+25.0" 329 "-25.0~+25.0" 330 "-25.0~+25.0" 331 "-25.0~+25.0" 332 "-25.0~+25.0" 333 "-25.0~+25.0" 334 "-25.0~+25.0" 335 "-25.0~+25.0" 336 "-25.0~+25.0" 337 "-25.0~+25.0" 338 "-25.0~+25.0" 339 "-25.0~+25.0" 340 "-25.0~+25.0" 341 "-25.0~+25.0" 342 "-25.0~+25.0" 343 "-25.0~+25.0" 344 "-25.0~+25.0" 345 "-25.0~+25.0" 346 "-25.0~+25.0" 347 "-25.0~+25.0" 348 "-25.0~+25.0" 349 "-25.0~+25.0" 350 "-25.0~+25.0" 351 "-25.0~+25.0" 352 "-25.0~+25.0" 353 "-25.0~+25.0" 354 "-25.0~+25.0" 355 "-25.0~+25.0" 356 "-25.0~+25.0" 357 "-25.0~+25.0" 358 "-25.0~+25.0" 359 "-25.0~+25.0" 360 "-25.0~+25.0" 361 "-25.0~+25.0" 362 "-25.0~+25.0" 363 "-25.0~+25.0" 364 "-25.0~+25.0" 365 "-25.0~+25.0" 366 "-25.0~+25.0" 367 "-25.0~+25.0" 368 "-25.0~+25.0" 369 "-25.0~+25.0" 370 "-25.0~+25.0" 371 "-25.0~+25.0" 372 "-25.0~+25.0" 373 "-25.0~+25.0" 374 "-25.0~+25.0" 375 "-25.0~+25.0" 376 "-25.0~+25.0" 377 "-25.0~+25.0" 378 "-25.0~+25.0" 379 "-25.0~+25.0" 380 "-25.0~+25.0" 381 "-25.0~+25.0" 382 "-25.0~+25.0" 383 "-25.0~+25.0" 384 "-25.0~+25.0" 385 "-25.0~+25.0" 386 "-25.0~+25.0" 387 "-25.0~+25.0" 388 "-25.0~+25.0" 389 "-25.0~+25.0" 390 "-25.0~+25.0" 391 "-25.0~+25.0" 392 "-25.0~+25.0" 393 "-25.0~+25.0" 394 "-25.0~+25.0" 395 "-25.0~+25.0" 396 "-25.0~+25.0" 397 "-25.0~+25.0" 398 "-25.0~+25.0" 399 "-25.0~+25.0" 400 "-25.0~+25.0" 401 "-25.0~+25.0" 402 "-25.0~+25.0" 403 "-25.0~+25.0" 404 "-25.0~+25.0" 405 "-25.0~+25.0" 406 "-25.0~+25.0" 407 "-25.0~+25.0" 408 "-25.0~+25.0" 409 "-25.0~+25.0" 410 "-25.0~+25.0" 411 "-25.0~+25.0" 412 "-25.0~+25.0" 413 "-25.0~+25.0" 414 "-25.0~+25.0" 415 "-25.0~+25.0" 416 "-25.0~+25.0" 417 "-25.0~+25.0" 418 "-25.0~+25.0" 419 "-25.0~+25.0" 420 "-25.0~+25.0" 421 "-25.0~+25.0" 422 "-25.0~+25.0" 423 "-25.0~+25.0" 424 "-25.0~+25.0" 425 "-25.0~+25.0" 426 "-25.0~+25.0" 427 "-25.0~+25.0" 428 "-25.0~+25.0" 429 "-25.0~+25.0" 430 "-25.0~+25.0" 431 "-25.0~+25.0" 432 "-25.0~+25.0" 433 "-25.0~+25.0" 434 "-25.0~+25.0" 435 "-25.0~+25.0" 436 "-25.0~+25.0" 437 "-25.0~+25.0" 438 "-25.0~+25.0" 439 "-25.0~+25.0" 440 "-25.0~+25.0" 441 "-25.0~+25.0" 442 "-25.0~+25.0" 443 "-25.0~+25.0" 444 "-25.0~+25.0" 445 "-25.0~+25.0" 446 "-25.0~+25.0" 447 "-25.0~+25.0" 448 "-25.0~+25.0" 449 "-25.0~+25.0" 450 "-25.0~+25.0" 451 "-25.0~+25.0" 452 "-25.0~+25.0" 453 "-25.0~+25.0" 454 "-25.0~+25.0" 455 "-25.0~+25.0" 456 "-25.0~+25.0" 457 "-25.0~+25.0" 458 "-25.0~+25.0" 459 "-25.0~+25.0" 460 "-25.0~+25.0" 461 "-25.0~+25.0" 462 "-25.0~+25.0" 463 "-25.0~+25.0" 464 "-25.0~+25.0" 465 "-25.0~+25.0" 466 "-25.0~+25.0" 467 "-25.0~+25.0" 468 "-25.0~+25.0" 469 "-25.0~+25.0" 470 "-25.0~+25.0" 471 "-25.0~+25.0" 472 "-25.0~+25.0" 473 "-25.0~+25.0" 474 "-25.0~+25.0" 475 "-25.0~+25.0" 476 "-25.0~+25.0" 477 "-25.0~+25.0" 478 "-25.0~+25.0" 479 "-25.0~+25.0" 480 "-25.0~+25.0" 481 "-25.0~+25.0" 482 "-25.0~+25.0" 483 "-25.0~+25.0" 484 "-25.0~+25.0" 485 "-25.0~+25.0" 486 "-25.0~+25.0" 487 "-25.0~+25.0" 488 "-25.0~+25.0" 489 "-25.0~+25.0" 490 "-25.0~+25.0" 491 "-25.0~+25.0" 492 "-25.0~+25.0" 493 "-25.0~+25.0" 494 "-25.0~+25.0" 495 "-25.0~+25.0" 496 "-25.0~+25.0" 497 "-25.0~+25.0" 498 "-25.0~+25.0" 499 "-25.0~+25.0" 500 "-25.0~+25.0" 501 "Not used" 502 "Not used" 503 "Not used" 504 "Not used" 505 "Not used" 506 "Not used" 507 "Not used" 508 "Not used" 509 "Not used" 510 "Default" 511 "Error indicator";
VAL_ 698 IFSref_VehRtAngl6Val 0 "-25.0~+25.0" 1 "-25.0~+25.0" 2 "-25.0~+25.0" 3 "-25.0~+25.0" 4 "-25.0~+25.0" 5 "-25.0~+25.0" 6 "-25.0~+25.0" 7 "-25.0~+25.0" 8 "-25.0~+25.0" 9 "-25.0~+25.0" 10 "-25.0~+25.0" 11 "-25.0~+25.0" 12 "-25.0~+25.0" 13 "-25.0~+25.0" 14 "-25.0~+25.0" 15 "-25.0~+25.0" 16 "-25.0~+25.0" 17 "-25.0~+25.0" 18 "-25.0~+25.0" 19 "-25.0~+25.0" 20 "-25.0~+25.0" 21 "-25.0~+25.0" 22 "-25.0~+25.0" 23 "-25.0~+25.0" 24 "-25.0~+25.0" 25 "-25.0~+25.0" 26 "-25.0~+25.0" 27 "-25.0~+25.0" 28 "-25.0~+25.0" 29 "-25.0~+25.0" 30 "-25.0~+25.0" 31 "-25.0~+25.0" 32 "-25.0~+25.0" 33 "-25.0~+25.0" 34 "-25.0~+25.0" 35 "-25.0~+25.0" 36 "-25.0~+25.0" 37 "-25.0~+25.0" 38 "-25.0~+25.0" 39 "-25.0~+25.0" 40 "-25.0~+25.0" 41 "-25.0~+25.0" 42 "-25.0~+25.0" 43 "-25.0~+25.0" 44 "-25.0~+25.0" 45 "-25.0~+25.0" 46 "-25.0~+25.0" 47 "-25.0~+25.0" 48 "-25.0~+25.0" 49 "-25.0~+25.0" 50 "-25.0~+25.0" 51 "-25.0~+25.0" 52 "-25.0~+25.0" 53 "-25.0~+25.0" 54 "-25.0~+25.0" 55 "-25.0~+25.0" 56 "-25.0~+25.0" 57 "-25.0~+25.0" 58 "-25.0~+25.0" 59 "-25.0~+25.0" 60 "-25.0~+25.0" 61 "-25.0~+25.0" 62 "-25.0~+25.0" 63 "-25.0~+25.0" 64 "-25.0~+25.0" 65 "-25.0~+25.0" 66 "-25.0~+25.0" 67 "-25.0~+25.0" 68 "-25.0~+25.0" 69 "-25.0~+25.0" 70 "-25.0~+25.0" 71 "-25.0~+25.0" 72 "-25.0~+25.0" 73 "-25.0~+25.0" 74 "-25.0~+25.0" 75 "-25.0~+25.0" 76 "-25.0~+25.0" 77 "-25.0~+25.0" 78 "-25.0~+25.0" 79 "-25.0~+25.0" 80 "-25.0~+25.0" 81 "-25.0~+25.0" 82 "-25.0~+25.0" 83 "-25.0~+25.0" 84 "-25.0~+25.0" 85 "-25.0~+25.0" 86 "-25.0~+25.0" 87 "-25.0~+25.0" 88 "-25.0~+25.0" 89 "-25.0~+25.0" 90 "-25.0~+25.0" 91 "-25.0~+25.0" 92 "-25.0~+25.0" 93 "-25.0~+25.0" 94 "-25.0~+25.0" 95 "-25.0~+25.0" 96 "-25.0~+25.0" 97 "-25.0~+25.0" 98 "-25.0~+25.0" 99 "-25.0~+25.0" 100 "-25.0~+25.0" 101 "-25.0~+25.0" 102 "-25.0~+25.0" 103 "-25.0~+25.0" 104 "-25.0~+25.0" 105 "-25.0~+25.0" 106 "-25.0~+25.0" 107 "-25.0~+25.0" 108 "-25.0~+25.0" 109 "-25.0~+25.0" 110 "-25.0~+25.0" 111 "-25.0~+25.0" 112 "-25.0~+25.0" 113 "-25.0~+25.0" 114 "-25.0~+25.0" 115 "-25.0~+25.0" 116 "-25.0~+25.0" 117 "-25.0~+25.0" 118 "-25.0~+25.0" 119 "-25.0~+25.0" 120 "-25.0~+25.0" 121 "-25.0~+25.0" 122 "-25.0~+25.0" 123 "-25.0~+25.0" 124 "-25.0~+25.0" 125 "-25.0~+25.0" 126 "-25.0~+25.0" 127 "-25.0~+25.0" 128 "-25.0~+25.0" 129 "-25.0~+25.0" 130 "-25.0~+25.0" 131 "-25.0~+25.0" 132 "-25.0~+25.0" 133 "-25.0~+25.0" 134 "-25.0~+25.0" 135 "-25.0~+25.0" 136 "-25.0~+25.0" 137 "-25.0~+25.0" 138 "-25.0~+25.0" 139 "-25.0~+25.0" 140 "-25.0~+25.0" 141 "-25.0~+25.0" 142 "-25.0~+25.0" 143 "-25.0~+25.0" 144 "-25.0~+25.0" 145 "-25.0~+25.0" 146 "-25.0~+25.0" 147 "-25.0~+25.0" 148 "-25.0~+25.0" 149 "-25.0~+25.0" 150 "-25.0~+25.0" 151 "-25.0~+25.0" 152 "-25.0~+25.0" 153 "-25.0~+25.0" 154 "-25.0~+25.0" 155 "-25.0~+25.0" 156 "-25.0~+25.0" 157 "-25.0~+25.0" 158 "-25.0~+25.0" 159 "-25.0~+25.0" 160 "-25.0~+25.0" 161 "-25.0~+25.0" 162 "-25.0~+25.0" 163 "-25.0~+25.0" 164 "-25.0~+25.0" 165 "-25.0~+25.0" 166 "-25.0~+25.0" 167 "-25.0~+25.0" 168 "-25.0~+25.0" 169 "-25.0~+25.0" 170 "-25.0~+25.0" 171 "-25.0~+25.0" 172 "-25.0~+25.0" 173 "-25.0~+25.0" 174 "-25.0~+25.0" 175 "-25.0~+25.0" 176 "-25.0~+25.0" 177 "-25.0~+25.0" 178 "-25.0~+25.0" 179 "-25.0~+25.0" 180 "-25.0~+25.0" 181 "-25.0~+25.0" 182 "-25.0~+25.0" 183 "-25.0~+25.0" 184 "-25.0~+25.0" 185 "-25.0~+25.0" 186 "-25.0~+25.0" 187 "-25.0~+25.0" 188 "-25.0~+25.0" 189 "-25.0~+25.0" 190 "-25.0~+25.0" 191 "-25.0~+25.0" 192 "-25.0~+25.0" 193 "-25.0~+25.0" 194 "-25.0~+25.0" 195 "-25.0~+25.0" 196 "-25.0~+25.0" 197 "-25.0~+25.0" 198 "-25.0~+25.0" 199 "-25.0~+25.0" 200 "-25.0~+25.0" 201 "-25.0~+25.0" 202 "-25.0~+25.0" 203 "-25.0~+25.0" 204 "-25.0~+25.0" 205 "-25.0~+25.0" 206 "-25.0~+25.0" 207 "-25.0~+25.0" 208 "-25.0~+25.0" 209 "-25.0~+25.0" 210 "-25.0~+25.0" 211 "-25.0~+25.0" 212 "-25.0~+25.0" 213 "-25.0~+25.0" 214 "-25.0~+25.0" 215 "-25.0~+25.0" 216 "-25.0~+25.0" 217 "-25.0~+25.0" 218 "-25.0~+25.0" 219 "-25.0~+25.0" 220 "-25.0~+25.0" 221 "-25.0~+25.0" 222 "-25.0~+25.0" 223 "-25.0~+25.0" 224 "-25.0~+25.0" 225 "-25.0~+25.0" 226 "-25.0~+25.0" 227 "-25.0~+25.0" 228 "-25.0~+25.0" 229 "-25.0~+25.0" 230 "-25.0~+25.0" 231 "-25.0~+25.0" 232 "-25.0~+25.0" 233 "-25.0~+25.0" 234 "-25.0~+25.0" 235 "-25.0~+25.0" 236 "-25.0~+25.0" 237 "-25.0~+25.0" 238 "-25.0~+25.0" 239 "-25.0~+25.0" 240 "-25.0~+25.0" 241 "-25.0~+25.0" 242 "-25.0~+25.0" 243 "-25.0~+25.0" 244 "-25.0~+25.0" 245 "-25.0~+25.0" 246 "-25.0~+25.0" 247 "-25.0~+25.0" 248 "-25.0~+25.0" 249 "-25.0~+25.0" 250 "-25.0~+25.0" 251 "-25.0~+25.0" 252 "-25.0~+25.0" 253 "-25.0~+25.0" 254 "-25.0~+25.0" 255 "-25.0~+25.0" 256 "-25.0~+25.0" 257 "-25.0~+25.0" 258 "-25.0~+25.0" 259 "-25.0~+25.0" 260 "-25.0~+25.0" 261 "-25.0~+25.0" 262 "-25.0~+25.0" 263 "-25.0~+25.0" 264 "-25.0~+25.0" 265 "-25.0~+25.0" 266 "-25.0~+25.0" 267 "-25.0~+25.0" 268 "-25.0~+25.0" 269 "-25.0~+25.0" 270 "-25.0~+25.0" 271 "-25.0~+25.0" 272 "-25.0~+25.0" 273 "-25.0~+25.0" 274 "-25.0~+25.0" 275 "-25.0~+25.0" 276 "-25.0~+25.0" 277 "-25.0~+25.0" 278 "-25.0~+25.0" 279 "-25.0~+25.0" 280 "-25.0~+25.0" 281 "-25.0~+25.0" 282 "-25.0~+25.0" 283 "-25.0~+25.0" 284 "-25.0~+25.0" 285 "-25.0~+25.0" 286 "-25.0~+25.0" 287 "-25.0~+25.0" 288 "-25.0~+25.0" 289 "-25.0~+25.0" 290 "-25.0~+25.0" 291 "-25.0~+25.0" 292 "-25.0~+25.0" 293 "-25.0~+25.0" 294 "-25.0~+25.0" 295 "-25.0~+25.0" 296 "-25.0~+25.0" 297 "-25.0~+25.0" 298 "-25.0~+25.0" 299 "-25.0~+25.0" 300 "-25.0~+25.0" 301 "-25.0~+25.0" 302 "-25.0~+25.0" 303 "-25.0~+25.0" 304 "-25.0~+25.0" 305 "-25.0~+25.0" 306 "-25.0~+25.0" 307 "-25.0~+25.0" 308 "-25.0~+25.0" 309 "-25.0~+25.0" 310 "-25.0~+25.0" 311 "-25.0~+25.0" 312 "-25.0~+25.0" 313 "-25.0~+25.0" 314 "-25.0~+25.0" 315 "-25.0~+25.0" 316 "-25.0~+25.0" 317 "-25.0~+25.0" 318 "-25.0~+25.0" 319 "-25.0~+25.0" 320 "-25.0~+25.0" 321 "-25.0~+25.0" 322 "-25.0~+25.0" 323 "-25.0~+25.0" 324 "-25.0~+25.0" 325 "-25.0~+25.0" 326 "-25.0~+25.0" 327 "-25.0~+25.0" 328 "-25.0~+25.0" 329 "-25.0~+25.0" 330 "-25.0~+25.0" 331 "-25.0~+25.0" 332 "-25.0~+25.0" 333 "-25.0~+25.0" 334 "-25.0~+25.0" 335 "-25.0~+25.0" 336 "-25.0~+25.0" 337 "-25.0~+25.0" 338 "-25.0~+25.0" 339 "-25.0~+25.0" 340 "-25.0~+25.0" 341 "-25.0~+25.0" 342 "-25.0~+25.0" 343 "-25.0~+25.0" 344 "-25.0~+25.0" 345 "-25.0~+25.0" 346 "-25.0~+25.0" 347 "-25.0~+25.0" 348 "-25.0~+25.0" 349 "-25.0~+25.0" 350 "-25.0~+25.0" 351 "-25.0~+25.0" 352 "-25.0~+25.0" 353 "-25.0~+25.0" 354 "-25.0~+25.0" 355 "-25.0~+25.0" 356 "-25.0~+25.0" 357 "-25.0~+25.0" 358 "-25.0~+25.0" 359 "-25.0~+25.0" 360 "-25.0~+25.0" 361 "-25.0~+25.0" 362 "-25.0~+25.0" 363 "-25.0~+25.0" 364 "-25.0~+25.0" 365 "-25.0~+25.0" 366 "-25.0~+25.0" 367 "-25.0~+25.0" 368 "-25.0~+25.0" 369 "-25.0~+25.0" 370 "-25.0~+25.0" 371 "-25.0~+25.0" 372 "-25.0~+25.0" 373 "-25.0~+25.0" 374 "-25.0~+25.0" 375 "-25.0~+25.0" 376 "-25.0~+25.0" 377 "-25.0~+25.0" 378 "-25.0~+25.0" 379 "-25.0~+25.0" 380 "-25.0~+25.0" 381 "-25.0~+25.0" 382 "-25.0~+25.0" 383 "-25.0~+25.0" 384 "-25.0~+25.0" 385 "-25.0~+25.0" 386 "-25.0~+25.0" 387 "-25.0~+25.0" 388 "-25.0~+25.0" 389 "-25.0~+25.0" 390 "-25.0~+25.0" 391 "-25.0~+25.0" 392 "-25.0~+25.0" 393 "-25.0~+25.0" 394 "-25.0~+25.0" 395 "-25.0~+25.0" 396 "-25.0~+25.0" 397 "-25.0~+25.0" 398 "-25.0~+25.0" 399 "-25.0~+25.0" 400 "-25.0~+25.0" 401 "-25.0~+25.0" 402 "-25.0~+25.0" 403 "-25.0~+25.0" 404 "-25.0~+25.0" 405 "-25.0~+25.0" 406 "-25.0~+25.0" 407 "-25.0~+25.0" 408 "-25.0~+25.0" 409 "-25.0~+25.0" 410 "-25.0~+25.0" 411 "-25.0~+25.0" 412 "-25.0~+25.0" 413 "-25.0~+25.0" 414 "-25.0~+25.0" 415 "-25.0~+25.0" 416 "-25.0~+25.0" 417 "-25.0~+25.0" 418 "-25.0~+25.0" 419 "-25.0~+25.0" 420 "-25.0~+25.0" 421 "-25.0~+25.0" 422 "-25.0~+25.0" 423 "-25.0~+25.0" 424 "-25.0~+25.0" 425 "-25.0~+25.0" 426 "-25.0~+25.0" 427 "-25.0~+25.0" 428 "-25.0~+25.0" 429 "-25.0~+25.0" 430 "-25.0~+25.0" 431 "-25.0~+25.0" 432 "-25.0~+25.0" 433 "-25.0~+25.0" 434 "-25.0~+25.0" 435 "-25.0~+25.0" 436 "-25.0~+25.0" 437 "-25.0~+25.0" 438 "-25.0~+25.0" 439 "-25.0~+25.0" 440 "-25.0~+25.0" 441 "-25.0~+25.0" 442 "-25.0~+25.0" 443 "-25.0~+25.0" 444 "-25.0~+25.0" 445 "-25.0~+25.0" 446 "-25.0~+25.0" 447 "-25.0~+25.0" 448 "-25.0~+25.0" 449 "-25.0~+25.0" 450 "-25.0~+25.0" 451 "-25.0~+25.0" 452 "-25.0~+25.0" 453 "-25.0~+25.0" 454 "-25.0~+25.0" 455 "-25.0~+25.0" 456 "-25.0~+25.0" 457 "-25.0~+25.0" 458 "-25.0~+25.0" 459 "-25.0~+25.0" 460 "-25.0~+25.0" 461 "-25.0~+25.0" 462 "-25.0~+25.0" 463 "-25.0~+25.0" 464 "-25.0~+25.0" 465 "-25.0~+25.0" 466 "-25.0~+25.0" 467 "-25.0~+25.0" 468 "-25.0~+25.0" 469 "-25.0~+25.0" 470 "-25.0~+25.0" 471 "-25.0~+25.0" 472 "-25.0~+25.0" 473 "-25.0~+25.0" 474 "-25.0~+25.0" 475 "-25.0~+25.0" 476 "-25.0~+25.0" 477 "-25.0~+25.0" 478 "-25.0~+25.0" 479 "-25.0~+25.0" 480 "-25.0~+25.0" 481 "-25.0~+25.0" 482 "-25.0~+25.0" 483 "-25.0~+25.0" 484 "-25.0~+25.0" 485 "-25.0~+25.0" 486 "-25.0~+25.0" 487 "-25.0~+25.0" 488 "-25.0~+25.0" 489 "-25.0~+25.0" 490 "-25.0~+25.0" 491 "-25.0~+25.0" 492 "-25.0~+25.0" 493 "-25.0~+25.0" 494 "-25.0~+25.0" 495 "-25.0~+25.0" 496 "-25.0~+25.0" 497 "-25.0~+25.0" 498 "-25.0~+25.0" 499 "-25.0~+25.0" 500 "-25.0~+25.0" 501 "Not used" 502 "Not used" 503 "Not used" 504 "Not used" 505 "Not used" 506 "Not used" 507 "Not used" 508 "Not used" 509 "Not used" 510 "Default" 511 "Error indicator";
VAL_ 698 IFSref_VehLftAngl7Val 0 "-25.0~+25.0" 1 "-25.0~+25.0" 2 "-25.0~+25.0" 3 "-25.0~+25.0" 4 "-25.0~+25.0" 5 "-25.0~+25.0" 6 "-25.0~+25.0" 7 "-25.0~+25.0" 8 "-25.0~+25.0" 9 "-25.0~+25.0" 10 "-25.0~+25.0" 11 "-25.0~+25.0" 12 "-25.0~+25.0" 13 "-25.0~+25.0" 14 "-25.0~+25.0" 15 "-25.0~+25.0" 16 "-25.0~+25.0" 17 "-25.0~+25.0" 18 "-25.0~+25.0" 19 "-25.0~+25.0" 20 "-25.0~+25.0" 21 "-25.0~+25.0" 22 "-25.0~+25.0" 23 "-25.0~+25.0" 24 "-25.0~+25.0" 25 "-25.0~+25.0" 26 "-25.0~+25.0" 27 "-25.0~+25.0" 28 "-25.0~+25.0" 29 "-25.0~+25.0" 30 "-25.0~+25.0" 31 "-25.0~+25.0" 32 "-25.0~+25.0" 33 "-25.0~+25.0" 34 "-25.0~+25.0" 35 "-25.0~+25.0" 36 "-25.0~+25.0" 37 "-25.0~+25.0" 38 "-25.0~+25.0" 39 "-25.0~+25.0" 40 "-25.0~+25.0" 41 "-25.0~+25.0" 42 "-25.0~+25.0" 43 "-25.0~+25.0" 44 "-25.0~+25.0" 45 "-25.0~+25.0" 46 "-25.0~+25.0" 47 "-25.0~+25.0" 48 "-25.0~+25.0" 49 "-25.0~+25.0" 50 "-25.0~+25.0" 51 "-25.0~+25.0" 52 "-25.0~+25.0" 53 "-25.0~+25.0" 54 "-25.0~+25.0" 55 "-25.0~+25.0" 56 "-25.0~+25.0" 57 "-25.0~+25.0" 58 "-25.0~+25.0" 59 "-25.0~+25.0" 60 "-25.0~+25.0" 61 "-25.0~+25.0" 62 "-25.0~+25.0" 63 "-25.0~+25.0" 64 "-25.0~+25.0" 65 "-25.0~+25.0" 66 "-25.0~+25.0" 67 "-25.0~+25.0" 68 "-25.0~+25.0" 69 "-25.0~+25.0" 70 "-25.0~+25.0" 71 "-25.0~+25.0" 72 "-25.0~+25.0" 73 "-25.0~+25.0" 74 "-25.0~+25.0" 75 "-25.0~+25.0" 76 "-25.0~+25.0" 77 "-25.0~+25.0" 78 "-25.0~+25.0" 79 "-25.0~+25.0" 80 "-25.0~+25.0" 81 "-25.0~+25.0" 82 "-25.0~+25.0" 83 "-25.0~+25.0" 84 "-25.0~+25.0" 85 "-25.0~+25.0" 86 "-25.0~+25.0" 87 "-25.0~+25.0" 88 "-25.0~+25.0" 89 "-25.0~+25.0" 90 "-25.0~+25.0" 91 "-25.0~+25.0" 92 "-25.0~+25.0" 93 "-25.0~+25.0" 94 "-25.0~+25.0" 95 "-25.0~+25.0" 96 "-25.0~+25.0" 97 "-25.0~+25.0" 98 "-25.0~+25.0" 99 "-25.0~+25.0" 100 "-25.0~+25.0" 101 "-25.0~+25.0" 102 "-25.0~+25.0" 103 "-25.0~+25.0" 104 "-25.0~+25.0" 105 "-25.0~+25.0" 106 "-25.0~+25.0" 107 "-25.0~+25.0" 108 "-25.0~+25.0" 109 "-25.0~+25.0" 110 "-25.0~+25.0" 111 "-25.0~+25.0" 112 "-25.0~+25.0" 113 "-25.0~+25.0" 114 "-25.0~+25.0" 115 "-25.0~+25.0" 116 "-25.0~+25.0" 117 "-25.0~+25.0" 118 "-25.0~+25.0" 119 "-25.0~+25.0" 120 "-25.0~+25.0" 121 "-25.0~+25.0" 122 "-25.0~+25.0" 123 "-25.0~+25.0" 124 "-25.0~+25.0" 125 "-25.0~+25.0" 126 "-25.0~+25.0" 127 "-25.0~+25.0" 128 "-25.0~+25.0" 129 "-25.0~+25.0" 130 "-25.0~+25.0" 131 "-25.0~+25.0" 132 "-25.0~+25.0" 133 "-25.0~+25.0" 134 "-25.0~+25.0" 135 "-25.0~+25.0" 136 "-25.0~+25.0" 137 "-25.0~+25.0" 138 "-25.0~+25.0" 139 "-25.0~+25.0" 140 "-25.0~+25.0" 141 "-25.0~+25.0" 142 "-25.0~+25.0" 143 "-25.0~+25.0" 144 "-25.0~+25.0" 145 "-25.0~+25.0" 146 "-25.0~+25.0" 147 "-25.0~+25.0" 148 "-25.0~+25.0" 149 "-25.0~+25.0" 150 "-25.0~+25.0" 151 "-25.0~+25.0" 152 "-25.0~+25.0" 153 "-25.0~+25.0" 154 "-25.0~+25.0" 155 "-25.0~+25.0" 156 "-25.0~+25.0" 157 "-25.0~+25.0" 158 "-25.0~+25.0" 159 "-25.0~+25.0" 160 "-25.0~+25.0" 161 "-25.0~+25.0" 162 "-25.0~+25.0" 163 "-25.0~+25.0" 164 "-25.0~+25.0" 165 "-25.0~+25.0" 166 "-25.0~+25.0" 167 "-25.0~+25.0" 168 "-25.0~+25.0" 169 "-25.0~+25.0" 170 "-25.0~+25.0" 171 "-25.0~+25.0" 172 "-25.0~+25.0" 173 "-25.0~+25.0" 174 "-25.0~+25.0" 175 "-25.0~+25.0" 176 "-25.0~+25.0" 177 "-25.0~+25.0" 178 "-25.0~+25.0" 179 "-25.0~+25.0" 180 "-25.0~+25.0" 181 "-25.0~+25.0" 182 "-25.0~+25.0" 183 "-25.0~+25.0" 184 "-25.0~+25.0" 185 "-25.0~+25.0" 186 "-25.0~+25.0" 187 "-25.0~+25.0" 188 "-25.0~+25.0" 189 "-25.0~+25.0" 190 "-25.0~+25.0" 191 "-25.0~+25.0" 192 "-25.0~+25.0" 193 "-25.0~+25.0" 194 "-25.0~+25.0" 195 "-25.0~+25.0" 196 "-25.0~+25.0" 197 "-25.0~+25.0" 198 "-25.0~+25.0" 199 "-25.0~+25.0" 200 "-25.0~+25.0" 201 "-25.0~+25.0" 202 "-25.0~+25.0" 203 "-25.0~+25.0" 204 "-25.0~+25.0" 205 "-25.0~+25.0" 206 "-25.0~+25.0" 207 "-25.0~+25.0" 208 "-25.0~+25.0" 209 "-25.0~+25.0" 210 "-25.0~+25.0" 211 "-25.0~+25.0" 212 "-25.0~+25.0" 213 "-25.0~+25.0" 214 "-25.0~+25.0" 215 "-25.0~+25.0" 216 "-25.0~+25.0" 217 "-25.0~+25.0" 218 "-25.0~+25.0" 219 "-25.0~+25.0" 220 "-25.0~+25.0" 221 "-25.0~+25.0" 222 "-25.0~+25.0" 223 "-25.0~+25.0" 224 "-25.0~+25.0" 225 "-25.0~+25.0" 226 "-25.0~+25.0" 227 "-25.0~+25.0" 228 "-25.0~+25.0" 229 "-25.0~+25.0" 230 "-25.0~+25.0" 231 "-25.0~+25.0" 232 "-25.0~+25.0" 233 "-25.0~+25.0" 234 "-25.0~+25.0" 235 "-25.0~+25.0" 236 "-25.0~+25.0" 237 "-25.0~+25.0" 238 "-25.0~+25.0" 239 "-25.0~+25.0" 240 "-25.0~+25.0" 241 "-25.0~+25.0" 242 "-25.0~+25.0" 243 "-25.0~+25.0" 244 "-25.0~+25.0" 245 "-25.0~+25.0" 246 "-25.0~+25.0" 247 "-25.0~+25.0" 248 "-25.0~+25.0" 249 "-25.0~+25.0" 250 "-25.0~+25.0" 251 "-25.0~+25.0" 252 "-25.0~+25.0" 253 "-25.0~+25.0" 254 "-25.0~+25.0" 255 "-25.0~+25.0" 256 "-25.0~+25.0" 257 "-25.0~+25.0" 258 "-25.0~+25.0" 259 "-25.0~+25.0" 260 "-25.0~+25.0" 261 "-25.0~+25.0" 262 "-25.0~+25.0" 263 "-25.0~+25.0" 264 "-25.0~+25.0" 265 "-25.0~+25.0" 266 "-25.0~+25.0" 267 "-25.0~+25.0" 268 "-25.0~+25.0" 269 "-25.0~+25.0" 270 "-25.0~+25.0" 271 "-25.0~+25.0" 272 "-25.0~+25.0" 273 "-25.0~+25.0" 274 "-25.0~+25.0" 275 "-25.0~+25.0" 276 "-25.0~+25.0" 277 "-25.0~+25.0" 278 "-25.0~+25.0" 279 "-25.0~+25.0" 280 "-25.0~+25.0" 281 "-25.0~+25.0" 282 "-25.0~+25.0" 283 "-25.0~+25.0" 284 "-25.0~+25.0" 285 "-25.0~+25.0" 286 "-25.0~+25.0" 287 "-25.0~+25.0" 288 "-25.0~+25.0" 289 "-25.0~+25.0" 290 "-25.0~+25.0" 291 "-25.0~+25.0" 292 "-25.0~+25.0" 293 "-25.0~+25.0" 294 "-25.0~+25.0" 295 "-25.0~+25.0" 296 "-25.0~+25.0" 297 "-25.0~+25.0" 298 "-25.0~+25.0" 299 "-25.0~+25.0" 300 "-25.0~+25.0" 301 "-25.0~+25.0" 302 "-25.0~+25.0" 303 "-25.0~+25.0" 304 "-25.0~+25.0" 305 "-25.0~+25.0" 306 "-25.0~+25.0" 307 "-25.0~+25.0" 308 "-25.0~+25.0" 309 "-25.0~+25.0" 310 "-25.0~+25.0" 311 "-25.0~+25.0" 312 "-25.0~+25.0" 313 "-25.0~+25.0" 314 "-25.0~+25.0" 315 "-25.0~+25.0" 316 "-25.0~+25.0" 317 "-25.0~+25.0" 318 "-25.0~+25.0" 319 "-25.0~+25.0" 320 "-25.0~+25.0" 321 "-25.0~+25.0" 322 "-25.0~+25.0" 323 "-25.0~+25.0" 324 "-25.0~+25.0" 325 "-25.0~+25.0" 326 "-25.0~+25.0" 327 "-25.0~+25.0" 328 "-25.0~+25.0" 329 "-25.0~+25.0" 330 "-25.0~+25.0" 331 "-25.0~+25.0" 332 "-25.0~+25.0" 333 "-25.0~+25.0" 334 "-25.0~+25.0" 335 "-25.0~+25.0" 336 "-25.0~+25.0" 337 "-25.0~+25.0" 338 "-25.0~+25.0" 339 "-25.0~+25.0" 340 "-25.0~+25.0" 341 "-25.0~+25.0" 342 "-25.0~+25.0" 343 "-25.0~+25.0" 344 "-25.0~+25.0" 345 "-25.0~+25.0" 346 "-25.0~+25.0" 347 "-25.0~+25.0" 348 "-25.0~+25.0" 349 "-25.0~+25.0" 350 "-25.0~+25.0" 351 "-25.0~+25.0" 352 "-25.0~+25.0" 353 "-25.0~+25.0" 354 "-25.0~+25.0" 355 "-25.0~+25.0" 356 "-25.0~+25.0" 357 "-25.0~+25.0" 358 "-25.0~+25.0" 359 "-25.0~+25.0" 360 "-25.0~+25.0" 361 "-25.0~+25.0" 362 "-25.0~+25.0" 363 "-25.0~+25.0" 364 "-25.0~+25.0" 365 "-25.0~+25.0" 366 "-25.0~+25.0" 367 "-25.0~+25.0" 368 "-25.0~+25.0" 369 "-25.0~+25.0" 370 "-25.0~+25.0" 371 "-25.0~+25.0" 372 "-25.0~+25.0" 373 "-25.0~+25.0" 374 "-25.0~+25.0" 375 "-25.0~+25.0" 376 "-25.0~+25.0" 377 "-25.0~+25.0" 378 "-25.0~+25.0" 379 "-25.0~+25.0" 380 "-25.0~+25.0" 381 "-25.0~+25.0" 382 "-25.0~+25.0" 383 "-25.0~+25.0" 384 "-25.0~+25.0" 385 "-25.0~+25.0" 386 "-25.0~+25.0" 387 "-25.0~+25.0" 388 "-25.0~+25.0" 389 "-25.0~+25.0" 390 "-25.0~+25.0" 391 "-25.0~+25.0" 392 "-25.0~+25.0" 393 "-25.0~+25.0" 394 "-25.0~+25.0" 395 "-25.0~+25.0" 396 "-25.0~+25.0" 397 "-25.0~+25.0" 398 "-25.0~+25.0" 399 "-25.0~+25.0" 400 "-25.0~+25.0" 401 "-25.0~+25.0" 402 "-25.0~+25.0" 403 "-25.0~+25.0" 404 "-25.0~+25.0" 405 "-25.0~+25.0" 406 "-25.0~+25.0" 407 "-25.0~+25.0" 408 "-25.0~+25.0" 409 "-25.0~+25.0" 410 "-25.0~+25.0" 411 "-25.0~+25.0" 412 "-25.0~+25.0" 413 "-25.0~+25.0" 414 "-25.0~+25.0" 415 "-25.0~+25.0" 416 "-25.0~+25.0" 417 "-25.0~+25.0" 418 "-25.0~+25.0" 419 "-25.0~+25.0" 420 "-25.0~+25.0" 421 "-25.0~+25.0" 422 "-25.0~+25.0" 423 "-25.0~+25.0" 424 "-25.0~+25.0" 425 "-25.0~+25.0" 426 "-25.0~+25.0" 427 "-25.0~+25.0" 428 "-25.0~+25.0" 429 "-25.0~+25.0" 430 "-25.0~+25.0" 431 "-25.0~+25.0" 432 "-25.0~+25.0" 433 "-25.0~+25.0" 434 "-25.0~+25.0" 435 "-25.0~+25.0" 436 "-25.0~+25.0" 437 "-25.0~+25.0" 438 "-25.0~+25.0" 439 "-25.0~+25.0" 440 "-25.0~+25.0" 441 "-25.0~+25.0" 442 "-25.0~+25.0" 443 "-25.0~+25.0" 444 "-25.0~+25.0" 445 "-25.0~+25.0" 446 "-25.0~+25.0" 447 "-25.0~+25.0" 448 "-25.0~+25.0" 449 "-25.0~+25.0" 450 "-25.0~+25.0" 451 "-25.0~+25.0" 452 "-25.0~+25.0" 453 "-25.0~+25.0" 454 "-25.0~+25.0" 455 "-25.0~+25.0" 456 "-25.0~+25.0" 457 "-25.0~+25.0" 458 "-25.0~+25.0" 459 "-25.0~+25.0" 460 "-25.0~+25.0" 461 "-25.0~+25.0" 462 "-25.0~+25.0" 463 "-25.0~+25.0" 464 "-25.0~+25.0" 465 "-25.0~+25.0" 466 "-25.0~+25.0" 467 "-25.0~+25.0" 468 "-25.0~+25.0" 469 "-25.0~+25.0" 470 "-25.0~+25.0" 471 "-25.0~+25.0" 472 "-25.0~+25.0" 473 "-25.0~+25.0" 474 "-25.0~+25.0" 475 "-25.0~+25.0" 476 "-25.0~+25.0" 477 "-25.0~+25.0" 478 "-25.0~+25.0" 479 "-25.0~+25.0" 480 "-25.0~+25.0" 481 "-25.0~+25.0" 482 "-25.0~+25.0" 483 "-25.0~+25.0" 484 "-25.0~+25.0" 485 "-25.0~+25.0" 486 "-25.0~+25.0" 487 "-25.0~+25.0" 488 "-25.0~+25.0" 489 "-25.0~+25.0" 490 "-25.0~+25.0" 491 "-25.0~+25.0" 492 "-25.0~+25.0" 493 "-25.0~+25.0" 494 "-25.0~+25.0" 495 "-25.0~+25.0" 496 "-25.0~+25.0" 497 "-25.0~+25.0" 498 "-25.0~+25.0" 499 "-25.0~+25.0" 500 "-25.0~+25.0" 501 "Not used" 502 "Not used" 503 "Not used" 504 "Not used" 505 "Not used" 506 "Not used" 507 "Not used" 508 "Not used" 509 "Not used" 510 "Default" 511 "Error indicator";
VAL_ 698 IFSref_VehRtAngl7Val 0 "-25.0~+25.0" 1 "-25.0~+25.0" 2 "-25.0~+25.0" 3 "-25.0~+25.0" 4 "-25.0~+25.0" 5 "-25.0~+25.0" 6 "-25.0~+25.0" 7 "-25.0~+25.0" 8 "-25.0~+25.0" 9 "-25.0~+25.0" 10 "-25.0~+25.0" 11 "-25.0~+25.0" 12 "-25.0~+25.0" 13 "-25.0~+25.0" 14 "-25.0~+25.0" 15 "-25.0~+25.0" 16 "-25.0~+25.0" 17 "-25.0~+25.0" 18 "-25.0~+25.0" 19 "-25.0~+25.0" 20 "-25.0~+25.0" 21 "-25.0~+25.0" 22 "-25.0~+25.0" 23 "-25.0~+25.0" 24 "-25.0~+25.0" 25 "-25.0~+25.0" 26 "-25.0~+25.0" 27 "-25.0~+25.0" 28 "-25.0~+25.0" 29 "-25.0~+25.0" 30 "-25.0~+25.0" 31 "-25.0~+25.0" 32 "-25.0~+25.0" 33 "-25.0~+25.0" 34 "-25.0~+25.0" 35 "-25.0~+25.0" 36 "-25.0~+25.0" 37 "-25.0~+25.0" 38 "-25.0~+25.0" 39 "-25.0~+25.0" 40 "-25.0~+25.0" 41 "-25.0~+25.0" 42 "-25.0~+25.0" 43 "-25.0~+25.0" 44 "-25.0~+25.0" 45 "-25.0~+25.0" 46 "-25.0~+25.0" 47 "-25.0~+25.0" 48 "-25.0~+25.0" 49 "-25.0~+25.0" 50 "-25.0~+25.0" 51 "-25.0~+25.0" 52 "-25.0~+25.0" 53 "-25.0~+25.0" 54 "-25.0~+25.0" 55 "-25.0~+25.0" 56 "-25.0~+25.0" 57 "-25.0~+25.0" 58 "-25.0~+25.0" 59 "-25.0~+25.0" 60 "-25.0~+25.0" 61 "-25.0~+25.0" 62 "-25.0~+25.0" 63 "-25.0~+25.0" 64 "-25.0~+25.0" 65 "-25.0~+25.0" 66 "-25.0~+25.0" 67 "-25.0~+25.0" 68 "-25.0~+25.0" 69 "-25.0~+25.0" 70 "-25.0~+25.0" 71 "-25.0~+25.0" 72 "-25.0~+25.0" 73 "-25.0~+25.0" 74 "-25.0~+25.0" 75 "-25.0~+25.0" 76 "-25.0~+25.0" 77 "-25.0~+25.0" 78 "-25.0~+25.0" 79 "-25.0~+25.0" 80 "-25.0~+25.0" 81 "-25.0~+25.0" 82 "-25.0~+25.0" 83 "-25.0~+25.0" 84 "-25.0~+25.0" 85 "-25.0~+25.0" 86 "-25.0~+25.0" 87 "-25.0~+25.0" 88 "-25.0~+25.0" 89 "-25.0~+25.0" 90 "-25.0~+25.0" 91 "-25.0~+25.0" 92 "-25.0~+25.0" 93 "-25.0~+25.0" 94 "-25.0~+25.0" 95 "-25.0~+25.0" 96 "-25.0~+25.0" 97 "-25.0~+25.0" 98 "-25.0~+25.0" 99 "-25.0~+25.0" 100 "-25.0~+25.0" 101 "-25.0~+25.0" 102 "-25.0~+25.0" 103 "-25.0~+25.0" 104 "-25.0~+25.0" 105 "-25.0~+25.0" 106 "-25.0~+25.0" 107 "-25.0~+25.0" 108 "-25.0~+25.0" 109 "-25.0~+25.0" 110 "-25.0~+25.0" 111 "-25.0~+25.0" 112 "-25.0~+25.0" 113 "-25.0~+25.0" 114 "-25.0~+25.0" 115 "-25.0~+25.0" 116 "-25.0~+25.0" 117 "-25.0~+25.0" 118 "-25.0~+25.0" 119 "-25.0~+25.0" 120 "-25.0~+25.0" 121 "-25.0~+25.0" 122 "-25.0~+25.0" 123 "-25.0~+25.0" 124 "-25.0~+25.0" 125 "-25.0~+25.0" 126 "-25.0~+25.0" 127 "-25.0~+25.0" 128 "-25.0~+25.0" 129 "-25.0~+25.0" 130 "-25.0~+25.0" 131 "-25.0~+25.0" 132 "-25.0~+25.0" 133 "-25.0~+25.0" 134 "-25.0~+25.0" 135 "-25.0~+25.0" 136 "-25.0~+25.0" 137 "-25.0~+25.0" 138 "-25.0~+25.0" 139 "-25.0~+25.0" 140 "-25.0~+25.0" 141 "-25.0~+25.0" 142 "-25.0~+25.0" 143 "-25.0~+25.0" 144 "-25.0~+25.0" 145 "-25.0~+25.0" 146 "-25.0~+25.0" 147 "-25.0~+25.0" 148 "-25.0~+25.0" 149 "-25.0~+25.0" 150 "-25.0~+25.0" 151 "-25.0~+25.0" 152 "-25.0~+25.0" 153 "-25.0~+25.0" 154 "-25.0~+25.0" 155 "-25.0~+25.0" 156 "-25.0~+25.0" 157 "-25.0~+25.0" 158 "-25.0~+25.0" 159 "-25.0~+25.0" 160 "-25.0~+25.0" 161 "-25.0~+25.0" 162 "-25.0~+25.0" 163 "-25.0~+25.0" 164 "-25.0~+25.0" 165 "-25.0~+25.0" 166 "-25.0~+25.0" 167 "-25.0~+25.0" 168 "-25.0~+25.0" 169 "-25.0~+25.0" 170 "-25.0~+25.0" 171 "-25.0~+25.0" 172 "-25.0~+25.0" 173 "-25.0~+25.0" 174 "-25.0~+25.0" 175 "-25.0~+25.0" 176 "-25.0~+25.0" 177 "-25.0~+25.0" 178 "-25.0~+25.0" 179 "-25.0~+25.0" 180 "-25.0~+25.0" 181 "-25.0~+25.0" 182 "-25.0~+25.0" 183 "-25.0~+25.0" 184 "-25.0~+25.0" 185 "-25.0~+25.0" 186 "-25.0~+25.0" 187 "-25.0~+25.0" 188 "-25.0~+25.0" 189 "-25.0~+25.0" 190 "-25.0~+25.0" 191 "-25.0~+25.0" 192 "-25.0~+25.0" 193 "-25.0~+25.0" 194 "-25.0~+25.0" 195 "-25.0~+25.0" 196 "-25.0~+25.0" 197 "-25.0~+25.0" 198 "-25.0~+25.0" 199 "-25.0~+25.0" 200 "-25.0~+25.0" 201 "-25.0~+25.0" 202 "-25.0~+25.0" 203 "-25.0~+25.0" 204 "-25.0~+25.0" 205 "-25.0~+25.0" 206 "-25.0~+25.0" 207 "-25.0~+25.0" 208 "-25.0~+25.0" 209 "-25.0~+25.0" 210 "-25.0~+25.0" 211 "-25.0~+25.0" 212 "-25.0~+25.0" 213 "-25.0~+25.0" 214 "-25.0~+25.0" 215 "-25.0~+25.0" 216 "-25.0~+25.0" 217 "-25.0~+25.0" 218 "-25.0~+25.0" 219 "-25.0~+25.0" 220 "-25.0~+25.0" 221 "-25.0~+25.0" 222 "-25.0~+25.0" 223 "-25.0~+25.0" 224 "-25.0~+25.0" 225 "-25.0~+25.0" 226 "-25.0~+25.0" 227 "-25.0~+25.0" 228 "-25.0~+25.0" 229 "-25.0~+25.0" 230 "-25.0~+25.0" 231 "-25.0~+25.0" 232 "-25.0~+25.0" 233 "-25.0~+25.0" 234 "-25.0~+25.0" 235 "-25.0~+25.0" 236 "-25.0~+25.0" 237 "-25.0~+25.0" 238 "-25.0~+25.0" 239 "-25.0~+25.0" 240 "-25.0~+25.0" 241 "-25.0~+25.0" 242 "-25.0~+25.0" 243 "-25.0~+25.0" 244 "-25.0~+25.0" 245 "-25.0~+25.0" 246 "-25.0~+25.0" 247 "-25.0~+25.0" 248 "-25.0~+25.0" 249 "-25.0~+25.0" 250 "-25.0~+25.0" 251 "-25.0~+25.0" 252 "-25.0~+25.0" 253 "-25.0~+25.0" 254 "-25.0~+25.0" 255 "-25.0~+25.0" 256 "-25.0~+25.0" 257 "-25.0~+25.0" 258 "-25.0~+25.0" 259 "-25.0~+25.0" 260 "-25.0~+25.0" 261 "-25.0~+25.0" 262 "-25.0~+25.0" 263 "-25.0~+25.0" 264 "-25.0~+25.0" 265 "-25.0~+25.0" 266 "-25.0~+25.0" 267 "-25.0~+25.0" 268 "-25.0~+25.0" 269 "-25.0~+25.0" 270 "-25.0~+25.0" 271 "-25.0~+25.0" 272 "-25.0~+25.0" 273 "-25.0~+25.0" 274 "-25.0~+25.0" 275 "-25.0~+25.0" 276 "-25.0~+25.0" 277 "-25.0~+25.0" 278 "-25.0~+25.0" 279 "-25.0~+25.0" 280 "-25.0~+25.0" 281 "-25.0~+25.0" 282 "-25.0~+25.0" 283 "-25.0~+25.0" 284 "-25.0~+25.0" 285 "-25.0~+25.0" 286 "-25.0~+25.0" 287 "-25.0~+25.0" 288 "-25.0~+25.0" 289 "-25.0~+25.0" 290 "-25.0~+25.0" 291 "-25.0~+25.0" 292 "-25.0~+25.0" 293 "-25.0~+25.0" 294 "-25.0~+25.0" 295 "-25.0~+25.0" 296 "-25.0~+25.0" 297 "-25.0~+25.0" 298 "-25.0~+25.0" 299 "-25.0~+25.0" 300 "-25.0~+25.0" 301 "-25.0~+25.0" 302 "-25.0~+25.0" 303 "-25.0~+25.0" 304 "-25.0~+25.0" 305 "-25.0~+25.0" 306 "-25.0~+25.0" 307 "-25.0~+25.0" 308 "-25.0~+25.0" 309 "-25.0~+25.0" 310 "-25.0~+25.0" 311 "-25.0~+25.0" 312 "-25.0~+25.0" 313 "-25.0~+25.0" 314 "-25.0~+25.0" 315 "-25.0~+25.0" 316 "-25.0~+25.0" 317 "-25.0~+25.0" 318 "-25.0~+25.0" 319 "-25.0~+25.0" 320 "-25.0~+25.0" 321 "-25.0~+25.0" 322 "-25.0~+25.0" 323 "-25.0~+25.0" 324 "-25.0~+25.0" 325 "-25.0~+25.0" 326 "-25.0~+25.0" 327 "-25.0~+25.0" 328 "-25.0~+25.0" 329 "-25.0~+25.0" 330 "-25.0~+25.0" 331 "-25.0~+25.0" 332 "-25.0~+25.0" 333 "-25.0~+25.0" 334 "-25.0~+25.0" 335 "-25.0~+25.0" 336 "-25.0~+25.0" 337 "-25.0~+25.0" 338 "-25.0~+25.0" 339 "-25.0~+25.0" 340 "-25.0~+25.0" 341 "-25.0~+25.0" 342 "-25.0~+25.0" 343 "-25.0~+25.0" 344 "-25.0~+25.0" 345 "-25.0~+25.0" 346 "-25.0~+25.0" 347 "-25.0~+25.0" 348 "-25.0~+25.0" 349 "-25.0~+25.0" 350 "-25.0~+25.0" 351 "-25.0~+25.0" 352 "-25.0~+25.0" 353 "-25.0~+25.0" 354 "-25.0~+25.0" 355 "-25.0~+25.0" 356 "-25.0~+25.0" 357 "-25.0~+25.0" 358 "-25.0~+25.0" 359 "-25.0~+25.0" 360 "-25.0~+25.0" 361 "-25.0~+25.0" 362 "-25.0~+25.0" 363 "-25.0~+25.0" 364 "-25.0~+25.0" 365 "-25.0~+25.0" 366 "-25.0~+25.0" 367 "-25.0~+25.0" 368 "-25.0~+25.0" 369 "-25.0~+25.0" 370 "-25.0~+25.0" 371 "-25.0~+25.0" 372 "-25.0~+25.0" 373 "-25.0~+25.0" 374 "-25.0~+25.0" 375 "-25.0~+25.0" 376 "-25.0~+25.0" 377 "-25.0~+25.0" 378 "-25.0~+25.0" 379 "-25.0~+25.0" 380 "-25.0~+25.0" 381 "-25.0~+25.0" 382 "-25.0~+25.0" 383 "-25.0~+25.0" 384 "-25.0~+25.0" 385 "-25.0~+25.0" 386 "-25.0~+25.0" 387 "-25.0~+25.0" 388 "-25.0~+25.0" 389 "-25.0~+25.0" 390 "-25.0~+25.0" 391 "-25.0~+25.0" 392 "-25.0~+25.0" 393 "-25.0~+25.0" 394 "-25.0~+25.0" 395 "-25.0~+25.0" 396 "-25.0~+25.0" 397 "-25.0~+25.0" 398 "-25.0~+25.0" 399 "-25.0~+25.0" 400 "-25.0~+25.0" 401 "-25.0~+25.0" 402 "-25.0~+25.0" 403 "-25.0~+25.0" 404 "-25.0~+25.0" 405 "-25.0~+25.0" 406 "-25.0~+25.0" 407 "-25.0~+25.0" 408 "-25.0~+25.0" 409 "-25.0~+25.0" 410 "-25.0~+25.0" 411 "-25.0~+25.0" 412 "-25.0~+25.0" 413 "-25.0~+25.0" 414 "-25.0~+25.0" 415 "-25.0~+25.0" 416 "-25.0~+25.0" 417 "-25.0~+25.0" 418 "-25.0~+25.0" 419 "-25.0~+25.0" 420 "-25.0~+25.0" 421 "-25.0~+25.0" 422 "-25.0~+25.0" 423 "-25.0~+25.0" 424 "-25.0~+25.0" 425 "-25.0~+25.0" 426 "-25.0~+25.0" 427 "-25.0~+25.0" 428 "-25.0~+25.0" 429 "-25.0~+25.0" 430 "-25.0~+25.0" 431 "-25.0~+25.0" 432 "-25.0~+25.0" 433 "-25.0~+25.0" 434 "-25.0~+25.0" 435 "-25.0~+25.0" 436 "-25.0~+25.0" 437 "-25.0~+25.0" 438 "-25.0~+25.0" 439 "-25.0~+25.0" 440 "-25.0~+25.0" 441 "-25.0~+25.0" 442 "-25.0~+25.0" 443 "-25.0~+25.0" 444 "-25.0~+25.0" 445 "-25.0~+25.0" 446 "-25.0~+25.0" 447 "-25.0~+25.0" 448 "-25.0~+25.0" 449 "-25.0~+25.0" 450 "-25.0~+25.0" 451 "-25.0~+25.0" 452 "-25.0~+25.0" 453 "-25.0~+25.0" 454 "-25.0~+25.0" 455 "-25.0~+25.0" 456 "-25.0~+25.0" 457 "-25.0~+25.0" 458 "-25.0~+25.0" 459 "-25.0~+25.0" 460 "-25.0~+25.0" 461 "-25.0~+25.0" 462 "-25.0~+25.0" 463 "-25.0~+25.0" 464 "-25.0~+25.0" 465 "-25.0~+25.0" 466 "-25.0~+25.0" 467 "-25.0~+25.0" 468 "-25.0~+25.0" 469 "-25.0~+25.0" 470 "-25.0~+25.0" 471 "-25.0~+25.0" 472 "-25.0~+25.0" 473 "-25.0~+25.0" 474 "-25.0~+25.0" 475 "-25.0~+25.0" 476 "-25.0~+25.0" 477 "-25.0~+25.0" 478 "-25.0~+25.0" 479 "-25.0~+25.0" 480 "-25.0~+25.0" 481 "-25.0~+25.0" 482 "-25.0~+25.0" 483 "-25.0~+25.0" 484 "-25.0~+25.0" 485 "-25.0~+25.0" 486 "-25.0~+25.0" 487 "-25.0~+25.0" 488 "-25.0~+25.0" 489 "-25.0~+25.0" 490 "-25.0~+25.0" 491 "-25.0~+25.0" 492 "-25.0~+25.0" 493 "-25.0~+25.0" 494 "-25.0~+25.0" 495 "-25.0~+25.0" 496 "-25.0~+25.0" 497 "-25.0~+25.0" 498 "-25.0~+25.0" 499 "-25.0~+25.0" 500 "-25.0~+25.0" 501 "Not used" 502 "Not used" 503 "Not used" 504 "Not used" 505 "Not used" 506 "Not used" 507 "Not used" 508 "Not used" 509 "Not used" 510 "Default" 511 "Error indicator";
VAL_ 698 IFSref_VehLftAngl8Val 0 "-25.0~+25.0" 1 "-25.0~+25.0" 2 "-25.0~+25.0" 3 "-25.0~+25.0" 4 "-25.0~+25.0" 5 "-25.0~+25.0" 6 "-25.0~+25.0" 7 "-25.0~+25.0" 8 "-25.0~+25.0" 9 "-25.0~+25.0" 10 "-25.0~+25.0" 11 "-25.0~+25.0" 12 "-25.0~+25.0" 13 "-25.0~+25.0" 14 "-25.0~+25.0" 15 "-25.0~+25.0" 16 "-25.0~+25.0" 17 "-25.0~+25.0" 18 "-25.0~+25.0" 19 "-25.0~+25.0" 20 "-25.0~+25.0" 21 "-25.0~+25.0" 22 "-25.0~+25.0" 23 "-25.0~+25.0" 24 "-25.0~+25.0" 25 "-25.0~+25.0" 26 "-25.0~+25.0" 27 "-25.0~+25.0" 28 "-25.0~+25.0" 29 "-25.0~+25.0" 30 "-25.0~+25.0" 31 "-25.0~+25.0" 32 "-25.0~+25.0" 33 "-25.0~+25.0" 34 "-25.0~+25.0" 35 "-25.0~+25.0" 36 "-25.0~+25.0" 37 "-25.0~+25.0" 38 "-25.0~+25.0" 39 "-25.0~+25.0" 40 "-25.0~+25.0" 41 "-25.0~+25.0" 42 "-25.0~+25.0" 43 "-25.0~+25.0" 44 "-25.0~+25.0" 45 "-25.0~+25.0" 46 "-25.0~+25.0" 47 "-25.0~+25.0" 48 "-25.0~+25.0" 49 "-25.0~+25.0" 50 "-25.0~+25.0" 51 "-25.0~+25.0" 52 "-25.0~+25.0" 53 "-25.0~+25.0" 54 "-25.0~+25.0" 55 "-25.0~+25.0" 56 "-25.0~+25.0" 57 "-25.0~+25.0" 58 "-25.0~+25.0" 59 "-25.0~+25.0" 60 "-25.0~+25.0" 61 "-25.0~+25.0" 62 "-25.0~+25.0" 63 "-25.0~+25.0" 64 "-25.0~+25.0" 65 "-25.0~+25.0" 66 "-25.0~+25.0" 67 "-25.0~+25.0" 68 "-25.0~+25.0" 69 "-25.0~+25.0" 70 "-25.0~+25.0" 71 "-25.0~+25.0" 72 "-25.0~+25.0" 73 "-25.0~+25.0" 74 "-25.0~+25.0" 75 "-25.0~+25.0" 76 "-25.0~+25.0" 77 "-25.0~+25.0" 78 "-25.0~+25.0" 79 "-25.0~+25.0" 80 "-25.0~+25.0" 81 "-25.0~+25.0" 82 "-25.0~+25.0" 83 "-25.0~+25.0" 84 "-25.0~+25.0" 85 "-25.0~+25.0" 86 "-25.0~+25.0" 87 "-25.0~+25.0" 88 "-25.0~+25.0" 89 "-25.0~+25.0" 90 "-25.0~+25.0" 91 "-25.0~+25.0" 92 "-25.0~+25.0" 93 "-25.0~+25.0" 94 "-25.0~+25.0" 95 "-25.0~+25.0" 96 "-25.0~+25.0" 97 "-25.0~+25.0" 98 "-25.0~+25.0" 99 "-25.0~+25.0" 100 "-25.0~+25.0" 101 "-25.0~+25.0" 102 "-25.0~+25.0" 103 "-25.0~+25.0" 104 "-25.0~+25.0" 105 "-25.0~+25.0" 106 "-25.0~+25.0" 107 "-25.0~+25.0" 108 "-25.0~+25.0" 109 "-25.0~+25.0" 110 "-25.0~+25.0" 111 "-25.0~+25.0" 112 "-25.0~+25.0" 113 "-25.0~+25.0" 114 "-25.0~+25.0" 115 "-25.0~+25.0" 116 "-25.0~+25.0" 117 "-25.0~+25.0" 118 "-25.0~+25.0" 119 "-25.0~+25.0" 120 "-25.0~+25.0" 121 "-25.0~+25.0" 122 "-25.0~+25.0" 123 "-25.0~+25.0" 124 "-25.0~+25.0" 125 "-25.0~+25.0" 126 "-25.0~+25.0" 127 "-25.0~+25.0" 128 "-25.0~+25.0" 129 "-25.0~+25.0" 130 "-25.0~+25.0" 131 "-25.0~+25.0" 132 "-25.0~+25.0" 133 "-25.0~+25.0" 134 "-25.0~+25.0" 135 "-25.0~+25.0" 136 "-25.0~+25.0" 137 "-25.0~+25.0" 138 "-25.0~+25.0" 139 "-25.0~+25.0" 140 "-25.0~+25.0" 141 "-25.0~+25.0" 142 "-25.0~+25.0" 143 "-25.0~+25.0" 144 "-25.0~+25.0" 145 "-25.0~+25.0" 146 "-25.0~+25.0" 147 "-25.0~+25.0" 148 "-25.0~+25.0" 149 "-25.0~+25.0" 150 "-25.0~+25.0" 151 "-25.0~+25.0" 152 "-25.0~+25.0" 153 "-25.0~+25.0" 154 "-25.0~+25.0" 155 "-25.0~+25.0" 156 "-25.0~+25.0" 157 "-25.0~+25.0" 158 "-25.0~+25.0" 159 "-25.0~+25.0" 160 "-25.0~+25.0" 161 "-25.0~+25.0" 162 "-25.0~+25.0" 163 "-25.0~+25.0" 164 "-25.0~+25.0" 165 "-25.0~+25.0" 166 "-25.0~+25.0" 167 "-25.0~+25.0" 168 "-25.0~+25.0" 169 "-25.0~+25.0" 170 "-25.0~+25.0" 171 "-25.0~+25.0" 172 "-25.0~+25.0" 173 "-25.0~+25.0" 174 "-25.0~+25.0" 175 "-25.0~+25.0" 176 "-25.0~+25.0" 177 "-25.0~+25.0" 178 "-25.0~+25.0" 179 "-25.0~+25.0" 180 "-25.0~+25.0" 181 "-25.0~+25.0" 182 "-25.0~+25.0" 183 "-25.0~+25.0" 184 "-25.0~+25.0" 185 "-25.0~+25.0" 186 "-25.0~+25.0" 187 "-25.0~+25.0" 188 "-25.0~+25.0" 189 "-25.0~+25.0" 190 "-25.0~+25.0" 191 "-25.0~+25.0" 192 "-25.0~+25.0" 193 "-25.0~+25.0" 194 "-25.0~+25.0" 195 "-25.0~+25.0" 196 "-25.0~+25.0" 197 "-25.0~+25.0" 198 "-25.0~+25.0" 199 "-25.0~+25.0" 200 "-25.0~+25.0" 201 "-25.0~+25.0" 202 "-25.0~+25.0" 203 "-25.0~+25.0" 204 "-25.0~+25.0" 205 "-25.0~+25.0" 206 "-25.0~+25.0" 207 "-25.0~+25.0" 208 "-25.0~+25.0" 209 "-25.0~+25.0" 210 "-25.0~+25.0" 211 "-25.0~+25.0" 212 "-25.0~+25.0" 213 "-25.0~+25.0" 214 "-25.0~+25.0" 215 "-25.0~+25.0" 216 "-25.0~+25.0" 217 "-25.0~+25.0" 218 "-25.0~+25.0" 219 "-25.0~+25.0" 220 "-25.0~+25.0" 221 "-25.0~+25.0" 222 "-25.0~+25.0" 223 "-25.0~+25.0" 224 "-25.0~+25.0" 225 "-25.0~+25.0" 226 "-25.0~+25.0" 227 "-25.0~+25.0" 228 "-25.0~+25.0" 229 "-25.0~+25.0" 230 "-25.0~+25.0" 231 "-25.0~+25.0" 232 "-25.0~+25.0" 233 "-25.0~+25.0" 234 "-25.0~+25.0" 235 "-25.0~+25.0" 236 "-25.0~+25.0" 237 "-25.0~+25.0" 238 "-25.0~+25.0" 239 "-25.0~+25.0" 240 "-25.0~+25.0" 241 "-25.0~+25.0" 242 "-25.0~+25.0" 243 "-25.0~+25.0" 244 "-25.0~+25.0" 245 "-25.0~+25.0" 246 "-25.0~+25.0" 247 "-25.0~+25.0" 248 "-25.0~+25.0" 249 "-25.0~+25.0" 250 "-25.0~+25.0" 251 "-25.0~+25.0" 252 "-25.0~+25.0" 253 "-25.0~+25.0" 254 "-25.0~+25.0" 255 "-25.0~+25.0" 256 "-25.0~+25.0" 257 "-25.0~+25.0" 258 "-25.0~+25.0" 259 "-25.0~+25.0" 260 "-25.0~+25.0" 261 "-25.0~+25.0" 262 "-25.0~+25.0" 263 "-25.0~+25.0" 264 "-25.0~+25.0" 265 "-25.0~+25.0" 266 "-25.0~+25.0" 267 "-25.0~+25.0" 268 "-25.0~+25.0" 269 "-25.0~+25.0" 270 "-25.0~+25.0" 271 "-25.0~+25.0" 272 "-25.0~+25.0" 273 "-25.0~+25.0" 274 "-25.0~+25.0" 275 "-25.0~+25.0" 276 "-25.0~+25.0" 277 "-25.0~+25.0" 278 "-25.0~+25.0" 279 "-25.0~+25.0" 280 "-25.0~+25.0" 281 "-25.0~+25.0" 282 "-25.0~+25.0" 283 "-25.0~+25.0" 284 "-25.0~+25.0" 285 "-25.0~+25.0" 286 "-25.0~+25.0" 287 "-25.0~+25.0" 288 "-25.0~+25.0" 289 "-25.0~+25.0" 290 "-25.0~+25.0" 291 "-25.0~+25.0" 292 "-25.0~+25.0" 293 "-25.0~+25.0" 294 "-25.0~+25.0" 295 "-25.0~+25.0" 296 "-25.0~+25.0" 297 "-25.0~+25.0" 298 "-25.0~+25.0" 299 "-25.0~+25.0" 300 "-25.0~+25.0" 301 "-25.0~+25.0" 302 "-25.0~+25.0" 303 "-25.0~+25.0" 304 "-25.0~+25.0" 305 "-25.0~+25.0" 306 "-25.0~+25.0" 307 "-25.0~+25.0" 308 "-25.0~+25.0" 309 "-25.0~+25.0" 310 "-25.0~+25.0" 311 "-25.0~+25.0" 312 "-25.0~+25.0" 313 "-25.0~+25.0" 314 "-25.0~+25.0" 315 "-25.0~+25.0" 316 "-25.0~+25.0" 317 "-25.0~+25.0" 318 "-25.0~+25.0" 319 "-25.0~+25.0" 320 "-25.0~+25.0" 321 "-25.0~+25.0" 322 "-25.0~+25.0" 323 "-25.0~+25.0" 324 "-25.0~+25.0" 325 "-25.0~+25.0" 326 "-25.0~+25.0" 327 "-25.0~+25.0" 328 "-25.0~+25.0" 329 "-25.0~+25.0" 330 "-25.0~+25.0" 331 "-25.0~+25.0" 332 "-25.0~+25.0" 333 "-25.0~+25.0" 334 "-25.0~+25.0" 335 "-25.0~+25.0" 336 "-25.0~+25.0" 337 "-25.0~+25.0" 338 "-25.0~+25.0" 339 "-25.0~+25.0" 340 "-25.0~+25.0" 341 "-25.0~+25.0" 342 "-25.0~+25.0" 343 "-25.0~+25.0" 344 "-25.0~+25.0" 345 "-25.0~+25.0" 346 "-25.0~+25.0" 347 "-25.0~+25.0" 348 "-25.0~+25.0" 349 "-25.0~+25.0" 350 "-25.0~+25.0" 351 "-25.0~+25.0" 352 "-25.0~+25.0" 353 "-25.0~+25.0" 354 "-25.0~+25.0" 355 "-25.0~+25.0" 356 "-25.0~+25.0" 357 "-25.0~+25.0" 358 "-25.0~+25.0" 359 "-25.0~+25.0" 360 "-25.0~+25.0" 361 "-25.0~+25.0" 362 "-25.0~+25.0" 363 "-25.0~+25.0" 364 "-25.0~+25.0" 365 "-25.0~+25.0" 366 "-25.0~+25.0" 367 "-25.0~+25.0" 368 "-25.0~+25.0" 369 "-25.0~+25.0" 370 "-25.0~+25.0" 371 "-25.0~+25.0" 372 "-25.0~+25.0" 373 "-25.0~+25.0" 374 "-25.0~+25.0" 375 "-25.0~+25.0" 376 "-25.0~+25.0" 377 "-25.0~+25.0" 378 "-25.0~+25.0" 379 "-25.0~+25.0" 380 "-25.0~+25.0" 381 "-25.0~+25.0" 382 "-25.0~+25.0" 383 "-25.0~+25.0" 384 "-25.0~+25.0" 385 "-25.0~+25.0" 386 "-25.0~+25.0" 387 "-25.0~+25.0" 388 "-25.0~+25.0" 389 "-25.0~+25.0" 390 "-25.0~+25.0" 391 "-25.0~+25.0" 392 "-25.0~+25.0" 393 "-25.0~+25.0" 394 "-25.0~+25.0" 395 "-25.0~+25.0" 396 "-25.0~+25.0" 397 "-25.0~+25.0" 398 "-25.0~+25.0" 399 "-25.0~+25.0" 400 "-25.0~+25.0" 401 "-25.0~+25.0" 402 "-25.0~+25.0" 403 "-25.0~+25.0" 404 "-25.0~+25.0" 405 "-25.0~+25.0" 406 "-25.0~+25.0" 407 "-25.0~+25.0" 408 "-25.0~+25.0" 409 "-25.0~+25.0" 410 "-25.0~+25.0" 411 "-25.0~+25.0" 412 "-25.0~+25.0" 413 "-25.0~+25.0" 414 "-25.0~+25.0" 415 "-25.0~+25.0" 416 "-25.0~+25.0" 417 "-25.0~+25.0" 418 "-25.0~+25.0" 419 "-25.0~+25.0" 420 "-25.0~+25.0" 421 "-25.0~+25.0" 422 "-25.0~+25.0" 423 "-25.0~+25.0" 424 "-25.0~+25.0" 425 "-25.0~+25.0" 426 "-25.0~+25.0" 427 "-25.0~+25.0" 428 "-25.0~+25.0" 429 "-25.0~+25.0" 430 "-25.0~+25.0" 431 "-25.0~+25.0" 432 "-25.0~+25.0" 433 "-25.0~+25.0" 434 "-25.0~+25.0" 435 "-25.0~+25.0" 436 "-25.0~+25.0" 437 "-25.0~+25.0" 438 "-25.0~+25.0" 439 "-25.0~+25.0" 440 "-25.0~+25.0" 441 "-25.0~+25.0" 442 "-25.0~+25.0" 443 "-25.0~+25.0" 444 "-25.0~+25.0" 445 "-25.0~+25.0" 446 "-25.0~+25.0" 447 "-25.0~+25.0" 448 "-25.0~+25.0" 449 "-25.0~+25.0" 450 "-25.0~+25.0" 451 "-25.0~+25.0" 452 "-25.0~+25.0" 453 "-25.0~+25.0" 454 "-25.0~+25.0" 455 "-25.0~+25.0" 456 "-25.0~+25.0" 457 "-25.0~+25.0" 458 "-25.0~+25.0" 459 "-25.0~+25.0" 460 "-25.0~+25.0" 461 "-25.0~+25.0" 462 "-25.0~+25.0" 463 "-25.0~+25.0" 464 "-25.0~+25.0" 465 "-25.0~+25.0" 466 "-25.0~+25.0" 467 "-25.0~+25.0" 468 "-25.0~+25.0" 469 "-25.0~+25.0" 470 "-25.0~+25.0" 471 "-25.0~+25.0" 472 "-25.0~+25.0" 473 "-25.0~+25.0" 474 "-25.0~+25.0" 475 "-25.0~+25.0" 476 "-25.0~+25.0" 477 "-25.0~+25.0" 478 "-25.0~+25.0" 479 "-25.0~+25.0" 480 "-25.0~+25.0" 481 "-25.0~+25.0" 482 "-25.0~+25.0" 483 "-25.0~+25.0" 484 "-25.0~+25.0" 485 "-25.0~+25.0" 486 "-25.0~+25.0" 487 "-25.0~+25.0" 488 "-25.0~+25.0" 489 "-25.0~+25.0" 490 "-25.0~+25.0" 491 "-25.0~+25.0" 492 "-25.0~+25.0" 493 "-25.0~+25.0" 494 "-25.0~+25.0" 495 "-25.0~+25.0" 496 "-25.0~+25.0" 497 "-25.0~+25.0" 498 "-25.0~+25.0" 499 "-25.0~+25.0" 500 "-25.0~+25.0" 501 "Not used" 502 "Not used" 503 "Not used" 504 "Not used" 505 "Not used" 506 "Not used" 507 "Not used" 508 "Not used" 509 "Not used" 510 "Default" 511 "Error indicator";
VAL_ 698 IFSref_VehRtAngl8Val 0 "-25.0~+25.0" 1 "-25.0~+25.0" 2 "-25.0~+25.0" 3 "-25.0~+25.0" 4 "-25.0~+25.0" 5 "-25.0~+25.0" 6 "-25.0~+25.0" 7 "-25.0~+25.0" 8 "-25.0~+25.0" 9 "-25.0~+25.0" 10 "-25.0~+25.0" 11 "-25.0~+25.0" 12 "-25.0~+25.0" 13 "-25.0~+25.0" 14 "-25.0~+25.0" 15 "-25.0~+25.0" 16 "-25.0~+25.0" 17 "-25.0~+25.0" 18 "-25.0~+25.0" 19 "-25.0~+25.0" 20 "-25.0~+25.0" 21 "-25.0~+25.0" 22 "-25.0~+25.0" 23 "-25.0~+25.0" 24 "-25.0~+25.0" 25 "-25.0~+25.0" 26 "-25.0~+25.0" 27 "-25.0~+25.0" 28 "-25.0~+25.0" 29 "-25.0~+25.0" 30 "-25.0~+25.0" 31 "-25.0~+25.0" 32 "-25.0~+25.0" 33 "-25.0~+25.0" 34 "-25.0~+25.0" 35 "-25.0~+25.0" 36 "-25.0~+25.0" 37 "-25.0~+25.0" 38 "-25.0~+25.0" 39 "-25.0~+25.0" 40 "-25.0~+25.0" 41 "-25.0~+25.0" 42 "-25.0~+25.0" 43 "-25.0~+25.0" 44 "-25.0~+25.0" 45 "-25.0~+25.0" 46 "-25.0~+25.0" 47 "-25.0~+25.0" 48 "-25.0~+25.0" 49 "-25.0~+25.0" 50 "-25.0~+25.0" 51 "-25.0~+25.0" 52 "-25.0~+25.0" 53 "-25.0~+25.0" 54 "-25.0~+25.0" 55 "-25.0~+25.0" 56 "-25.0~+25.0" 57 "-25.0~+25.0" 58 "-25.0~+25.0" 59 "-25.0~+25.0" 60 "-25.0~+25.0" 61 "-25.0~+25.0" 62 "-25.0~+25.0" 63 "-25.0~+25.0" 64 "-25.0~+25.0" 65 "-25.0~+25.0" 66 "-25.0~+25.0" 67 "-25.0~+25.0" 68 "-25.0~+25.0" 69 "-25.0~+25.0" 70 "-25.0~+25.0" 71 "-25.0~+25.0" 72 "-25.0~+25.0" 73 "-25.0~+25.0" 74 "-25.0~+25.0" 75 "-25.0~+25.0" 76 "-25.0~+25.0" 77 "-25.0~+25.0" 78 "-25.0~+25.0" 79 "-25.0~+25.0" 80 "-25.0~+25.0" 81 "-25.0~+25.0" 82 "-25.0~+25.0" 83 "-25.0~+25.0" 84 "-25.0~+25.0" 85 "-25.0~+25.0" 86 "-25.0~+25.0" 87 "-25.0~+25.0" 88 "-25.0~+25.0" 89 "-25.0~+25.0" 90 "-25.0~+25.0" 91 "-25.0~+25.0" 92 "-25.0~+25.0" 93 "-25.0~+25.0" 94 "-25.0~+25.0" 95 "-25.0~+25.0" 96 "-25.0~+25.0" 97 "-25.0~+25.0" 98 "-25.0~+25.0" 99 "-25.0~+25.0" 100 "-25.0~+25.0" 101 "-25.0~+25.0" 102 "-25.0~+25.0" 103 "-25.0~+25.0" 104 "-25.0~+25.0" 105 "-25.0~+25.0" 106 "-25.0~+25.0" 107 "-25.0~+25.0" 108 "-25.0~+25.0" 109 "-25.0~+25.0" 110 "-25.0~+25.0" 111 "-25.0~+25.0" 112 "-25.0~+25.0" 113 "-25.0~+25.0" 114 "-25.0~+25.0" 115 "-25.0~+25.0" 116 "-25.0~+25.0" 117 "-25.0~+25.0" 118 "-25.0~+25.0" 119 "-25.0~+25.0" 120 "-25.0~+25.0" 121 "-25.0~+25.0" 122 "-25.0~+25.0" 123 "-25.0~+25.0" 124 "-25.0~+25.0" 125 "-25.0~+25.0" 126 "-25.0~+25.0" 127 "-25.0~+25.0" 128 "-25.0~+25.0" 129 "-25.0~+25.0" 130 "-25.0~+25.0" 131 "-25.0~+25.0" 132 "-25.0~+25.0" 133 "-25.0~+25.0" 134 "-25.0~+25.0" 135 "-25.0~+25.0" 136 "-25.0~+25.0" 137 "-25.0~+25.0" 138 "-25.0~+25.0" 139 "-25.0~+25.0" 140 "-25.0~+25.0" 141 "-25.0~+25.0" 142 "-25.0~+25.0" 143 "-25.0~+25.0" 144 "-25.0~+25.0" 145 "-25.0~+25.0" 146 "-25.0~+25.0" 147 "-25.0~+25.0" 148 "-25.0~+25.0" 149 "-25.0~+25.0" 150 "-25.0~+25.0" 151 "-25.0~+25.0" 152 "-25.0~+25.0" 153 "-25.0~+25.0" 154 "-25.0~+25.0" 155 "-25.0~+25.0" 156 "-25.0~+25.0" 157 "-25.0~+25.0" 158 "-25.0~+25.0" 159 "-25.0~+25.0" 160 "-25.0~+25.0" 161 "-25.0~+25.0" 162 "-25.0~+25.0" 163 "-25.0~+25.0" 164 "-25.0~+25.0" 165 "-25.0~+25.0" 166 "-25.0~+25.0" 167 "-25.0~+25.0" 168 "-25.0~+25.0" 169 "-25.0~+25.0" 170 "-25.0~+25.0" 171 "-25.0~+25.0" 172 "-25.0~+25.0" 173 "-25.0~+25.0" 174 "-25.0~+25.0" 175 "-25.0~+25.0" 176 "-25.0~+25.0" 177 "-25.0~+25.0" 178 "-25.0~+25.0" 179 "-25.0~+25.0" 180 "-25.0~+25.0" 181 "-25.0~+25.0" 182 "-25.0~+25.0" 183 "-25.0~+25.0" 184 "-25.0~+25.0" 185 "-25.0~+25.0" 186 "-25.0~+25.0" 187 "-25.0~+25.0" 188 "-25.0~+25.0" 189 "-25.0~+25.0" 190 "-25.0~+25.0" 191 "-25.0~+25.0" 192 "-25.0~+25.0" 193 "-25.0~+25.0" 194 "-25.0~+25.0" 195 "-25.0~+25.0" 196 "-25.0~+25.0" 197 "-25.0~+25.0" 198 "-25.0~+25.0" 199 "-25.0~+25.0" 200 "-25.0~+25.0" 201 "-25.0~+25.0" 202 "-25.0~+25.0" 203 "-25.0~+25.0" 204 "-25.0~+25.0" 205 "-25.0~+25.0" 206 "-25.0~+25.0" 207 "-25.0~+25.0" 208 "-25.0~+25.0" 209 "-25.0~+25.0" 210 "-25.0~+25.0" 211 "-25.0~+25.0" 212 "-25.0~+25.0" 213 "-25.0~+25.0" 214 "-25.0~+25.0" 215 "-25.0~+25.0" 216 "-25.0~+25.0" 217 "-25.0~+25.0" 218 "-25.0~+25.0" 219 "-25.0~+25.0" 220 "-25.0~+25.0" 221 "-25.0~+25.0" 222 "-25.0~+25.0" 223 "-25.0~+25.0" 224 "-25.0~+25.0" 225 "-25.0~+25.0" 226 "-25.0~+25.0" 227 "-25.0~+25.0" 228 "-25.0~+25.0" 229 "-25.0~+25.0" 230 "-25.0~+25.0" 231 "-25.0~+25.0" 232 "-25.0~+25.0" 233 "-25.0~+25.0" 234 "-25.0~+25.0" 235 "-25.0~+25.0" 236 "-25.0~+25.0" 237 "-25.0~+25.0" 238 "-25.0~+25.0" 239 "-25.0~+25.0" 240 "-25.0~+25.0" 241 "-25.0~+25.0" 242 "-25.0~+25.0" 243 "-25.0~+25.0" 244 "-25.0~+25.0" 245 "-25.0~+25.0" 246 "-25.0~+25.0" 247 "-25.0~+25.0" 248 "-25.0~+25.0" 249 "-25.0~+25.0" 250 "-25.0~+25.0" 251 "-25.0~+25.0" 252 "-25.0~+25.0" 253 "-25.0~+25.0" 254 "-25.0~+25.0" 255 "-25.0~+25.0" 256 "-25.0~+25.0" 257 "-25.0~+25.0" 258 "-25.0~+25.0" 259 "-25.0~+25.0" 260 "-25.0~+25.0" 261 "-25.0~+25.0" 262 "-25.0~+25.0" 263 "-25.0~+25.0" 264 "-25.0~+25.0" 265 "-25.0~+25.0" 266 "-25.0~+25.0" 267 "-25.0~+25.0" 268 "-25.0~+25.0" 269 "-25.0~+25.0" 270 "-25.0~+25.0" 271 "-25.0~+25.0" 272 "-25.0~+25.0" 273 "-25.0~+25.0" 274 "-25.0~+25.0" 275 "-25.0~+25.0" 276 "-25.0~+25.0" 277 "-25.0~+25.0" 278 "-25.0~+25.0" 279 "-25.0~+25.0" 280 "-25.0~+25.0" 281 "-25.0~+25.0" 282 "-25.0~+25.0" 283 "-25.0~+25.0" 284 "-25.0~+25.0" 285 "-25.0~+25.0" 286 "-25.0~+25.0" 287 "-25.0~+25.0" 288 "-25.0~+25.0" 289 "-25.0~+25.0" 290 "-25.0~+25.0" 291 "-25.0~+25.0" 292 "-25.0~+25.0" 293 "-25.0~+25.0" 294 "-25.0~+25.0" 295 "-25.0~+25.0" 296 "-25.0~+25.0" 297 "-25.0~+25.0" 298 "-25.0~+25.0" 299 "-25.0~+25.0" 300 "-25.0~+25.0" 301 "-25.0~+25.0" 302 "-25.0~+25.0" 303 "-25.0~+25.0" 304 "-25.0~+25.0" 305 "-25.0~+25.0" 306 "-25.0~+25.0" 307 "-25.0~+25.0" 308 "-25.0~+25.0" 309 "-25.0~+25.0" 310 "-25.0~+25.0" 311 "-25.0~+25.0" 312 "-25.0~+25.0" 313 "-25.0~+25.0" 314 "-25.0~+25.0" 315 "-25.0~+25.0" 316 "-25.0~+25.0" 317 "-25.0~+25.0" 318 "-25.0~+25.0" 319 "-25.0~+25.0" 320 "-25.0~+25.0" 321 "-25.0~+25.0" 322 "-25.0~+25.0" 323 "-25.0~+25.0" 324 "-25.0~+25.0" 325 "-25.0~+25.0" 326 "-25.0~+25.0" 327 "-25.0~+25.0" 328 "-25.0~+25.0" 329 "-25.0~+25.0" 330 "-25.0~+25.0" 331 "-25.0~+25.0" 332 "-25.0~+25.0" 333 "-25.0~+25.0" 334 "-25.0~+25.0" 335 "-25.0~+25.0" 336 "-25.0~+25.0" 337 "-25.0~+25.0" 338 "-25.0~+25.0" 339 "-25.0~+25.0" 340 "-25.0~+25.0" 341 "-25.0~+25.0" 342 "-25.0~+25.0" 343 "-25.0~+25.0" 344 "-25.0~+25.0" 345 "-25.0~+25.0" 346 "-25.0~+25.0" 347 "-25.0~+25.0" 348 "-25.0~+25.0" 349 "-25.0~+25.0" 350 "-25.0~+25.0" 351 "-25.0~+25.0" 352 "-25.0~+25.0" 353 "-25.0~+25.0" 354 "-25.0~+25.0" 355 "-25.0~+25.0" 356 "-25.0~+25.0" 357 "-25.0~+25.0" 358 "-25.0~+25.0" 359 "-25.0~+25.0" 360 "-25.0~+25.0" 361 "-25.0~+25.0" 362 "-25.0~+25.0" 363 "-25.0~+25.0" 364 "-25.0~+25.0" 365 "-25.0~+25.0" 366 "-25.0~+25.0" 367 "-25.0~+25.0" 368 "-25.0~+25.0" 369 "-25.0~+25.0" 370 "-25.0~+25.0" 371 "-25.0~+25.0" 372 "-25.0~+25.0" 373 "-25.0~+25.0" 374 "-25.0~+25.0" 375 "-25.0~+25.0" 376 "-25.0~+25.0" 377 "-25.0~+25.0" 378 "-25.0~+25.0" 379 "-25.0~+25.0" 380 "-25.0~+25.0" 381 "-25.0~+25.0" 382 "-25.0~+25.0" 383 "-25.0~+25.0" 384 "-25.0~+25.0" 385 "-25.0~+25.0" 386 "-25.0~+25.0" 387 "-25.0~+25.0" 388 "-25.0~+25.0" 389 "-25.0~+25.0" 390 "-25.0~+25.0" 391 "-25.0~+25.0" 392 "-25.0~+25.0" 393 "-25.0~+25.0" 394 "-25.0~+25.0" 395 "-25.0~+25.0" 396 "-25.0~+25.0" 397 "-25.0~+25.0" 398 "-25.0~+25.0" 399 "-25.0~+25.0" 400 "-25.0~+25.0" 401 "-25.0~+25.0" 402 "-25.0~+25.0" 403 "-25.0~+25.0" 404 "-25.0~+25.0" 405 "-25.0~+25.0" 406 "-25.0~+25.0" 407 "-25.0~+25.0" 408 "-25.0~+25.0" 409 "-25.0~+25.0" 410 "-25.0~+25.0" 411 "-25.0~+25.0" 412 "-25.0~+25.0" 413 "-25.0~+25.0" 414 "-25.0~+25.0" 415 "-25.0~+25.0" 416 "-25.0~+25.0" 417 "-25.0~+25.0" 418 "-25.0~+25.0" 419 "-25.0~+25.0" 420 "-25.0~+25.0" 421 "-25.0~+25.0" 422 "-25.0~+25.0" 423 "-25.0~+25.0" 424 "-25.0~+25.0" 425 "-25.0~+25.0" 426 "-25.0~+25.0" 427 "-25.0~+25.0" 428 "-25.0~+25.0" 429 "-25.0~+25.0" 430 "-25.0~+25.0" 431 "-25.0~+25.0" 432 "-25.0~+25.0" 433 "-25.0~+25.0" 434 "-25.0~+25.0" 435 "-25.0~+25.0" 436 "-25.0~+25.0" 437 "-25.0~+25.0" 438 "-25.0~+25.0" 439 "-25.0~+25.0" 440 "-25.0~+25.0" 441 "-25.0~+25.0" 442 "-25.0~+25.0" 443 "-25.0~+25.0" 444 "-25.0~+25.0" 445 "-25.0~+25.0" 446 "-25.0~+25.0" 447 "-25.0~+25.0" 448 "-25.0~+25.0" 449 "-25.0~+25.0" 450 "-25.0~+25.0" 451 "-25.0~+25.0" 452 "-25.0~+25.0" 453 "-25.0~+25.0" 454 "-25.0~+25.0" 455 "-25.0~+25.0" 456 "-25.0~+25.0" 457 "-25.0~+25.0" 458 "-25.0~+25.0" 459 "-25.0~+25.0" 460 "-25.0~+25.0" 461 "-25.0~+25.0" 462 "-25.0~+25.0" 463 "-25.0~+25.0" 464 "-25.0~+25.0" 465 "-25.0~+25.0" 466 "-25.0~+25.0" 467 "-25.0~+25.0" 468 "-25.0~+25.0" 469 "-25.0~+25.0" 470 "-25.0~+25.0" 471 "-25.0~+25.0" 472 "-25.0~+25.0" 473 "-25.0~+25.0" 474 "-25.0~+25.0" 475 "-25.0~+25.0" 476 "-25.0~+25.0" 477 "-25.0~+25.0" 478 "-25.0~+25.0" 479 "-25.0~+25.0" 480 "-25.0~+25.0" 481 "-25.0~+25.0" 482 "-25.0~+25.0" 483 "-25.0~+25.0" 484 "-25.0~+25.0" 485 "-25.0~+25.0" 486 "-25.0~+25.0" 487 "-25.0~+25.0" 488 "-25.0~+25.0" 489 "-25.0~+25.0" 490 "-25.0~+25.0" 491 "-25.0~+25.0" 492 "-25.0~+25.0" 493 "-25.0~+25.0" 494 "-25.0~+25.0" 495 "-25.0~+25.0" 496 "-25.0~+25.0" 497 "-25.0~+25.0" 498 "-25.0~+25.0" 499 "-25.0~+25.0" 500 "-25.0~+25.0" 501 "Not used" 502 "Not used" 503 "Not used" 504 "Not used" 505 "Not used" 506 "Not used" 507 "Not used" 508 "Not used" 509 "Not used" 510 "Default" 511 "Error indicator";
VAL_ 698 IFSref_VehLftAngl9Val 0 "-25.0~+25.0" 1 "-25.0~+25.0" 2 "-25.0~+25.0" 3 "-25.0~+25.0" 4 "-25.0~+25.0" 5 "-25.0~+25.0" 6 "-25.0~+25.0" 7 "-25.0~+25.0" 8 "-25.0~+25.0" 9 "-25.0~+25.0" 10 "-25.0~+25.0" 11 "-25.0~+25.0" 12 "-25.0~+25.0" 13 "-25.0~+25.0" 14 "-25.0~+25.0" 15 "-25.0~+25.0" 16 "-25.0~+25.0" 17 "-25.0~+25.0" 18 "-25.0~+25.0" 19 "-25.0~+25.0" 20 "-25.0~+25.0" 21 "-25.0~+25.0" 22 "-25.0~+25.0" 23 "-25.0~+25.0" 24 "-25.0~+25.0" 25 "-25.0~+25.0" 26 "-25.0~+25.0" 27 "-25.0~+25.0" 28 "-25.0~+25.0" 29 "-25.0~+25.0" 30 "-25.0~+25.0" 31 "-25.0~+25.0" 32 "-25.0~+25.0" 33 "-25.0~+25.0" 34 "-25.0~+25.0" 35 "-25.0~+25.0" 36 "-25.0~+25.0" 37 "-25.0~+25.0" 38 "-25.0~+25.0" 39 "-25.0~+25.0" 40 "-25.0~+25.0" 41 "-25.0~+25.0" 42 "-25.0~+25.0" 43 "-25.0~+25.0" 44 "-25.0~+25.0" 45 "-25.0~+25.0" 46 "-25.0~+25.0" 47 "-25.0~+25.0" 48 "-25.0~+25.0" 49 "-25.0~+25.0" 50 "-25.0~+25.0" 51 "-25.0~+25.0" 52 "-25.0~+25.0" 53 "-25.0~+25.0" 54 "-25.0~+25.0" 55 "-25.0~+25.0" 56 "-25.0~+25.0" 57 "-25.0~+25.0" 58 "-25.0~+25.0" 59 "-25.0~+25.0" 60 "-25.0~+25.0" 61 "-25.0~+25.0" 62 "-25.0~+25.0" 63 "-25.0~+25.0" 64 "-25.0~+25.0" 65 "-25.0~+25.0" 66 "-25.0~+25.0" 67 "-25.0~+25.0" 68 "-25.0~+25.0" 69 "-25.0~+25.0" 70 "-25.0~+25.0" 71 "-25.0~+25.0" 72 "-25.0~+25.0" 73 "-25.0~+25.0" 74 "-25.0~+25.0" 75 "-25.0~+25.0" 76 "-25.0~+25.0" 77 "-25.0~+25.0" 78 "-25.0~+25.0" 79 "-25.0~+25.0" 80 "-25.0~+25.0" 81 "-25.0~+25.0" 82 "-25.0~+25.0" 83 "-25.0~+25.0" 84 "-25.0~+25.0" 85 "-25.0~+25.0" 86 "-25.0~+25.0" 87 "-25.0~+25.0" 88 "-25.0~+25.0" 89 "-25.0~+25.0" 90 "-25.0~+25.0" 91 "-25.0~+25.0" 92 "-25.0~+25.0" 93 "-25.0~+25.0" 94 "-25.0~+25.0" 95 "-25.0~+25.0" 96 "-25.0~+25.0" 97 "-25.0~+25.0" 98 "-25.0~+25.0" 99 "-25.0~+25.0" 100 "-25.0~+25.0" 101 "-25.0~+25.0" 102 "-25.0~+25.0" 103 "-25.0~+25.0" 104 "-25.0~+25.0" 105 "-25.0~+25.0" 106 "-25.0~+25.0" 107 "-25.0~+25.0" 108 "-25.0~+25.0" 109 "-25.0~+25.0" 110 "-25.0~+25.0" 111 "-25.0~+25.0" 112 "-25.0~+25.0" 113 "-25.0~+25.0" 114 "-25.0~+25.0" 115 "-25.0~+25.0" 116 "-25.0~+25.0" 117 "-25.0~+25.0" 118 "-25.0~+25.0" 119 "-25.0~+25.0" 120 "-25.0~+25.0" 121 "-25.0~+25.0" 122 "-25.0~+25.0" 123 "-25.0~+25.0" 124 "-25.0~+25.0" 125 "-25.0~+25.0" 126 "-25.0~+25.0" 127 "-25.0~+25.0" 128 "-25.0~+25.0" 129 "-25.0~+25.0" 130 "-25.0~+25.0" 131 "-25.0~+25.0" 132 "-25.0~+25.0" 133 "-25.0~+25.0" 134 "-25.0~+25.0" 135 "-25.0~+25.0" 136 "-25.0~+25.0" 137 "-25.0~+25.0" 138 "-25.0~+25.0" 139 "-25.0~+25.0" 140 "-25.0~+25.0" 141 "-25.0~+25.0" 142 "-25.0~+25.0" 143 "-25.0~+25.0" 144 "-25.0~+25.0" 145 "-25.0~+25.0" 146 "-25.0~+25.0" 147 "-25.0~+25.0" 148 "-25.0~+25.0" 149 "-25.0~+25.0" 150 "-25.0~+25.0" 151 "-25.0~+25.0" 152 "-25.0~+25.0" 153 "-25.0~+25.0" 154 "-25.0~+25.0" 155 "-25.0~+25.0" 156 "-25.0~+25.0" 157 "-25.0~+25.0" 158 "-25.0~+25.0" 159 "-25.0~+25.0" 160 "-25.0~+25.0" 161 "-25.0~+25.0" 162 "-25.0~+25.0" 163 "-25.0~+25.0" 164 "-25.0~+25.0" 165 "-25.0~+25.0" 166 "-25.0~+25.0" 167 "-25.0~+25.0" 168 "-25.0~+25.0" 169 "-25.0~+25.0" 170 "-25.0~+25.0" 171 "-25.0~+25.0" 172 "-25.0~+25.0" 173 "-25.0~+25.0" 174 "-25.0~+25.0" 175 "-25.0~+25.0" 176 "-25.0~+25.0" 177 "-25.0~+25.0" 178 "-25.0~+25.0" 179 "-25.0~+25.0" 180 "-25.0~+25.0" 181 "-25.0~+25.0" 182 "-25.0~+25.0" 183 "-25.0~+25.0" 184 "-25.0~+25.0" 185 "-25.0~+25.0" 186 "-25.0~+25.0" 187 "-25.0~+25.0" 188 "-25.0~+25.0" 189 "-25.0~+25.0" 190 "-25.0~+25.0" 191 "-25.0~+25.0" 192 "-25.0~+25.0" 193 "-25.0~+25.0" 194 "-25.0~+25.0" 195 "-25.0~+25.0" 196 "-25.0~+25.0" 197 "-25.0~+25.0" 198 "-25.0~+25.0" 199 "-25.0~+25.0" 200 "-25.0~+25.0" 201 "-25.0~+25.0" 202 "-25.0~+25.0" 203 "-25.0~+25.0" 204 "-25.0~+25.0" 205 "-25.0~+25.0" 206 "-25.0~+25.0" 207 "-25.0~+25.0" 208 "-25.0~+25.0" 209 "-25.0~+25.0" 210 "-25.0~+25.0" 211 "-25.0~+25.0" 212 "-25.0~+25.0" 213 "-25.0~+25.0" 214 "-25.0~+25.0" 215 "-25.0~+25.0" 216 "-25.0~+25.0" 217 "-25.0~+25.0" 218 "-25.0~+25.0" 219 "-25.0~+25.0" 220 "-25.0~+25.0" 221 "-25.0~+25.0" 222 "-25.0~+25.0" 223 "-25.0~+25.0" 224 "-25.0~+25.0" 225 "-25.0~+25.0" 226 "-25.0~+25.0" 227 "-25.0~+25.0" 228 "-25.0~+25.0" 229 "-25.0~+25.0" 230 "-25.0~+25.0" 231 "-25.0~+25.0" 232 "-25.0~+25.0" 233 "-25.0~+25.0" 234 "-25.0~+25.0" 235 "-25.0~+25.0" 236 "-25.0~+25.0" 237 "-25.0~+25.0" 238 "-25.0~+25.0" 239 "-25.0~+25.0" 240 "-25.0~+25.0" 241 "-25.0~+25.0" 242 "-25.0~+25.0" 243 "-25.0~+25.0" 244 "-25.0~+25.0" 245 "-25.0~+25.0" 246 "-25.0~+25.0" 247 "-25.0~+25.0" 248 "-25.0~+25.0" 249 "-25.0~+25.0" 250 "-25.0~+25.0" 251 "-25.0~+25.0" 252 "-25.0~+25.0" 253 "-25.0~+25.0" 254 "-25.0~+25.0" 255 "-25.0~+25.0" 256 "-25.0~+25.0" 257 "-25.0~+25.0" 258 "-25.0~+25.0" 259 "-25.0~+25.0" 260 "-25.0~+25.0" 261 "-25.0~+25.0" 262 "-25.0~+25.0" 263 "-25.0~+25.0" 264 "-25.0~+25.0" 265 "-25.0~+25.0" 266 "-25.0~+25.0" 267 "-25.0~+25.0" 268 "-25.0~+25.0" 269 "-25.0~+25.0" 270 "-25.0~+25.0" 271 "-25.0~+25.0" 272 "-25.0~+25.0" 273 "-25.0~+25.0" 274 "-25.0~+25.0" 275 "-25.0~+25.0" 276 "-25.0~+25.0" 277 "-25.0~+25.0" 278 "-25.0~+25.0" 279 "-25.0~+25.0" 280 "-25.0~+25.0" 281 "-25.0~+25.0" 282 "-25.0~+25.0" 283 "-25.0~+25.0" 284 "-25.0~+25.0" 285 "-25.0~+25.0" 286 "-25.0~+25.0" 287 "-25.0~+25.0" 288 "-25.0~+25.0" 289 "-25.0~+25.0" 290 "-25.0~+25.0" 291 "-25.0~+25.0" 292 "-25.0~+25.0" 293 "-25.0~+25.0" 294 "-25.0~+25.0" 295 "-25.0~+25.0" 296 "-25.0~+25.0" 297 "-25.0~+25.0" 298 "-25.0~+25.0" 299 "-25.0~+25.0" 300 "-25.0~+25.0" 301 "-25.0~+25.0" 302 "-25.0~+25.0" 303 "-25.0~+25.0" 304 "-25.0~+25.0" 305 "-25.0~+25.0" 306 "-25.0~+25.0" 307 "-25.0~+25.0" 308 "-25.0~+25.0" 309 "-25.0~+25.0" 310 "-25.0~+25.0" 311 "-25.0~+25.0" 312 "-25.0~+25.0" 313 "-25.0~+25.0" 314 "-25.0~+25.0" 315 "-25.0~+25.0" 316 "-25.0~+25.0" 317 "-25.0~+25.0" 318 "-25.0~+25.0" 319 "-25.0~+25.0" 320 "-25.0~+25.0" 321 "-25.0~+25.0" 322 "-25.0~+25.0" 323 "-25.0~+25.0" 324 "-25.0~+25.0" 325 "-25.0~+25.0" 326 "-25.0~+25.0" 327 "-25.0~+25.0" 328 "-25.0~+25.0" 329 "-25.0~+25.0" 330 "-25.0~+25.0" 331 "-25.0~+25.0" 332 "-25.0~+25.0" 333 "-25.0~+25.0" 334 "-25.0~+25.0" 335 "-25.0~+25.0" 336 "-25.0~+25.0" 337 "-25.0~+25.0" 338 "-25.0~+25.0" 339 "-25.0~+25.0" 340 "-25.0~+25.0" 341 "-25.0~+25.0" 342 "-25.0~+25.0" 343 "-25.0~+25.0" 344 "-25.0~+25.0" 345 "-25.0~+25.0" 346 "-25.0~+25.0" 347 "-25.0~+25.0" 348 "-25.0~+25.0" 349 "-25.0~+25.0" 350 "-25.0~+25.0" 351 "-25.0~+25.0" 352 "-25.0~+25.0" 353 "-25.0~+25.0" 354 "-25.0~+25.0" 355 "-25.0~+25.0" 356 "-25.0~+25.0" 357 "-25.0~+25.0" 358 "-25.0~+25.0" 359 "-25.0~+25.0" 360 "-25.0~+25.0" 361 "-25.0~+25.0" 362 "-25.0~+25.0" 363 "-25.0~+25.0" 364 "-25.0~+25.0" 365 "-25.0~+25.0" 366 "-25.0~+25.0" 367 "-25.0~+25.0" 368 "-25.0~+25.0" 369 "-25.0~+25.0" 370 "-25.0~+25.0" 371 "-25.0~+25.0" 372 "-25.0~+25.0" 373 "-25.0~+25.0" 374 "-25.0~+25.0" 375 "-25.0~+25.0" 376 "-25.0~+25.0" 377 "-25.0~+25.0" 378 "-25.0~+25.0" 379 "-25.0~+25.0" 380 "-25.0~+25.0" 381 "-25.0~+25.0" 382 "-25.0~+25.0" 383 "-25.0~+25.0" 384 "-25.0~+25.0" 385 "-25.0~+25.0" 386 "-25.0~+25.0" 387 "-25.0~+25.0" 388 "-25.0~+25.0" 389 "-25.0~+25.0" 390 "-25.0~+25.0" 391 "-25.0~+25.0" 392 "-25.0~+25.0" 393 "-25.0~+25.0" 394 "-25.0~+25.0" 395 "-25.0~+25.0" 396 "-25.0~+25.0" 397 "-25.0~+25.0" 398 "-25.0~+25.0" 399 "-25.0~+25.0" 400 "-25.0~+25.0" 401 "-25.0~+25.0" 402 "-25.0~+25.0" 403 "-25.0~+25.0" 404 "-25.0~+25.0" 405 "-25.0~+25.0" 406 "-25.0~+25.0" 407 "-25.0~+25.0" 408 "-25.0~+25.0" 409 "-25.0~+25.0" 410 "-25.0~+25.0" 411 "-25.0~+25.0" 412 "-25.0~+25.0" 413 "-25.0~+25.0" 414 "-25.0~+25.0" 415 "-25.0~+25.0" 416 "-25.0~+25.0" 417 "-25.0~+25.0" 418 "-25.0~+25.0" 419 "-25.0~+25.0" 420 "-25.0~+25.0" 421 "-25.0~+25.0" 422 "-25.0~+25.0" 423 "-25.0~+25.0" 424 "-25.0~+25.0" 425 "-25.0~+25.0" 426 "-25.0~+25.0" 427 "-25.0~+25.0" 428 "-25.0~+25.0" 429 "-25.0~+25.0" 430 "-25.0~+25.0" 431 "-25.0~+25.0" 432 "-25.0~+25.0" 433 "-25.0~+25.0" 434 "-25.0~+25.0" 435 "-25.0~+25.0" 436 "-25.0~+25.0" 437 "-25.0~+25.0" 438 "-25.0~+25.0" 439 "-25.0~+25.0" 440 "-25.0~+25.0" 441 "-25.0~+25.0" 442 "-25.0~+25.0" 443 "-25.0~+25.0" 444 "-25.0~+25.0" 445 "-25.0~+25.0" 446 "-25.0~+25.0" 447 "-25.0~+25.0" 448 "-25.0~+25.0" 449 "-25.0~+25.0" 450 "-25.0~+25.0" 451 "-25.0~+25.0" 452 "-25.0~+25.0" 453 "-25.0~+25.0" 454 "-25.0~+25.0" 455 "-25.0~+25.0" 456 "-25.0~+25.0" 457 "-25.0~+25.0" 458 "-25.0~+25.0" 459 "-25.0~+25.0" 460 "-25.0~+25.0" 461 "-25.0~+25.0" 462 "-25.0~+25.0" 463 "-25.0~+25.0" 464 "-25.0~+25.0" 465 "-25.0~+25.0" 466 "-25.0~+25.0" 467 "-25.0~+25.0" 468 "-25.0~+25.0" 469 "-25.0~+25.0" 470 "-25.0~+25.0" 471 "-25.0~+25.0" 472 "-25.0~+25.0" 473 "-25.0~+25.0" 474 "-25.0~+25.0" 475 "-25.0~+25.0" 476 "-25.0~+25.0" 477 "-25.0~+25.0" 478 "-25.0~+25.0" 479 "-25.0~+25.0" 480 "-25.0~+25.0" 481 "-25.0~+25.0" 482 "-25.0~+25.0" 483 "-25.0~+25.0" 484 "-25.0~+25.0" 485 "-25.0~+25.0" 486 "-25.0~+25.0" 487 "-25.0~+25.0" 488 "-25.0~+25.0" 489 "-25.0~+25.0" 490 "-25.0~+25.0" 491 "-25.0~+25.0" 492 "-25.0~+25.0" 493 "-25.0~+25.0" 494 "-25.0~+25.0" 495 "-25.0~+25.0" 496 "-25.0~+25.0" 497 "-25.0~+25.0" 498 "-25.0~+25.0" 499 "-25.0~+25.0" 500 "-25.0~+25.0" 501 "Not used" 502 "Not used" 503 "Not used" 504 "Not used" 505 "Not used" 506 "Not used" 507 "Not used" 508 "Not used" 509 "Not used" 510 "Default" 511 "Error indicator";
VAL_ 698 IFSref_VehRtAngl9Val 0 "-25.0~+25.0" 1 "-25.0~+25.0" 2 "-25.0~+25.0" 3 "-25.0~+25.0" 4 "-25.0~+25.0" 5 "-25.0~+25.0" 6 "-25.0~+25.0" 7 "-25.0~+25.0" 8 "-25.0~+25.0" 9 "-25.0~+25.0" 10 "-25.0~+25.0" 11 "-25.0~+25.0" 12 "-25.0~+25.0" 13 "-25.0~+25.0" 14 "-25.0~+25.0" 15 "-25.0~+25.0" 16 "-25.0~+25.0" 17 "-25.0~+25.0" 18 "-25.0~+25.0" 19 "-25.0~+25.0" 20 "-25.0~+25.0" 21 "-25.0~+25.0" 22 "-25.0~+25.0" 23 "-25.0~+25.0" 24 "-25.0~+25.0" 25 "-25.0~+25.0" 26 "-25.0~+25.0" 27 "-25.0~+25.0" 28 "-25.0~+25.0" 29 "-25.0~+25.0" 30 "-25.0~+25.0" 31 "-25.0~+25.0" 32 "-25.0~+25.0" 33 "-25.0~+25.0" 34 "-25.0~+25.0" 35 "-25.0~+25.0" 36 "-25.0~+25.0" 37 "-25.0~+25.0" 38 "-25.0~+25.0" 39 "-25.0~+25.0" 40 "-25.0~+25.0" 41 "-25.0~+25.0" 42 "-25.0~+25.0" 43 "-25.0~+25.0" 44 "-25.0~+25.0" 45 "-25.0~+25.0" 46 "-25.0~+25.0" 47 "-25.0~+25.0" 48 "-25.0~+25.0" 49 "-25.0~+25.0" 50 "-25.0~+25.0" 51 "-25.0~+25.0" 52 "-25.0~+25.0" 53 "-25.0~+25.0" 54 "-25.0~+25.0" 55 "-25.0~+25.0" 56 "-25.0~+25.0" 57 "-25.0~+25.0" 58 "-25.0~+25.0" 59 "-25.0~+25.0" 60 "-25.0~+25.0" 61 "-25.0~+25.0" 62 "-25.0~+25.0" 63 "-25.0~+25.0" 64 "-25.0~+25.0" 65 "-25.0~+25.0" 66 "-25.0~+25.0" 67 "-25.0~+25.0" 68 "-25.0~+25.0" 69 "-25.0~+25.0" 70 "-25.0~+25.0" 71 "-25.0~+25.0" 72 "-25.0~+25.0" 73 "-25.0~+25.0" 74 "-25.0~+25.0" 75 "-25.0~+25.0" 76 "-25.0~+25.0" 77 "-25.0~+25.0" 78 "-25.0~+25.0" 79 "-25.0~+25.0" 80 "-25.0~+25.0" 81 "-25.0~+25.0" 82 "-25.0~+25.0" 83 "-25.0~+25.0" 84 "-25.0~+25.0" 85 "-25.0~+25.0" 86 "-25.0~+25.0" 87 "-25.0~+25.0" 88 "-25.0~+25.0" 89 "-25.0~+25.0" 90 "-25.0~+25.0" 91 "-25.0~+25.0" 92 "-25.0~+25.0" 93 "-25.0~+25.0" 94 "-25.0~+25.0" 95 "-25.0~+25.0" 96 "-25.0~+25.0" 97 "-25.0~+25.0" 98 "-25.0~+25.0" 99 "-25.0~+25.0" 100 "-25.0~+25.0" 101 "-25.0~+25.0" 102 "-25.0~+25.0" 103 "-25.0~+25.0" 104 "-25.0~+25.0" 105 "-25.0~+25.0" 106 "-25.0~+25.0" 107 "-25.0~+25.0" 108 "-25.0~+25.0" 109 "-25.0~+25.0" 110 "-25.0~+25.0" 111 "-25.0~+25.0" 112 "-25.0~+25.0" 113 "-25.0~+25.0" 114 "-25.0~+25.0" 115 "-25.0~+25.0" 116 "-25.0~+25.0" 117 "-25.0~+25.0" 118 "-25.0~+25.0" 119 "-25.0~+25.0" 120 "-25.0~+25.0" 121 "-25.0~+25.0" 122 "-25.0~+25.0" 123 "-25.0~+25.0" 124 "-25.0~+25.0" 125 "-25.0~+25.0" 126 "-25.0~+25.0" 127 "-25.0~+25.0" 128 "-25.0~+25.0" 129 "-25.0~+25.0" 130 "-25.0~+25.0" 131 "-25.0~+25.0" 132 "-25.0~+25.0" 133 "-25.0~+25.0" 134 "-25.0~+25.0" 135 "-25.0~+25.0" 136 "-25.0~+25.0" 137 "-25.0~+25.0" 138 "-25.0~+25.0" 139 "-25.0~+25.0" 140 "-25.0~+25.0" 141 "-25.0~+25.0" 142 "-25.0~+25.0" 143 "-25.0~+25.0" 144 "-25.0~+25.0" 145 "-25.0~+25.0" 146 "-25.0~+25.0" 147 "-25.0~+25.0" 148 "-25.0~+25.0" 149 "-25.0~+25.0" 150 "-25.0~+25.0" 151 "-25.0~+25.0" 152 "-25.0~+25.0" 153 "-25.0~+25.0" 154 "-25.0~+25.0" 155 "-25.0~+25.0" 156 "-25.0~+25.0" 157 "-25.0~+25.0" 158 "-25.0~+25.0" 159 "-25.0~+25.0" 160 "-25.0~+25.0" 161 "-25.0~+25.0" 162 "-25.0~+25.0" 163 "-25.0~+25.0" 164 "-25.0~+25.0" 165 "-25.0~+25.0" 166 "-25.0~+25.0" 167 "-25.0~+25.0" 168 "-25.0~+25.0" 169 "-25.0~+25.0" 170 "-25.0~+25.0" 171 "-25.0~+25.0" 172 "-25.0~+25.0" 173 "-25.0~+25.0" 174 "-25.0~+25.0" 175 "-25.0~+25.0" 176 "-25.0~+25.0" 177 "-25.0~+25.0" 178 "-25.0~+25.0" 179 "-25.0~+25.0" 180 "-25.0~+25.0" 181 "-25.0~+25.0" 182 "-25.0~+25.0" 183 "-25.0~+25.0" 184 "-25.0~+25.0" 185 "-25.0~+25.0" 186 "-25.0~+25.0" 187 "-25.0~+25.0" 188 "-25.0~+25.0" 189 "-25.0~+25.0" 190 "-25.0~+25.0" 191 "-25.0~+25.0" 192 "-25.0~+25.0" 193 "-25.0~+25.0" 194 "-25.0~+25.0" 195 "-25.0~+25.0" 196 "-25.0~+25.0" 197 "-25.0~+25.0" 198 "-25.0~+25.0" 199 "-25.0~+25.0" 200 "-25.0~+25.0" 201 "-25.0~+25.0" 202 "-25.0~+25.0" 203 "-25.0~+25.0" 204 "-25.0~+25.0" 205 "-25.0~+25.0" 206 "-25.0~+25.0" 207 "-25.0~+25.0" 208 "-25.0~+25.0" 209 "-25.0~+25.0" 210 "-25.0~+25.0" 211 "-25.0~+25.0" 212 "-25.0~+25.0" 213 "-25.0~+25.0" 214 "-25.0~+25.0" 215 "-25.0~+25.0" 216 "-25.0~+25.0" 217 "-25.0~+25.0" 218 "-25.0~+25.0" 219 "-25.0~+25.0" 220 "-25.0~+25.0" 221 "-25.0~+25.0" 222 "-25.0~+25.0" 223 "-25.0~+25.0" 224 "-25.0~+25.0" 225 "-25.0~+25.0" 226 "-25.0~+25.0" 227 "-25.0~+25.0" 228 "-25.0~+25.0" 229 "-25.0~+25.0" 230 "-25.0~+25.0" 231 "-25.0~+25.0" 232 "-25.0~+25.0" 233 "-25.0~+25.0" 234 "-25.0~+25.0" 235 "-25.0~+25.0" 236 "-25.0~+25.0" 237 "-25.0~+25.0" 238 "-25.0~+25.0" 239 "-25.0~+25.0" 240 "-25.0~+25.0" 241 "-25.0~+25.0" 242 "-25.0~+25.0" 243 "-25.0~+25.0" 244 "-25.0~+25.0" 245 "-25.0~+25.0" 246 "-25.0~+25.0" 247 "-25.0~+25.0" 248 "-25.0~+25.0" 249 "-25.0~+25.0" 250 "-25.0~+25.0" 251 "-25.0~+25.0" 252 "-25.0~+25.0" 253 "-25.0~+25.0" 254 "-25.0~+25.0" 255 "-25.0~+25.0" 256 "-25.0~+25.0" 257 "-25.0~+25.0" 258 "-25.0~+25.0" 259 "-25.0~+25.0" 260 "-25.0~+25.0" 261 "-25.0~+25.0" 262 "-25.0~+25.0" 263 "-25.0~+25.0" 264 "-25.0~+25.0" 265 "-25.0~+25.0" 266 "-25.0~+25.0" 267 "-25.0~+25.0" 268 "-25.0~+25.0" 269 "-25.0~+25.0" 270 "-25.0~+25.0" 271 "-25.0~+25.0" 272 "-25.0~+25.0" 273 "-25.0~+25.0" 274 "-25.0~+25.0" 275 "-25.0~+25.0" 276 "-25.0~+25.0" 277 "-25.0~+25.0" 278 "-25.0~+25.0" 279 "-25.0~+25.0" 280 "-25.0~+25.0" 281 "-25.0~+25.0" 282 "-25.0~+25.0" 283 "-25.0~+25.0" 284 "-25.0~+25.0" 285 "-25.0~+25.0" 286 "-25.0~+25.0" 287 "-25.0~+25.0" 288 "-25.0~+25.0" 289 "-25.0~+25.0" 290 "-25.0~+25.0" 291 "-25.0~+25.0" 292 "-25.0~+25.0" 293 "-25.0~+25.0" 294 "-25.0~+25.0" 295 "-25.0~+25.0" 296 "-25.0~+25.0" 297 "-25.0~+25.0" 298 "-25.0~+25.0" 299 "-25.0~+25.0" 300 "-25.0~+25.0" 301 "-25.0~+25.0" 302 "-25.0~+25.0" 303 "-25.0~+25.0" 304 "-25.0~+25.0" 305 "-25.0~+25.0" 306 "-25.0~+25.0" 307 "-25.0~+25.0" 308 "-25.0~+25.0" 309 "-25.0~+25.0" 310 "-25.0~+25.0" 311 "-25.0~+25.0" 312 "-25.0~+25.0" 313 "-25.0~+25.0" 314 "-25.0~+25.0" 315 "-25.0~+25.0" 316 "-25.0~+25.0" 317 "-25.0~+25.0" 318 "-25.0~+25.0" 319 "-25.0~+25.0" 320 "-25.0~+25.0" 321 "-25.0~+25.0" 322 "-25.0~+25.0" 323 "-25.0~+25.0" 324 "-25.0~+25.0" 325 "-25.0~+25.0" 326 "-25.0~+25.0" 327 "-25.0~+25.0" 328 "-25.0~+25.0" 329 "-25.0~+25.0" 330 "-25.0~+25.0" 331 "-25.0~+25.0" 332 "-25.0~+25.0" 333 "-25.0~+25.0" 334 "-25.0~+25.0" 335 "-25.0~+25.0" 336 "-25.0~+25.0" 337 "-25.0~+25.0" 338 "-25.0~+25.0" 339 "-25.0~+25.0" 340 "-25.0~+25.0" 341 "-25.0~+25.0" 342 "-25.0~+25.0" 343 "-25.0~+25.0" 344 "-25.0~+25.0" 345 "-25.0~+25.0" 346 "-25.0~+25.0" 347 "-25.0~+25.0" 348 "-25.0~+25.0" 349 "-25.0~+25.0" 350 "-25.0~+25.0" 351 "-25.0~+25.0" 352 "-25.0~+25.0" 353 "-25.0~+25.0" 354 "-25.0~+25.0" 355 "-25.0~+25.0" 356 "-25.0~+25.0" 357 "-25.0~+25.0" 358 "-25.0~+25.0" 359 "-25.0~+25.0" 360 "-25.0~+25.0" 361 "-25.0~+25.0" 362 "-25.0~+25.0" 363 "-25.0~+25.0" 364 "-25.0~+25.0" 365 "-25.0~+25.0" 366 "-25.0~+25.0" 367 "-25.0~+25.0" 368 "-25.0~+25.0" 369 "-25.0~+25.0" 370 "-25.0~+25.0" 371 "-25.0~+25.0" 372 "-25.0~+25.0" 373 "-25.0~+25.0" 374 "-25.0~+25.0" 375 "-25.0~+25.0" 376 "-25.0~+25.0" 377 "-25.0~+25.0" 378 "-25.0~+25.0" 379 "-25.0~+25.0" 380 "-25.0~+25.0" 381 "-25.0~+25.0" 382 "-25.0~+25.0" 383 "-25.0~+25.0" 384 "-25.0~+25.0" 385 "-25.0~+25.0" 386 "-25.0~+25.0" 387 "-25.0~+25.0" 388 "-25.0~+25.0" 389 "-25.0~+25.0" 390 "-25.0~+25.0" 391 "-25.0~+25.0" 392 "-25.0~+25.0" 393 "-25.0~+25.0" 394 "-25.0~+25.0" 395 "-25.0~+25.0" 396 "-25.0~+25.0" 397 "-25.0~+25.0" 398 "-25.0~+25.0" 399 "-25.0~+25.0" 400 "-25.0~+25.0" 401 "-25.0~+25.0" 402 "-25.0~+25.0" 403 "-25.0~+25.0" 404 "-25.0~+25.0" 405 "-25.0~+25.0" 406 "-25.0~+25.0" 407 "-25.0~+25.0" 408 "-25.0~+25.0" 409 "-25.0~+25.0" 410 "-25.0~+25.0" 411 "-25.0~+25.0" 412 "-25.0~+25.0" 413 "-25.0~+25.0" 414 "-25.0~+25.0" 415 "-25.0~+25.0" 416 "-25.0~+25.0" 417 "-25.0~+25.0" 418 "-25.0~+25.0" 419 "-25.0~+25.0" 420 "-25.0~+25.0" 421 "-25.0~+25.0" 422 "-25.0~+25.0" 423 "-25.0~+25.0" 424 "-25.0~+25.0" 425 "-25.0~+25.0" 426 "-25.0~+25.0" 427 "-25.0~+25.0" 428 "-25.0~+25.0" 429 "-25.0~+25.0" 430 "-25.0~+25.0" 431 "-25.0~+25.0" 432 "-25.0~+25.0" 433 "-25.0~+25.0" 434 "-25.0~+25.0" 435 "-25.0~+25.0" 436 "-25.0~+25.0" 437 "-25.0~+25.0" 438 "-25.0~+25.0" 439 "-25.0~+25.0" 440 "-25.0~+25.0" 441 "-25.0~+25.0" 442 "-25.0~+25.0" 443 "-25.0~+25.0" 444 "-25.0~+25.0" 445 "-25.0~+25.0" 446 "-25.0~+25.0" 447 "-25.0~+25.0" 448 "-25.0~+25.0" 449 "-25.0~+25.0" 450 "-25.0~+25.0" 451 "-25.0~+25.0" 452 "-25.0~+25.0" 453 "-25.0~+25.0" 454 "-25.0~+25.0" 455 "-25.0~+25.0" 456 "-25.0~+25.0" 457 "-25.0~+25.0" 458 "-25.0~+25.0" 459 "-25.0~+25.0" 460 "-25.0~+25.0" 461 "-25.0~+25.0" 462 "-25.0~+25.0" 463 "-25.0~+25.0" 464 "-25.0~+25.0" 465 "-25.0~+25.0" 466 "-25.0~+25.0" 467 "-25.0~+25.0" 468 "-25.0~+25.0" 469 "-25.0~+25.0" 470 "-25.0~+25.0" 471 "-25.0~+25.0" 472 "-25.0~+25.0" 473 "-25.0~+25.0" 474 "-25.0~+25.0" 475 "-25.0~+25.0" 476 "-25.0~+25.0" 477 "-25.0~+25.0" 478 "-25.0~+25.0" 479 "-25.0~+25.0" 480 "-25.0~+25.0" 481 "-25.0~+25.0" 482 "-25.0~+25.0" 483 "-25.0~+25.0" 484 "-25.0~+25.0" 485 "-25.0~+25.0" 486 "-25.0~+25.0" 487 "-25.0~+25.0" 488 "-25.0~+25.0" 489 "-25.0~+25.0" 490 "-25.0~+25.0" 491 "-25.0~+25.0" 492 "-25.0~+25.0" 493 "-25.0~+25.0" 494 "-25.0~+25.0" 495 "-25.0~+25.0" 496 "-25.0~+25.0" 497 "-25.0~+25.0" 498 "-25.0~+25.0" 499 "-25.0~+25.0" 500 "-25.0~+25.0" 501 "Not used" 502 "Not used" 503 "Not used" 504 "Not used" 505 "Not used" 506 "Not used" 507 "Not used" 508 "Not used" 509 "Not used" 510 "Default" 511 "Error indicator";
VAL_ 698 IFSref_VehLftAngl10Val 0 "-25.0~+25.0" 1 "-25.0~+25.0" 2 "-25.0~+25.0" 3 "-25.0~+25.0" 4 "-25.0~+25.0" 5 "-25.0~+25.0" 6 "-25.0~+25.0" 7 "-25.0~+25.0" 8 "-25.0~+25.0" 9 "-25.0~+25.0" 10 "-25.0~+25.0" 11 "-25.0~+25.0" 12 "-25.0~+25.0" 13 "-25.0~+25.0" 14 "-25.0~+25.0" 15 "-25.0~+25.0" 16 "-25.0~+25.0" 17 "-25.0~+25.0" 18 "-25.0~+25.0" 19 "-25.0~+25.0" 20 "-25.0~+25.0" 21 "-25.0~+25.0" 22 "-25.0~+25.0" 23 "-25.0~+25.0" 24 "-25.0~+25.0" 25 "-25.0~+25.0" 26 "-25.0~+25.0" 27 "-25.0~+25.0" 28 "-25.0~+25.0" 29 "-25.0~+25.0" 30 "-25.0~+25.0" 31 "-25.0~+25.0" 32 "-25.0~+25.0" 33 "-25.0~+25.0" 34 "-25.0~+25.0" 35 "-25.0~+25.0" 36 "-25.0~+25.0" 37 "-25.0~+25.0" 38 "-25.0~+25.0" 39 "-25.0~+25.0" 40 "-25.0~+25.0" 41 "-25.0~+25.0" 42 "-25.0~+25.0" 43 "-25.0~+25.0" 44 "-25.0~+25.0" 45 "-25.0~+25.0" 46 "-25.0~+25.0" 47 "-25.0~+25.0" 48 "-25.0~+25.0" 49 "-25.0~+25.0" 50 "-25.0~+25.0" 51 "-25.0~+25.0" 52 "-25.0~+25.0" 53 "-25.0~+25.0" 54 "-25.0~+25.0" 55 "-25.0~+25.0" 56 "-25.0~+25.0" 57 "-25.0~+25.0" 58 "-25.0~+25.0" 59 "-25.0~+25.0" 60 "-25.0~+25.0" 61 "-25.0~+25.0" 62 "-25.0~+25.0" 63 "-25.0~+25.0" 64 "-25.0~+25.0" 65 "-25.0~+25.0" 66 "-25.0~+25.0" 67 "-25.0~+25.0" 68 "-25.0~+25.0" 69 "-25.0~+25.0" 70 "-25.0~+25.0" 71 "-25.0~+25.0" 72 "-25.0~+25.0" 73 "-25.0~+25.0" 74 "-25.0~+25.0" 75 "-25.0~+25.0" 76 "-25.0~+25.0" 77 "-25.0~+25.0" 78 "-25.0~+25.0" 79 "-25.0~+25.0" 80 "-25.0~+25.0" 81 "-25.0~+25.0" 82 "-25.0~+25.0" 83 "-25.0~+25.0" 84 "-25.0~+25.0" 85 "-25.0~+25.0" 86 "-25.0~+25.0" 87 "-25.0~+25.0" 88 "-25.0~+25.0" 89 "-25.0~+25.0" 90 "-25.0~+25.0" 91 "-25.0~+25.0" 92 "-25.0~+25.0" 93 "-25.0~+25.0" 94 "-25.0~+25.0" 95 "-25.0~+25.0" 96 "-25.0~+25.0" 97 "-25.0~+25.0" 98 "-25.0~+25.0" 99 "-25.0~+25.0" 100 "-25.0~+25.0" 101 "-25.0~+25.0" 102 "-25.0~+25.0" 103 "-25.0~+25.0" 104 "-25.0~+25.0" 105 "-25.0~+25.0" 106 "-25.0~+25.0" 107 "-25.0~+25.0" 108 "-25.0~+25.0" 109 "-25.0~+25.0" 110 "-25.0~+25.0" 111 "-25.0~+25.0" 112 "-25.0~+25.0" 113 "-25.0~+25.0" 114 "-25.0~+25.0" 115 "-25.0~+25.0" 116 "-25.0~+25.0" 117 "-25.0~+25.0" 118 "-25.0~+25.0" 119 "-25.0~+25.0" 120 "-25.0~+25.0" 121 "-25.0~+25.0" 122 "-25.0~+25.0" 123 "-25.0~+25.0" 124 "-25.0~+25.0" 125 "-25.0~+25.0" 126 "-25.0~+25.0" 127 "-25.0~+25.0" 128 "-25.0~+25.0" 129 "-25.0~+25.0" 130 "-25.0~+25.0" 131 "-25.0~+25.0" 132 "-25.0~+25.0" 133 "-25.0~+25.0" 134 "-25.0~+25.0" 135 "-25.0~+25.0" 136 "-25.0~+25.0" 137 "-25.0~+25.0" 138 "-25.0~+25.0" 139 "-25.0~+25.0" 140 "-25.0~+25.0" 141 "-25.0~+25.0" 142 "-25.0~+25.0" 143 "-25.0~+25.0" 144 "-25.0~+25.0" 145 "-25.0~+25.0" 146 "-25.0~+25.0" 147 "-25.0~+25.0" 148 "-25.0~+25.0" 149 "-25.0~+25.0" 150 "-25.0~+25.0" 151 "-25.0~+25.0" 152 "-25.0~+25.0" 153 "-25.0~+25.0" 154 "-25.0~+25.0" 155 "-25.0~+25.0" 156 "-25.0~+25.0" 157 "-25.0~+25.0" 158 "-25.0~+25.0" 159 "-25.0~+25.0" 160 "-25.0~+25.0" 161 "-25.0~+25.0" 162 "-25.0~+25.0" 163 "-25.0~+25.0" 164 "-25.0~+25.0" 165 "-25.0~+25.0" 166 "-25.0~+25.0" 167 "-25.0~+25.0" 168 "-25.0~+25.0" 169 "-25.0~+25.0" 170 "-25.0~+25.0" 171 "-25.0~+25.0" 172 "-25.0~+25.0" 173 "-25.0~+25.0" 174 "-25.0~+25.0" 175 "-25.0~+25.0" 176 "-25.0~+25.0" 177 "-25.0~+25.0" 178 "-25.0~+25.0" 179 "-25.0~+25.0" 180 "-25.0~+25.0" 181 "-25.0~+25.0" 182 "-25.0~+25.0" 183 "-25.0~+25.0" 184 "-25.0~+25.0" 185 "-25.0~+25.0" 186 "-25.0~+25.0" 187 "-25.0~+25.0" 188 "-25.0~+25.0" 189 "-25.0~+25.0" 190 "-25.0~+25.0" 191 "-25.0~+25.0" 192 "-25.0~+25.0" 193 "-25.0~+25.0" 194 "-25.0~+25.0" 195 "-25.0~+25.0" 196 "-25.0~+25.0" 197 "-25.0~+25.0" 198 "-25.0~+25.0" 199 "-25.0~+25.0" 200 "-25.0~+25.0" 201 "-25.0~+25.0" 202 "-25.0~+25.0" 203 "-25.0~+25.0" 204 "-25.0~+25.0" 205 "-25.0~+25.0" 206 "-25.0~+25.0" 207 "-25.0~+25.0" 208 "-25.0~+25.0" 209 "-25.0~+25.0" 210 "-25.0~+25.0" 211 "-25.0~+25.0" 212 "-25.0~+25.0" 213 "-25.0~+25.0" 214 "-25.0~+25.0" 215 "-25.0~+25.0" 216 "-25.0~+25.0" 217 "-25.0~+25.0" 218 "-25.0~+25.0" 219 "-25.0~+25.0" 220 "-25.0~+25.0" 221 "-25.0~+25.0" 222 "-25.0~+25.0" 223 "-25.0~+25.0" 224 "-25.0~+25.0" 225 "-25.0~+25.0" 226 "-25.0~+25.0" 227 "-25.0~+25.0" 228 "-25.0~+25.0" 229 "-25.0~+25.0" 230 "-25.0~+25.0" 231 "-25.0~+25.0" 232 "-25.0~+25.0" 233 "-25.0~+25.0" 234 "-25.0~+25.0" 235 "-25.0~+25.0" 236 "-25.0~+25.0" 237 "-25.0~+25.0" 238 "-25.0~+25.0" 239 "-25.0~+25.0" 240 "-25.0~+25.0" 241 "-25.0~+25.0" 242 "-25.0~+25.0" 243 "-25.0~+25.0" 244 "-25.0~+25.0" 245 "-25.0~+25.0" 246 "-25.0~+25.0" 247 "-25.0~+25.0" 248 "-25.0~+25.0" 249 "-25.0~+25.0" 250 "-25.0~+25.0" 251 "-25.0~+25.0" 252 "-25.0~+25.0" 253 "-25.0~+25.0" 254 "-25.0~+25.0" 255 "-25.0~+25.0" 256 "-25.0~+25.0" 257 "-25.0~+25.0" 258 "-25.0~+25.0" 259 "-25.0~+25.0" 260 "-25.0~+25.0" 261 "-25.0~+25.0" 262 "-25.0~+25.0" 263 "-25.0~+25.0" 264 "-25.0~+25.0" 265 "-25.0~+25.0" 266 "-25.0~+25.0" 267 "-25.0~+25.0" 268 "-25.0~+25.0" 269 "-25.0~+25.0" 270 "-25.0~+25.0" 271 "-25.0~+25.0" 272 "-25.0~+25.0" 273 "-25.0~+25.0" 274 "-25.0~+25.0" 275 "-25.0~+25.0" 276 "-25.0~+25.0" 277 "-25.0~+25.0" 278 "-25.0~+25.0" 279 "-25.0~+25.0" 280 "-25.0~+25.0" 281 "-25.0~+25.0" 282 "-25.0~+25.0" 283 "-25.0~+25.0" 284 "-25.0~+25.0" 285 "-25.0~+25.0" 286 "-25.0~+25.0" 287 "-25.0~+25.0" 288 "-25.0~+25.0" 289 "-25.0~+25.0" 290 "-25.0~+25.0" 291 "-25.0~+25.0" 292 "-25.0~+25.0" 293 "-25.0~+25.0" 294 "-25.0~+25.0" 295 "-25.0~+25.0" 296 "-25.0~+25.0" 297 "-25.0~+25.0" 298 "-25.0~+25.0" 299 "-25.0~+25.0" 300 "-25.0~+25.0" 301 "-25.0~+25.0" 302 "-25.0~+25.0" 303 "-25.0~+25.0" 304 "-25.0~+25.0" 305 "-25.0~+25.0" 306 "-25.0~+25.0" 307 "-25.0~+25.0" 308 "-25.0~+25.0" 309 "-25.0~+25.0" 310 "-25.0~+25.0" 311 "-25.0~+25.0" 312 "-25.0~+25.0" 313 "-25.0~+25.0" 314 "-25.0~+25.0" 315 "-25.0~+25.0" 316 "-25.0~+25.0" 317 "-25.0~+25.0" 318 "-25.0~+25.0" 319 "-25.0~+25.0" 320 "-25.0~+25.0" 321 "-25.0~+25.0" 322 "-25.0~+25.0" 323 "-25.0~+25.0" 324 "-25.0~+25.0" 325 "-25.0~+25.0" 326 "-25.0~+25.0" 327 "-25.0~+25.0" 328 "-25.0~+25.0" 329 "-25.0~+25.0" 330 "-25.0~+25.0" 331 "-25.0~+25.0" 332 "-25.0~+25.0" 333 "-25.0~+25.0" 334 "-25.0~+25.0" 335 "-25.0~+25.0" 336 "-25.0~+25.0" 337 "-25.0~+25.0" 338 "-25.0~+25.0" 339 "-25.0~+25.0" 340 "-25.0~+25.0" 341 "-25.0~+25.0" 342 "-25.0~+25.0" 343 "-25.0~+25.0" 344 "-25.0~+25.0" 345 "-25.0~+25.0" 346 "-25.0~+25.0" 347 "-25.0~+25.0" 348 "-25.0~+25.0" 349 "-25.0~+25.0" 350 "-25.0~+25.0" 351 "-25.0~+25.0" 352 "-25.0~+25.0" 353 "-25.0~+25.0" 354 "-25.0~+25.0" 355 "-25.0~+25.0" 356 "-25.0~+25.0" 357 "-25.0~+25.0" 358 "-25.0~+25.0" 359 "-25.0~+25.0" 360 "-25.0~+25.0" 361 "-25.0~+25.0" 362 "-25.0~+25.0" 363 "-25.0~+25.0" 364 "-25.0~+25.0" 365 "-25.0~+25.0" 366 "-25.0~+25.0" 367 "-25.0~+25.0" 368 "-25.0~+25.0" 369 "-25.0~+25.0" 370 "-25.0~+25.0" 371 "-25.0~+25.0" 372 "-25.0~+25.0" 373 "-25.0~+25.0" 374 "-25.0~+25.0" 375 "-25.0~+25.0" 376 "-25.0~+25.0" 377 "-25.0~+25.0" 378 "-25.0~+25.0" 379 "-25.0~+25.0" 380 "-25.0~+25.0" 381 "-25.0~+25.0" 382 "-25.0~+25.0" 383 "-25.0~+25.0" 384 "-25.0~+25.0" 385 "-25.0~+25.0" 386 "-25.0~+25.0" 387 "-25.0~+25.0" 388 "-25.0~+25.0" 389 "-25.0~+25.0" 390 "-25.0~+25.0" 391 "-25.0~+25.0" 392 "-25.0~+25.0" 393 "-25.0~+25.0" 394 "-25.0~+25.0" 395 "-25.0~+25.0" 396 "-25.0~+25.0" 397 "-25.0~+25.0" 398 "-25.0~+25.0" 399 "-25.0~+25.0" 400 "-25.0~+25.0" 401 "-25.0~+25.0" 402 "-25.0~+25.0" 403 "-25.0~+25.0" 404 "-25.0~+25.0" 405 "-25.0~+25.0" 406 "-25.0~+25.0" 407 "-25.0~+25.0" 408 "-25.0~+25.0" 409 "-25.0~+25.0" 410 "-25.0~+25.0" 411 "-25.0~+25.0" 412 "-25.0~+25.0" 413 "-25.0~+25.0" 414 "-25.0~+25.0" 415 "-25.0~+25.0" 416 "-25.0~+25.0" 417 "-25.0~+25.0" 418 "-25.0~+25.0" 419 "-25.0~+25.0" 420 "-25.0~+25.0" 421 "-25.0~+25.0" 422 "-25.0~+25.0" 423 "-25.0~+25.0" 424 "-25.0~+25.0" 425 "-25.0~+25.0" 426 "-25.0~+25.0" 427 "-25.0~+25.0" 428 "-25.0~+25.0" 429 "-25.0~+25.0" 430 "-25.0~+25.0" 431 "-25.0~+25.0" 432 "-25.0~+25.0" 433 "-25.0~+25.0" 434 "-25.0~+25.0" 435 "-25.0~+25.0" 436 "-25.0~+25.0" 437 "-25.0~+25.0" 438 "-25.0~+25.0" 439 "-25.0~+25.0" 440 "-25.0~+25.0" 441 "-25.0~+25.0" 442 "-25.0~+25.0" 443 "-25.0~+25.0" 444 "-25.0~+25.0" 445 "-25.0~+25.0" 446 "-25.0~+25.0" 447 "-25.0~+25.0" 448 "-25.0~+25.0" 449 "-25.0~+25.0" 450 "-25.0~+25.0" 451 "-25.0~+25.0" 452 "-25.0~+25.0" 453 "-25.0~+25.0" 454 "-25.0~+25.0" 455 "-25.0~+25.0" 456 "-25.0~+25.0" 457 "-25.0~+25.0" 458 "-25.0~+25.0" 459 "-25.0~+25.0" 460 "-25.0~+25.0" 461 "-25.0~+25.0" 462 "-25.0~+25.0" 463 "-25.0~+25.0" 464 "-25.0~+25.0" 465 "-25.0~+25.0" 466 "-25.0~+25.0" 467 "-25.0~+25.0" 468 "-25.0~+25.0" 469 "-25.0~+25.0" 470 "-25.0~+25.0" 471 "-25.0~+25.0" 472 "-25.0~+25.0" 473 "-25.0~+25.0" 474 "-25.0~+25.0" 475 "-25.0~+25.0" 476 "-25.0~+25.0" 477 "-25.0~+25.0" 478 "-25.0~+25.0" 479 "-25.0~+25.0" 480 "-25.0~+25.0" 481 "-25.0~+25.0" 482 "-25.0~+25.0" 483 "-25.0~+25.0" 484 "-25.0~+25.0" 485 "-25.0~+25.0" 486 "-25.0~+25.0" 487 "-25.0~+25.0" 488 "-25.0~+25.0" 489 "-25.0~+25.0" 490 "-25.0~+25.0" 491 "-25.0~+25.0" 492 "-25.0~+25.0" 493 "-25.0~+25.0" 494 "-25.0~+25.0" 495 "-25.0~+25.0" 496 "-25.0~+25.0" 497 "-25.0~+25.0" 498 "-25.0~+25.0" 499 "-25.0~+25.0" 500 "-25.0~+25.0" 501 "Not used" 502 "Not used" 503 "Not used" 504 "Not used" 505 "Not used" 506 "Not used" 507 "Not used" 508 "Not used" 509 "Not used" 510 "Default" 511 "Error indicator";
VAL_ 698 IFSref_VehRtAngl10Val 0 "-25.0~+25.0" 1 "-25.0~+25.0" 2 "-25.0~+25.0" 3 "-25.0~+25.0" 4 "-25.0~+25.0" 5 "-25.0~+25.0" 6 "-25.0~+25.0" 7 "-25.0~+25.0" 8 "-25.0~+25.0" 9 "-25.0~+25.0" 10 "-25.0~+25.0" 11 "-25.0~+25.0" 12 "-25.0~+25.0" 13 "-25.0~+25.0" 14 "-25.0~+25.0" 15 "-25.0~+25.0" 16 "-25.0~+25.0" 17 "-25.0~+25.0" 18 "-25.0~+25.0" 19 "-25.0~+25.0" 20 "-25.0~+25.0" 21 "-25.0~+25.0" 22 "-25.0~+25.0" 23 "-25.0~+25.0" 24 "-25.0~+25.0" 25 "-25.0~+25.0" 26 "-25.0~+25.0" 27 "-25.0~+25.0" 28 "-25.0~+25.0" 29 "-25.0~+25.0" 30 "-25.0~+25.0" 31 "-25.0~+25.0" 32 "-25.0~+25.0" 33 "-25.0~+25.0" 34 "-25.0~+25.0" 35 "-25.0~+25.0" 36 "-25.0~+25.0" 37 "-25.0~+25.0" 38 "-25.0~+25.0" 39 "-25.0~+25.0" 40 "-25.0~+25.0" 41 "-25.0~+25.0" 42 "-25.0~+25.0" 43 "-25.0~+25.0" 44 "-25.0~+25.0" 45 "-25.0~+25.0" 46 "-25.0~+25.0" 47 "-25.0~+25.0" 48 "-25.0~+25.0" 49 "-25.0~+25.0" 50 "-25.0~+25.0" 51 "-25.0~+25.0" 52 "-25.0~+25.0" 53 "-25.0~+25.0" 54 "-25.0~+25.0" 55 "-25.0~+25.0" 56 "-25.0~+25.0" 57 "-25.0~+25.0" 58 "-25.0~+25.0" 59 "-25.0~+25.0" 60 "-25.0~+25.0" 61 "-25.0~+25.0" 62 "-25.0~+25.0" 63 "-25.0~+25.0" 64 "-25.0~+25.0" 65 "-25.0~+25.0" 66 "-25.0~+25.0" 67 "-25.0~+25.0" 68 "-25.0~+25.0" 69 "-25.0~+25.0" 70 "-25.0~+25.0" 71 "-25.0~+25.0" 72 "-25.0~+25.0" 73 "-25.0~+25.0" 74 "-25.0~+25.0" 75 "-25.0~+25.0" 76 "-25.0~+25.0" 77 "-25.0~+25.0" 78 "-25.0~+25.0" 79 "-25.0~+25.0" 80 "-25.0~+25.0" 81 "-25.0~+25.0" 82 "-25.0~+25.0" 83 "-25.0~+25.0" 84 "-25.0~+25.0" 85 "-25.0~+25.0" 86 "-25.0~+25.0" 87 "-25.0~+25.0" 88 "-25.0~+25.0" 89 "-25.0~+25.0" 90 "-25.0~+25.0" 91 "-25.0~+25.0" 92 "-25.0~+25.0" 93 "-25.0~+25.0" 94 "-25.0~+25.0" 95 "-25.0~+25.0" 96 "-25.0~+25.0" 97 "-25.0~+25.0" 98 "-25.0~+25.0" 99 "-25.0~+25.0" 100 "-25.0~+25.0" 101 "-25.0~+25.0" 102 "-25.0~+25.0" 103 "-25.0~+25.0" 104 "-25.0~+25.0" 105 "-25.0~+25.0" 106 "-25.0~+25.0" 107 "-25.0~+25.0" 108 "-25.0~+25.0" 109 "-25.0~+25.0" 110 "-25.0~+25.0" 111 "-25.0~+25.0" 112 "-25.0~+25.0" 113 "-25.0~+25.0" 114 "-25.0~+25.0" 115 "-25.0~+25.0" 116 "-25.0~+25.0" 117 "-25.0~+25.0" 118 "-25.0~+25.0" 119 "-25.0~+25.0" 120 "-25.0~+25.0" 121 "-25.0~+25.0" 122 "-25.0~+25.0" 123 "-25.0~+25.0" 124 "-25.0~+25.0" 125 "-25.0~+25.0" 126 "-25.0~+25.0" 127 "-25.0~+25.0" 128 "-25.0~+25.0" 129 "-25.0~+25.0" 130 "-25.0~+25.0" 131 "-25.0~+25.0" 132 "-25.0~+25.0" 133 "-25.0~+25.0" 134 "-25.0~+25.0" 135 "-25.0~+25.0" 136 "-25.0~+25.0" 137 "-25.0~+25.0" 138 "-25.0~+25.0" 139 "-25.0~+25.0" 140 "-25.0~+25.0" 141 "-25.0~+25.0" 142 "-25.0~+25.0" 143 "-25.0~+25.0" 144 "-25.0~+25.0" 145 "-25.0~+25.0" 146 "-25.0~+25.0" 147 "-25.0~+25.0" 148 "-25.0~+25.0" 149 "-25.0~+25.0" 150 "-25.0~+25.0" 151 "-25.0~+25.0" 152 "-25.0~+25.0" 153 "-25.0~+25.0" 154 "-25.0~+25.0" 155 "-25.0~+25.0" 156 "-25.0~+25.0" 157 "-25.0~+25.0" 158 "-25.0~+25.0" 159 "-25.0~+25.0" 160 "-25.0~+25.0" 161 "-25.0~+25.0" 162 "-25.0~+25.0" 163 "-25.0~+25.0" 164 "-25.0~+25.0" 165 "-25.0~+25.0" 166 "-25.0~+25.0" 167 "-25.0~+25.0" 168 "-25.0~+25.0" 169 "-25.0~+25.0" 170 "-25.0~+25.0" 171 "-25.0~+25.0" 172 "-25.0~+25.0" 173 "-25.0~+25.0" 174 "-25.0~+25.0" 175 "-25.0~+25.0" 176 "-25.0~+25.0" 177 "-25.0~+25.0" 178 "-25.0~+25.0" 179 "-25.0~+25.0" 180 "-25.0~+25.0" 181 "-25.0~+25.0" 182 "-25.0~+25.0" 183 "-25.0~+25.0" 184 "-25.0~+25.0" 185 "-25.0~+25.0" 186 "-25.0~+25.0" 187 "-25.0~+25.0" 188 "-25.0~+25.0" 189 "-25.0~+25.0" 190 "-25.0~+25.0" 191 "-25.0~+25.0" 192 "-25.0~+25.0" 193 "-25.0~+25.0" 194 "-25.0~+25.0" 195 "-25.0~+25.0" 196 "-25.0~+25.0" 197 "-25.0~+25.0" 198 "-25.0~+25.0" 199 "-25.0~+25.0" 200 "-25.0~+25.0" 201 "-25.0~+25.0" 202 "-25.0~+25.0" 203 "-25.0~+25.0" 204 "-25.0~+25.0" 205 "-25.0~+25.0" 206 "-25.0~+25.0" 207 "-25.0~+25.0" 208 "-25.0~+25.0" 209 "-25.0~+25.0" 210 "-25.0~+25.0" 211 "-25.0~+25.0" 212 "-25.0~+25.0" 213 "-25.0~+25.0" 214 "-25.0~+25.0" 215 "-25.0~+25.0" 216 "-25.0~+25.0" 217 "-25.0~+25.0" 218 "-25.0~+25.0" 219 "-25.0~+25.0" 220 "-25.0~+25.0" 221 "-25.0~+25.0" 222 "-25.0~+25.0" 223 "-25.0~+25.0" 224 "-25.0~+25.0" 225 "-25.0~+25.0" 226 "-25.0~+25.0" 227 "-25.0~+25.0" 228 "-25.0~+25.0" 229 "-25.0~+25.0" 230 "-25.0~+25.0" 231 "-25.0~+25.0" 232 "-25.0~+25.0" 233 "-25.0~+25.0" 234 "-25.0~+25.0" 235 "-25.0~+25.0" 236 "-25.0~+25.0" 237 "-25.0~+25.0" 238 "-25.0~+25.0" 239 "-25.0~+25.0" 240 "-25.0~+25.0" 241 "-25.0~+25.0" 242 "-25.0~+25.0" 243 "-25.0~+25.0" 244 "-25.0~+25.0" 245 "-25.0~+25.0" 246 "-25.0~+25.0" 247 "-25.0~+25.0" 248 "-25.0~+25.0" 249 "-25.0~+25.0" 250 "-25.0~+25.0" 251 "-25.0~+25.0" 252 "-25.0~+25.0" 253 "-25.0~+25.0" 254 "-25.0~+25.0" 255 "-25.0~+25.0" 256 "-25.0~+25.0" 257 "-25.0~+25.0" 258 "-25.0~+25.0" 259 "-25.0~+25.0" 260 "-25.0~+25.0" 261 "-25.0~+25.0" 262 "-25.0~+25.0" 263 "-25.0~+25.0" 264 "-25.0~+25.0" 265 "-25.0~+25.0" 266 "-25.0~+25.0" 267 "-25.0~+25.0" 268 "-25.0~+25.0" 269 "-25.0~+25.0" 270 "-25.0~+25.0" 271 "-25.0~+25.0" 272 "-25.0~+25.0" 273 "-25.0~+25.0" 274 "-25.0~+25.0" 275 "-25.0~+25.0" 276 "-25.0~+25.0" 277 "-25.0~+25.0" 278 "-25.0~+25.0" 279 "-25.0~+25.0" 280 "-25.0~+25.0" 281 "-25.0~+25.0" 282 "-25.0~+25.0" 283 "-25.0~+25.0" 284 "-25.0~+25.0" 285 "-25.0~+25.0" 286 "-25.0~+25.0" 287 "-25.0~+25.0" 288 "-25.0~+25.0" 289 "-25.0~+25.0" 290 "-25.0~+25.0" 291 "-25.0~+25.0" 292 "-25.0~+25.0" 293 "-25.0~+25.0" 294 "-25.0~+25.0" 295 "-25.0~+25.0" 296 "-25.0~+25.0" 297 "-25.0~+25.0" 298 "-25.0~+25.0" 299 "-25.0~+25.0" 300 "-25.0~+25.0" 301 "-25.0~+25.0" 302 "-25.0~+25.0" 303 "-25.0~+25.0" 304 "-25.0~+25.0" 305 "-25.0~+25.0" 306 "-25.0~+25.0" 307 "-25.0~+25.0" 308 "-25.0~+25.0" 309 "-25.0~+25.0" 310 "-25.0~+25.0" 311 "-25.0~+25.0" 312 "-25.0~+25.0" 313 "-25.0~+25.0" 314 "-25.0~+25.0" 315 "-25.0~+25.0" 316 "-25.0~+25.0" 317 "-25.0~+25.0" 318 "-25.0~+25.0" 319 "-25.0~+25.0" 320 "-25.0~+25.0" 321 "-25.0~+25.0" 322 "-25.0~+25.0" 323 "-25.0~+25.0" 324 "-25.0~+25.0" 325 "-25.0~+25.0" 326 "-25.0~+25.0" 327 "-25.0~+25.0" 328 "-25.0~+25.0" 329 "-25.0~+25.0" 330 "-25.0~+25.0" 331 "-25.0~+25.0" 332 "-25.0~+25.0" 333 "-25.0~+25.0" 334 "-25.0~+25.0" 335 "-25.0~+25.0" 336 "-25.0~+25.0" 337 "-25.0~+25.0" 338 "-25.0~+25.0" 339 "-25.0~+25.0" 340 "-25.0~+25.0" 341 "-25.0~+25.0" 342 "-25.0~+25.0" 343 "-25.0~+25.0" 344 "-25.0~+25.0" 345 "-25.0~+25.0" 346 "-25.0~+25.0" 347 "-25.0~+25.0" 348 "-25.0~+25.0" 349 "-25.0~+25.0" 350 "-25.0~+25.0" 351 "-25.0~+25.0" 352 "-25.0~+25.0" 353 "-25.0~+25.0" 354 "-25.0~+25.0" 355 "-25.0~+25.0" 356 "-25.0~+25.0" 357 "-25.0~+25.0" 358 "-25.0~+25.0" 359 "-25.0~+25.0" 360 "-25.0~+25.0" 361 "-25.0~+25.0" 362 "-25.0~+25.0" 363 "-25.0~+25.0" 364 "-25.0~+25.0" 365 "-25.0~+25.0" 366 "-25.0~+25.0" 367 "-25.0~+25.0" 368 "-25.0~+25.0" 369 "-25.0~+25.0" 370 "-25.0~+25.0" 371 "-25.0~+25.0" 372 "-25.0~+25.0" 373 "-25.0~+25.0" 374 "-25.0~+25.0" 375 "-25.0~+25.0" 376 "-25.0~+25.0" 377 "-25.0~+25.0" 378 "-25.0~+25.0" 379 "-25.0~+25.0" 380 "-25.0~+25.0" 381 "-25.0~+25.0" 382 "-25.0~+25.0" 383 "-25.0~+25.0" 384 "-25.0~+25.0" 385 "-25.0~+25.0" 386 "-25.0~+25.0" 387 "-25.0~+25.0" 388 "-25.0~+25.0" 389 "-25.0~+25.0" 390 "-25.0~+25.0" 391 "-25.0~+25.0" 392 "-25.0~+25.0" 393 "-25.0~+25.0" 394 "-25.0~+25.0" 395 "-25.0~+25.0" 396 "-25.0~+25.0" 397 "-25.0~+25.0" 398 "-25.0~+25.0" 399 "-25.0~+25.0" 400 "-25.0~+25.0" 401 "-25.0~+25.0" 402 "-25.0~+25.0" 403 "-25.0~+25.0" 404 "-25.0~+25.0" 405 "-25.0~+25.0" 406 "-25.0~+25.0" 407 "-25.0~+25.0" 408 "-25.0~+25.0" 409 "-25.0~+25.0" 410 "-25.0~+25.0" 411 "-25.0~+25.0" 412 "-25.0~+25.0" 413 "-25.0~+25.0" 414 "-25.0~+25.0" 415 "-25.0~+25.0" 416 "-25.0~+25.0" 417 "-25.0~+25.0" 418 "-25.0~+25.0" 419 "-25.0~+25.0" 420 "-25.0~+25.0" 421 "-25.0~+25.0" 422 "-25.0~+25.0" 423 "-25.0~+25.0" 424 "-25.0~+25.0" 425 "-25.0~+25.0" 426 "-25.0~+25.0" 427 "-25.0~+25.0" 428 "-25.0~+25.0" 429 "-25.0~+25.0" 430 "-25.0~+25.0" 431 "-25.0~+25.0" 432 "-25.0~+25.0" 433 "-25.0~+25.0" 434 "-25.0~+25.0" 435 "-25.0~+25.0" 436 "-25.0~+25.0" 437 "-25.0~+25.0" 438 "-25.0~+25.0" 439 "-25.0~+25.0" 440 "-25.0~+25.0" 441 "-25.0~+25.0" 442 "-25.0~+25.0" 443 "-25.0~+25.0" 444 "-25.0~+25.0" 445 "-25.0~+25.0" 446 "-25.0~+25.0" 447 "-25.0~+25.0" 448 "-25.0~+25.0" 449 "-25.0~+25.0" 450 "-25.0~+25.0" 451 "-25.0~+25.0" 452 "-25.0~+25.0" 453 "-25.0~+25.0" 454 "-25.0~+25.0" 455 "-25.0~+25.0" 456 "-25.0~+25.0" 457 "-25.0~+25.0" 458 "-25.0~+25.0" 459 "-25.0~+25.0" 460 "-25.0~+25.0" 461 "-25.0~+25.0" 462 "-25.0~+25.0" 463 "-25.0~+25.0" 464 "-25.0~+25.0" 465 "-25.0~+25.0" 466 "-25.0~+25.0" 467 "-25.0~+25.0" 468 "-25.0~+25.0" 469 "-25.0~+25.0" 470 "-25.0~+25.0" 471 "-25.0~+25.0" 472 "-25.0~+25.0" 473 "-25.0~+25.0" 474 "-25.0~+25.0" 475 "-25.0~+25.0" 476 "-25.0~+25.0" 477 "-25.0~+25.0" 478 "-25.0~+25.0" 479 "-25.0~+25.0" 480 "-25.0~+25.0" 481 "-25.0~+25.0" 482 "-25.0~+25.0" 483 "-25.0~+25.0" 484 "-25.0~+25.0" 485 "-25.0~+25.0" 486 "-25.0~+25.0" 487 "-25.0~+25.0" 488 "-25.0~+25.0" 489 "-25.0~+25.0" 490 "-25.0~+25.0" 491 "-25.0~+25.0" 492 "-25.0~+25.0" 493 "-25.0~+25.0" 494 "-25.0~+25.0" 495 "-25.0~+25.0" 496 "-25.0~+25.0" 497 "-25.0~+25.0" 498 "-25.0~+25.0" 499 "-25.0~+25.0" 500 "-25.0~+25.0" 501 "Not used" 502 "Not used" 503 "Not used" 504 "Not used" 505 "Not used" 506 "Not used" 507 "Not used" 508 "Not used" 509 "Not used" 510 "Default" 511 "Error indicator";
VAL_ 698 IFSref_VehDst2Val 0 "No Value" 1 "1~10m" 2 "11~20m" 3 "21~30m" 4 "31~40m" 5 "41~50m" 6 "51~60m" 7 "61~70m" 8 "71~80m" 9 "81~90m" 10 "91~100m" 11 "101~200m" 12 "201~300m" 13 "301~400m" 14 "401m~" 15 "Error indicator";
VAL_ 698 IFSref_VehDst3Val 0 "No Value" 1 "1~10m" 2 "11~20m" 3 "21~30m" 4 "31~40m" 5 "41~50m" 6 "51~60m" 7 "61~70m" 8 "71~80m" 9 "81~90m" 10 "91~100m" 11 "101~200m" 12 "201~300m" 13 "301~400m" 14 "401m~" 15 "Error indicator";
VAL_ 698 IFSref_VehDst4Val 0 "No Value" 1 "1~10m" 2 "11~20m" 3 "21~30m" 4 "31~40m" 5 "41~50m" 6 "51~60m" 7 "61~70m" 8 "71~80m" 9 "81~90m" 10 "91~100m" 11 "101~200m" 12 "201~300m" 13 "301~400m" 14 "401m~" 15 "Error indicator";
VAL_ 698 IFSref_VehDst5Val 0 "No Value" 1 "1~10m" 2 "11~20m" 3 "21~30m" 4 "31~40m" 5 "41~50m" 6 "51~60m" 7 "61~70m" 8 "71~80m" 9 "81~90m" 10 "91~100m" 11 "101~200m" 12 "201~300m" 13 "301~400m" 14 "401m~" 15 "Error indicator";
VAL_ 698 IFSref_VehDst6Val 0 "No Value" 1 "1~10m" 2 "11~20m" 3 "21~30m" 4 "31~40m" 5 "41~50m" 6 "51~60m" 7 "61~70m" 8 "71~80m" 9 "81~90m" 10 "91~100m" 11 "101~200m" 12 "201~300m" 13 "301~400m" 14 "401m~" 15 "Error indicator";
VAL_ 698 IFSref_VehDst7Val 0 "No Value" 1 "1~10m" 2 "11~20m" 3 "21~30m" 4 "31~40m" 5 "41~50m" 6 "51~60m" 7 "61~70m" 8 "71~80m" 9 "81~90m" 10 "91~100m" 11 "101~200m" 12 "201~300m" 13 "301~400m" 14 "401m~" 15 "Error indicator";
VAL_ 698 IFSref_VehDst8Val 0 "No Value" 1 "1~10m" 2 "11~20m" 3 "21~30m" 4 "31~40m" 5 "41~50m" 6 "51~60m" 7 "61~70m" 8 "71~80m" 9 "81~90m" 10 "91~100m" 11 "101~200m" 12 "201~300m" 13 "301~400m" 14 "401m~" 15 "Error indicator";
VAL_ 698 IFSref_VehDst9Val 0 "No Value" 1 "1~10m" 2 "11~20m" 3 "21~30m" 4 "31~40m" 5 "41~50m" 6 "51~60m" 7 "61~70m" 8 "71~80m" 9 "81~90m" 10 "91~100m" 11 "101~200m" 12 "201~300m" 13 "301~400m" 14 "401m~" 15 "Error indicator";
VAL_ 698 IFSref_VehDst10Val 0 "No Value" 1 "1~10m" 2 "11~20m" 3 "21~30m" 4 "31~40m" 5 "41~50m" 6 "51~60m" 7 "61~70m" 8 "71~80m" 9 "81~90m" 10 "91~100m" 11 "101~200m" 12 "201~300m" 13 "301~400m" 14 "401m~" 15 "Error indicator";
VAL_ 736 MSLA_STATUS 0 "disabled" 1 "active" 2 "paused";
VAL_ 866 LEFT_LANE_LINE 0 "Not Detected" 1 "Low Confidence" 2 "Medium Confidence" 3 "High Confidence";
VAL_ 866 RIGHT_LANE_LINE 0 "Not Detected" 1 "Low Confidence" 2 "Medium Confidence" 3 "High Confidence";
VAL_ 1041 DRIVER_DOOR 0 "Closed" 1 "Opened";
VAL_ 1041 PASSENGER_DOOR 0 "Closed" 1 "Opened";
VAL_ 1041 PASSENGER_SEATBELT 0 "Unlatched" 1 "Latched";
VAL_ 1041 DRIVER_SEATBELT 0 "Unlatched" 1 "Latched";
VAL_ 1041 DRIVER_REAR_DOOR 0 "Closed" 1 "Opened";
VAL_ 1041 PASSENGER_REAR_DOOR 0 "Closed" 1 "Opened";
VAL_ 1144 DRIVE_MODE2 3 "Set Sport" 1 "Set Normal" 2 "Set Eco";
VAL_ 1240 DISTANCE_UNIT 1 "Miles" 0 "Kilometers";
